[part 2 of 2: packages /CommunicationClusters/BODY3 to /GlobalTimeDomains]
AUTOSAR XML (schema 4-3-0)
# Copyright (c) 2022 Mercedes-Benz AG
package /CommunicationClusters/BODY3  (continued)
  can cluster BODY3: baudrate=250000, protocol-name=CAN, protocol-version=can2.0b  (continued)
    can physical channel BODY3  (continued)
      frame NM_RBTM_FL_ST3: id 0x144201A4, from RBTM_FL, frame-length=8, variation-point=post-build-variant-condition{matching-criterion=Side, value=0}, can-addressing-mode=EXTENDED  # Netzwerk-Management / Network Management
        nm pdu NM_RBTM_FL_ST3: length=8, nm-data-information=true, unused-bit-pattern=0  # STAR3 NM PDU
          signal NM_RBTM_FL_ST3_PNC: start 8, 56 bit, opaque, data-type-policy=OVERRIDE, i-signal-type=ARRAY, init-value=7 x 0, base-type=uint8, transfer-property=PENDING  # PNC_Vector
      frame NM_Dummy_ST3: id 0x14420FFF, to RBTM_FL, frame-length=8, variation-point=post-build-variant-condition{matching-criterion=Side, value=0}, can-addressing-mode=EXTENDED, rx-identifier-range={lower-can-id=339869696, upper-can-id=339873791}  # Netzwerk-Management / Network Management
        nm pdu NM_Dummy_ST3: length=8, nm-data-information=true, unused-bit-pattern=0  # Netzwerk-Management / Network Management
          signal NM_Dummy_ST3_PNC: start 8, 56 bit, opaque, data-type-policy=OVERRIDE, i-signal-type=ARRAY, init-value=7 x 0, base-type=uint8, transfer-property=PENDING  # PNC_Vector
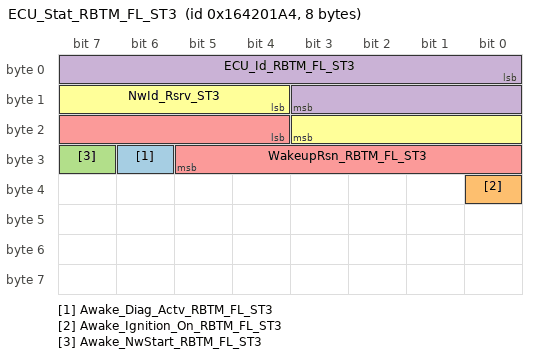
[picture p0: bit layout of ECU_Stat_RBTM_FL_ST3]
      frame ECU_Stat_RBTM_FL_ST3: id 0x164201A4, from RBTM_FL, frame-length=8, variation-point=post-build-variant-condition{matching-criterion=Side, value=0}, can-addressing-mode=EXTENDED  # ECU Status / ECU state
        pdu ECU_Stat_RBTM_FL_ST3: length=8, transmission-mode-true-timing=cyclic-timing={time-offset=0, time-period=1}, unused-bit-pattern=0  # ECU Status / ECU state
          signal Awake_Diag_Actv_RBTM_FL_ST3: start 30, 1 bit, little-endian, data-type-policy=OVERRIDE, i-signal-type=PRIMITIVE, init-value=0, base-type=boolean, transfer-property=PENDING  # Wachhalten für Diagnose aktiv / Stay awake for diagnostics active
          signal Awake_Ignition_On_RBTM_FL_ST3: start 32, 1 bit, little-endian, data-type-policy=OVERRIDE, i-signal-type=PRIMITIVE, init-value=0, base-type=boolean, transfer-property=PENDING  # Wachhalten für Zündung eingeschaltet / Stay awake for ignition on
          signal Awake_NwStart_RBTM_FL_ST3: start 31, 1 bit, little-endian, data-type-policy=OVERRIDE, i-signal-type=PRIMITIVE, init-value=0, base-type=boolean, transfer-property=PENDING  # Wachhalten für Netzwerkstartphase / Stay awake for network startup
          signal ECU_Id_RBTM_FL_ST3: start 0, 12 bit, little-endian, data-type-policy=OVERRIDE, i-signal-type=PRIMITIVE, init-value=420, base-type=uint16, invalid-value=4095, compu-method=c12_0_4094_1_SNA, data-constr=c12_0_4094_1_SNA, transfer-property=PENDING  # ECU-Identifizierungsnummer / ECU identifier
          signal WakeupRsn_RBTM_FL_ST3: start 20, 10 bit, little-endian, data-type-policy=OVERRIDE, i-signal-type=PRIMITIVE, init-value=1023, base-type=uint16, invalid-value=1023, compu-method=c10_WakeupRsn_ST3, data-constr=c10_WakeupRsn_ST3, transfer-property=PENDING  # Weckgrund / Wakeup reason
          signal NwId_Rsrv_ST3: start 12, 8 bit, little-endian, data-type-policy=OVERRIDE, i-signal-type=PRIMITIVE, init-value=0, base-type=uint8, invalid-value=255, compu-method=c08_0_254_1_SNA_255, data-constr=c08_0_254_1_SNA_255, transfer-property=PENDING  # Signal to close the gap in ECU-Stat-PDUs for ECUs w/o NW-ID
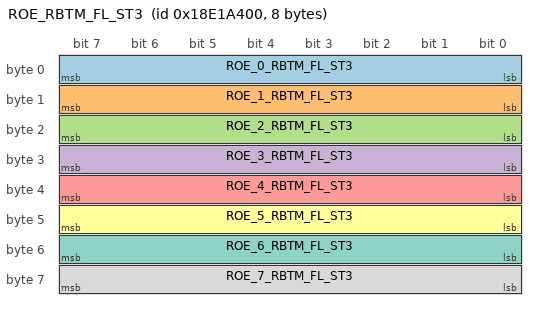
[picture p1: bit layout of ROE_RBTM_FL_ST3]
      frame ROE_RBTM_FL_ST3: id 0x18E1A400, from RBTM_FL, frame-length=8, variation-point=post-build-variant-condition{matching-criterion=Side, value=0}, can-addressing-mode=EXTENDED  # Ereignis-Antwort / Response on Event
        pdu ROE_RBTM_FL_ST3: length=8, minimum-delay=0.2, transmission-mode-true-timing=event-controlled-timing=number-of-repetitions=0, unused-bit-pattern=0  # Ereignis-Antwort / Response on Event
          signal ROE_0_RBTM_FL_ST3: start 0, 8 bit, little-endian, data-type-policy=OVERRIDE, i-signal-type=PRIMITIVE, init-value=0, base-type=uint8, compu-method=c08_ROE_0, data-constr=c08_ROE_0  # Ereignis-Antwort / Response on Event
          signal ROE_1_RBTM_FL_ST3: start 8, 8 bit, little-endian, data-type-policy=OVERRIDE, i-signal-type=PRIMITIVE, init-value=0, base-type=uint8, data-constr=c08_UInt_SNA_na  # Ereignis-Antwort / Response on Event
          signal ROE_2_RBTM_FL_ST3: start 16, 8 bit, little-endian, data-type-policy=OVERRIDE, i-signal-type=PRIMITIVE, init-value=0, base-type=uint8, data-constr=c08_UInt_SNA_na  # Ereignis-Antwort / Response on Event
          signal ROE_3_RBTM_FL_ST3: start 24, 8 bit, little-endian, data-type-policy=OVERRIDE, i-signal-type=PRIMITIVE, init-value=0, base-type=uint8, data-constr=c08_UInt_SNA_na  # Ereignis-Antwort / Response on Event
          signal ROE_4_RBTM_FL_ST3: start 32, 8 bit, little-endian, data-type-policy=OVERRIDE, i-signal-type=PRIMITIVE, init-value=0, base-type=uint8, data-constr=c08_UInt_SNA_na  # Ereignis-Antwort / Response on Event
          signal ROE_5_RBTM_FL_ST3: start 40, 8 bit, little-endian, data-type-policy=OVERRIDE, i-signal-type=PRIMITIVE, init-value=0, base-type=uint8, data-constr=c08_UInt_SNA_na  # Ereignis-Antwort / Response on Event
          signal ROE_6_RBTM_FL_ST3: start 48, 8 bit, little-endian, data-type-policy=OVERRIDE, i-signal-type=PRIMITIVE, init-value=0, base-type=uint8, data-constr=c08_UInt_SNA_na  # Ereignis-Antwort / Response on Event
          signal ROE_7_RBTM_FL_ST3: start 56, 8 bit, little-endian, data-type-policy=OVERRIDE, i-signal-type=PRIMITIVE, init-value=0, base-type=uint8, data-constr=c08_UInt_SNA_na  # Ereignis-Antwort / Response on Event
          mapping ROE_RBTM_FL_ST3_6e0rxnifai2txra0wamb18g4m: i-signal-group=ROE_RBTM_FL_ST3_6e0rxnifai2txra0wamb18g4m, packing-byte-order=little-endian, transfer-property=TRIGGERED
      frame XCP8_Rs_RBTM_FL_ST3: id 0x18E1A408, from RBTM_FL, frame-length=8, variation-point=post-build-variant-condition{matching-criterion=Side, value=0}, can-addressing-mode=EXTENDED
        general purpose i pdu XCP8_Rs_RBTM_FL_ST3: category=XCP, length=8  # XCP-Anforderung / Extended calibration protocol response
      frame XCP8_Rq_RBTM_FL_ST3: id 0x18E1A409, to RBTM_FL, frame-length=8, variation-point=post-build-variant-condition{matching-criterion=Side, value=0}, can-addressing-mode=EXTENDED
        general purpose i pdu XCP8_Rq_RBTM_FL_ST3: category=XCP, length=8  # XCP-Anforderung / Extended calibration protocol request
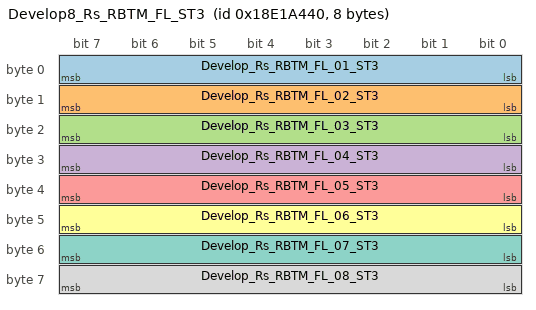
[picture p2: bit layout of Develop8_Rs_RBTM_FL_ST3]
      frame Develop8_Rs_RBTM_FL_ST3: id 0x18E1A440, from RBTM_FL, frame-length=8, variation-point=post-build-variant-condition{matching-criterion=Side, value=0}, can-addressing-mode=EXTENDED  # Development Response
        pdu Develop8_Rs_RBTM_FL_ST3: length=8, minimum-delay=0.02, transmission-mode-true-timing=event-controlled-timing=number-of-repetitions=0, unused-bit-pattern=0  # Development Response
          signal Develop_Rs_RBTM_FL_01_ST3: start 0, 8 bit, little-endian, data-type-policy=OVERRIDE, i-signal-type=PRIMITIVE, init-value=0, base-type=uint8, data-constr=c08_UInt_SNA_na  # Development Response
          signal Develop_Rs_RBTM_FL_02_ST3: start 8, 8 bit, little-endian, data-type-policy=OVERRIDE, i-signal-type=PRIMITIVE, init-value=0, base-type=uint8, data-constr=c08_UInt_SNA_na  # Development Response
          signal Develop_Rs_RBTM_FL_03_ST3: start 16, 8 bit, little-endian, data-type-policy=OVERRIDE, i-signal-type=PRIMITIVE, init-value=0, base-type=uint8, data-constr=c08_UInt_SNA_na  # Development Response
          signal Develop_Rs_RBTM_FL_04_ST3: start 24, 8 bit, little-endian, data-type-policy=OVERRIDE, i-signal-type=PRIMITIVE, init-value=0, base-type=uint8, data-constr=c08_UInt_SNA_na  # Development Response
          signal Develop_Rs_RBTM_FL_05_ST3: start 32, 8 bit, little-endian, data-type-policy=OVERRIDE, i-signal-type=PRIMITIVE, init-value=0, base-type=uint8, data-constr=c08_UInt_SNA_na  # Development Response
          signal Develop_Rs_RBTM_FL_06_ST3: start 40, 8 bit, little-endian, data-type-policy=OVERRIDE, i-signal-type=PRIMITIVE, init-value=0, base-type=uint8, data-constr=c08_UInt_SNA_na  # Development Response
          signal Develop_Rs_RBTM_FL_07_ST3: start 48, 8 bit, little-endian, data-type-policy=OVERRIDE, i-signal-type=PRIMITIVE, init-value=0, base-type=uint8, data-constr=c08_UInt_SNA_na  # Development Response
          signal Develop_Rs_RBTM_FL_08_ST3: start 56, 8 bit, little-endian, data-type-policy=OVERRIDE, i-signal-type=PRIMITIVE, init-value=0, base-type=uint8, data-constr=c08_UInt_SNA_na  # Development Response
          mapping Develop8_Rs_RBTM_FL_ST3_7jg1r8p1skn6yj1t9z2s157vt: i-signal-group=Develop8_Rs_RBTM_FL_ST3_7jg1r8p1skn6yj1t9z2s157vt, packing-byte-order=little-endian, transfer-property=TRIGGERED
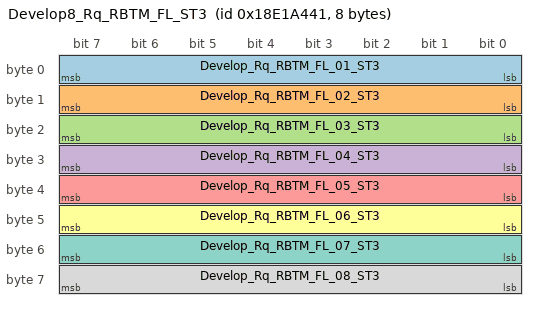
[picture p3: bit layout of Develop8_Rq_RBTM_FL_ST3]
      frame Develop8_Rq_RBTM_FL_ST3: id 0x18E1A441, to RBTM_FL, frame-length=8, variation-point=post-build-variant-condition{matching-criterion=Side, value=0}, can-addressing-mode=EXTENDED  # Development Request
        pdu Develop8_Rq_RBTM_FL_ST3: length=8, minimum-delay=0.02, transmission-mode-true-timing=event-controlled-timing=number-of-repetitions=0, unused-bit-pattern=0  # Development Request
          signal Develop_Rq_RBTM_FL_01_ST3: start 0, 8 bit, little-endian, data-type-policy=OVERRIDE, i-signal-type=PRIMITIVE, init-value=0, base-type=uint8, data-constr=c08_UInt_SNA_na, to RBTM_FL  # Development Request
          signal Develop_Rq_RBTM_FL_02_ST3: start 8, 8 bit, little-endian, data-type-policy=OVERRIDE, i-signal-type=PRIMITIVE, init-value=0, base-type=uint8, data-constr=c08_UInt_SNA_na, to RBTM_FL  # Development Request
          signal Develop_Rq_RBTM_FL_03_ST3: start 16, 8 bit, little-endian, data-type-policy=OVERRIDE, i-signal-type=PRIMITIVE, init-value=0, base-type=uint8, data-constr=c08_UInt_SNA_na, to RBTM_FL  # Development Request
          signal Develop_Rq_RBTM_FL_04_ST3: start 24, 8 bit, little-endian, data-type-policy=OVERRIDE, i-signal-type=PRIMITIVE, init-value=0, base-type=uint8, data-constr=c08_UInt_SNA_na, to RBTM_FL  # Development Request
          signal Develop_Rq_RBTM_FL_05_ST3: start 32, 8 bit, little-endian, data-type-policy=OVERRIDE, i-signal-type=PRIMITIVE, init-value=0, base-type=uint8, data-constr=c08_UInt_SNA_na, to RBTM_FL  # Development Request
          signal Develop_Rq_RBTM_FL_06_ST3: start 40, 8 bit, little-endian, data-type-policy=OVERRIDE, i-signal-type=PRIMITIVE, init-value=0, base-type=uint8, data-constr=c08_UInt_SNA_na, to RBTM_FL  # Development Request
          signal Develop_Rq_RBTM_FL_07_ST3: start 48, 8 bit, little-endian, data-type-policy=OVERRIDE, i-signal-type=PRIMITIVE, init-value=0, base-type=uint8, data-constr=c08_UInt_SNA_na, to RBTM_FL  # Development Request
          signal Develop_Rq_RBTM_FL_08_ST3: start 56, 8 bit, little-endian, data-type-policy=OVERRIDE, i-signal-type=PRIMITIVE, init-value=0, base-type=uint8, data-constr=c08_UInt_SNA_na, to RBTM_FL  # Development Request
          mapping Develop8_Rq_RBTM_FL_ST3_48g6nu8rjjp9s4bhq1x3pz06u: i-signal-group=Develop8_Rq_RBTM_FL_ST3_48g6nu8rjjp9s4bhq1x3pz06u, packing-byte-order=little-endian, transfer-property=TRIGGERED
      frame DIAG_RBTM_FL_03_ExtEth_RS_ST3: id 0x18E1A480, from RBTM_FL, frame-length=8, variation-point=post-build-variant-condition{matching-criterion=Side, value=0}, can-addressing-mode=EXTENDED  # Diagnoseanwort an ExtEth vonRBTM_FL / Diagnostic Response to ExtEth fromRBTM_FL
        n pdu DIAG_RBTM_FL_03_ExtEth_RS_ST3: length=8  # Diagnoseanwort an ExtEth vonRBTM_FL / Diagnostic Response to ExtEth fromRBTM_FL
      frame DIAG_RBTM_FL_03_ExtCAN_RS_ST3: id 0x18E1A481, from RBTM_FL, frame-length=8, variation-point=post-build-variant-condition{matching-criterion=Side, value=0}, can-addressing-mode=EXTENDED  # Diagnoseanwort an ExtCAN vonRBTM_FL / Diagnostic Response to ExtCAN fromRBTM_FL
        n pdu DIAG_RBTM_FL_03_ExtCAN_RS_ST3: length=8  # Diagnoseanwort an ExtCAN vonRBTM_FL / Diagnostic Response to ExtCAN fromRBTM_FL
      frame DIAG_RBTM_FL_03_IntEth_RS_ST3: id 0x18E1A485, from RBTM_FL, frame-length=8, variation-point=post-build-variant-condition{matching-criterion=Side, value=0}, can-addressing-mode=EXTENDED  # Diagnoseanwort an IntEth vonRBTM_FL / Diagnostic Response to IntEth fromRBTM_FL
        n pdu DIAG_RBTM_FL_03_IntEth_RS_ST3: length=8  # Diagnoseanwort an IntEth vonRBTM_FL / Diagnostic Response to IntEth fromRBTM_FL
      frame DIAG_RBTM_FL_03_ExtEth_RQ_ST3: id 0x18E1A488, to RBTM_FL, frame-length=8, variation-point=post-build-variant-condition{matching-criterion=Side, value=0}, can-addressing-mode=EXTENDED  # Diagnoseanfrage vom ExtEth fürRBTM_FL / Diagnostic Request from ExtEth forRBTM_FL
        n pdu DIAG_RBTM_FL_03_ExtEth_RQ_ST3: length=8  # Diagnoseanfrage vom ExtEth fürRBTM_FL / Diagnostic Request from ExtEth forRBTM_FL
      frame DIAG_RBTM_FL_03_ExtCAN_RQ_ST3: id 0x18E1A489, to RBTM_FL, frame-length=8, variation-point=post-build-variant-condition{matching-criterion=Side, value=0}, can-addressing-mode=EXTENDED  # Diagnoseanfrage vom ExtCAN fürRBTM_FL / Diagnostic Request from ExtCAN forRBTM_FL
        n pdu DIAG_RBTM_FL_03_ExtCAN_RQ_ST3: length=8  # Diagnoseanfrage vom ExtCAN fürRBTM_FL / Diagnostic Request from ExtCAN forRBTM_FL
      frame DIAG_RBTM_FL_03_IntEth_RQ_ST3: id 0x18E1A48D, to RBTM_FL, frame-length=8, variation-point=post-build-variant-condition{matching-criterion=Side, value=0}, can-addressing-mode=EXTENDED  # Diagnoseanfrage vom IntEth fürRBTM_FL / Diagnostic Request from IntEth forRBTM_FL
        n pdu DIAG_RBTM_FL_03_IntEth_RQ_ST3: length=8  # Diagnoseanfrage vom IntEth fürRBTM_FL / Diagnostic Request from IntEth forRBTM_FL
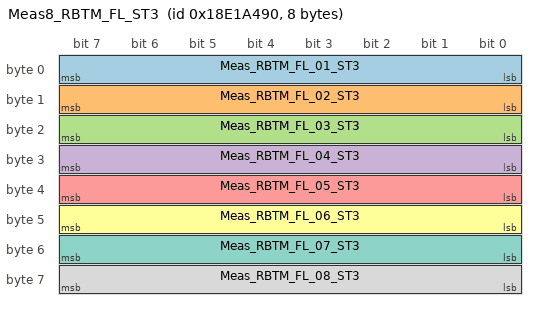
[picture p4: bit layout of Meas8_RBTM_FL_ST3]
      frame Meas8_RBTM_FL_ST3: id 0x18E1A490, from RBTM_FL, frame-length=8, variation-point=post-build-variant-condition{matching-criterion=Side, value=0}, can-addressing-mode=EXTENDED  # Messbotschaft / Measurement
        pdu Meas8_RBTM_FL_ST3: length=8, minimum-delay=0.02, transmission-mode-true-timing=event-controlled-timing=number-of-repetitions=0, unused-bit-pattern=0  # Messbotschaft / Measurement
          signal Meas_RBTM_FL_01_ST3: start 0, 8 bit, little-endian, data-type-policy=OVERRIDE, i-signal-type=PRIMITIVE, init-value=0, base-type=uint8, data-constr=c08_UInt_SNA_na  # Messsignal / Measurement
          signal Meas_RBTM_FL_02_ST3: start 8, 8 bit, little-endian, data-type-policy=OVERRIDE, i-signal-type=PRIMITIVE, init-value=0, base-type=uint8, data-constr=c08_UInt_SNA_na  # Messsignal / Measurement
          signal Meas_RBTM_FL_03_ST3: start 16, 8 bit, little-endian, data-type-policy=OVERRIDE, i-signal-type=PRIMITIVE, init-value=0, base-type=uint8, data-constr=c08_UInt_SNA_na  # Messsignal / Measurement
          signal Meas_RBTM_FL_04_ST3: start 24, 8 bit, little-endian, data-type-policy=OVERRIDE, i-signal-type=PRIMITIVE, init-value=0, base-type=uint8, data-constr=c08_UInt_SNA_na  # Messsignal / Measurement
          signal Meas_RBTM_FL_05_ST3: start 32, 8 bit, little-endian, data-type-policy=OVERRIDE, i-signal-type=PRIMITIVE, init-value=0, base-type=uint8, data-constr=c08_UInt_SNA_na  # Messsignal / Measurement
          signal Meas_RBTM_FL_06_ST3: start 40, 8 bit, little-endian, data-type-policy=OVERRIDE, i-signal-type=PRIMITIVE, init-value=0, base-type=uint8, data-constr=c08_UInt_SNA_na  # Messsignal / Measurement
          signal Meas_RBTM_FL_07_ST3: start 48, 8 bit, little-endian, data-type-policy=OVERRIDE, i-signal-type=PRIMITIVE, init-value=0, base-type=uint8, data-constr=c08_UInt_SNA_na  # Messsignal / Measurement
          signal Meas_RBTM_FL_08_ST3: start 56, 8 bit, little-endian, data-type-policy=OVERRIDE, i-signal-type=PRIMITIVE, init-value=0, base-type=uint8, data-constr=c08_UInt_SNA_na  # Messsignal / Measurement
          mapping Meas8_RBTM_FL_ST3_72jyquhuktrmjm0hkqempja37: i-signal-group=Meas8_RBTM_FL_ST3_72jyquhuktrmjm0hkqempja37, packing-byte-order=little-endian, transfer-property=TRIGGERED
      frame DIAG_RQ_GLOBAL_ExtEth_ST3: id 0x18EEF888, to RBTM_FL, frame-length=8, variation-point=post-build-variant-condition{matching-criterion=Side, value=0}, can-addressing-mode=EXTENDED  # Funktionaler Diagnose-Request vom Off-Board Tester (via Ethernet) / Functional Diagnostic Request from Off-Board Tester (via Ethernet)
        n pdu DIAG_RQ_GLOBAL_ExtEth_ST3: length=8  # Funktionale Diagnoseanfrage (UDS) vom ExtEth / Functional Diagnostic Request (UDS) from ExtEth
      frame DIAG_RQ_GLOBAL_ExtCAN_ST3: id 0x18EEF989, to RBTM_FL, frame-length=8, variation-point=post-build-variant-condition{matching-criterion=Side, value=0}, can-addressing-mode=EXTENDED  # Funktionaler Diagnose-Request vom Off-Board Tester (via CAN) / Functional Diagnostic Request from Off-Board Tester (via CAN)
        n pdu DIAG_RQ_GLOBAL_ExtCAN_ST3: length=8  # Funktionale Diagnoseanfrage (UDS) vom ExtCAN / Functional Diagnostic Request (UDS) from ExtCAN
      frame DIAG_RQ_GLOBAL_IntEth_ST3: id 0x18EF0D8D, to RBTM_FL, frame-length=8, variation-point=post-build-variant-condition{matching-criterion=Side, value=0}, can-addressing-mode=EXTENDED  # Funktionaler Diagnose-Request vom On-Board Tester (via Ethernet) / Functional Diagnostic Request from On-Board Tester (via Ethernet)
        n pdu DIAG_RQ_GLOBAL_IntEth_ST3: length=8  # Funktionale Diagnoseanfrage (UDS) vom IntEth / Functional Diagnostic Request (UDS) from IntEth
      frame GTS_Main_CAN_ST3: id 0x79, to RBTM_FL, frame-length=8, variation-point=post-build-variant-condition{matching-criterion=Side, value=1}, can-addressing-mode=STANDARD  # Status Uhrsynchronisation / Clock synchronisation state
        carries pdu GTS_Main_CAN_ST3: packing-byte-order=big-endian, start-position=7
        general purpose pdu GTS_Main_CAN_ST3: category=GLOBAL_TIME, length=8  # Status Uhrsynchronisation / Clock synchronisation state
      frame Ign_Stat_ST3: id 0x7F, to RBTM_FL, frame-length=8, variation-point=post-build-variant-condition{matching-criterion=Side, value=1}, can-addressing-mode=STANDARD  # Zuendungsstatus / Ignition state
        carries pdu Ign_Stat_ST3_secured: packing-byte-order=little-endian, start-position=0
        secured i pdu Ign_Stat_ST3_secured: length=8, authentication-props=SECOC_AP_CMAC_AES_128_24, freshness-props=SECOC_FP_10000_40_8_true, payload=BODY3/Ign_Stat_ST3_c09z9xhxqu9sge34n30m1bi02, secure-communication-props={authentication-retries=0, data-id=28212, freshness-value-id=1}
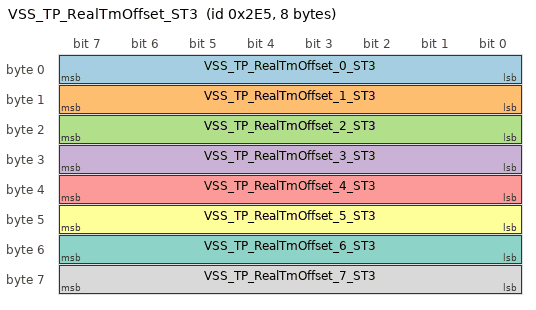
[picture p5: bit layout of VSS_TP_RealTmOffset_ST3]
      frame VSS_TP_RealTmOffset_ST3: id 0x2E5, to RBTM_FL, frame-length=8, variation-point=post-build-variant-condition{matching-criterion=Side, value=1}, can-addressing-mode=STANDARD  # VSS-Transportprotokoll für Echtzeit-Offset / Vehicle Security System Transport Protocol for real time offset broadcast
        carries pdu VSS_TP_RealTmOffset_ST3: packing-byte-order=little-endian, start-position=0
        pdu VSS_TP_RealTmOffset_ST3: length=8, minimum-delay=0.02, transmission-mode-true-timing=event-controlled-timing=number-of-repetitions=0, unused-bit-pattern=255  # VSS-Transportprotokoll für Echtzeit-Offset / Vehicle Security System Transport Protocol for real time offset broadcast
          signal VSS_TP_RealTmOffset_0_ST3: start 0, 8 bit, little-endian, data-type-policy=OVERRIDE, i-signal-type=PRIMITIVE, init-value=255, base-type=uint8, data-constr=c08_UInt_SNA_na, to RBTM_FL  # VSS-Transportprotokoll für Echtzeit-Offset, Byte 0 / Vehicle Security System Transport Protocol for real time offset broadcast, Byte 0
          signal VSS_TP_RealTmOffset_1_ST3: start 8, 8 bit, little-endian, data-type-policy=OVERRIDE, i-signal-type=PRIMITIVE, init-value=255, base-type=uint8, data-constr=c08_UInt_SNA_na, to RBTM_FL  # VSS-Transportprotokoll für Echtzeit-Offset, Byte 1 / Vehicle Security System Transport Protocol for real time offset broadcast, Byte 1
          signal VSS_TP_RealTmOffset_2_ST3: start 16, 8 bit, little-endian, data-type-policy=OVERRIDE, i-signal-type=PRIMITIVE, init-value=255, base-type=uint8, data-constr=c08_UInt_SNA_na, to RBTM_FL  # VSS-Transportprotokoll für Echtzeit-Offset, Byte 2 / Vehicle Security System Transport Protocol for real time offset broadcast, Byte 2
          signal VSS_TP_RealTmOffset_3_ST3: start 24, 8 bit, little-endian, data-type-policy=OVERRIDE, i-signal-type=PRIMITIVE, init-value=255, base-type=uint8, data-constr=c08_UInt_SNA_na, to RBTM_FL  # VSS-Transportprotokoll für Echtzeit-Offset, Byte 3 / Vehicle Security System Transport Protocol for real time offset broadcast, Byte 3
          signal VSS_TP_RealTmOffset_4_ST3: start 32, 8 bit, little-endian, data-type-policy=OVERRIDE, i-signal-type=PRIMITIVE, init-value=255, base-type=uint8, data-constr=c08_UInt_SNA_na, to RBTM_FL  # VSS-Transportprotokoll für Echtzeit-Offset, Byte 4 / Vehicle Security System Transport Protocol for real time offset broadcast, Byte 4
          signal VSS_TP_RealTmOffset_5_ST3: start 40, 8 bit, little-endian, data-type-policy=OVERRIDE, i-signal-type=PRIMITIVE, init-value=255, base-type=uint8, data-constr=c08_UInt_SNA_na, to RBTM_FL  # VSS-Transportprotokoll für Echtzeit-Offset, Byte 5 / Vehicle Security System Transport Protocol for real time offset broadcast, Byte 5
          signal VSS_TP_RealTmOffset_6_ST3: start 48, 8 bit, little-endian, data-type-policy=OVERRIDE, i-signal-type=PRIMITIVE, init-value=255, base-type=uint8, data-constr=c08_UInt_SNA_na, to RBTM_FL  # VSS-Transportprotokoll für Echtzeit-Offset, Byte 6 / Vehicle Security System Transport Protocol for real time offset broadcast, Byte 6
          signal VSS_TP_RealTmOffset_7_ST3: start 56, 8 bit, little-endian, data-type-policy=OVERRIDE, i-signal-type=PRIMITIVE, init-value=255, base-type=uint8, data-constr=c08_UInt_SNA_na, to RBTM_FL  # VSS-Transportprotokoll für Echtzeit-Offset, Byte 7 / Vehicle Security System Transport Protocol for real time offset broadcast, Byte 7
          mapping VSS_TP_RealTmOffset_ST3_1t7vc44gftc0wv35k5kgc2in9: i-signal-group=VSS_TP_RealTmOffset_ST3_1t7vc44gftc0wv35k5kgc2in9, packing-byte-order=little-endian, transfer-property=TRIGGERED
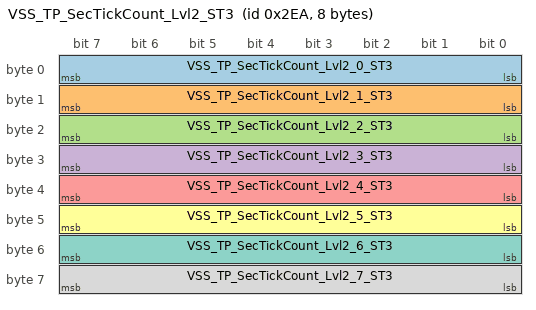
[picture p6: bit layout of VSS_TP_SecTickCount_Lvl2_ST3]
      frame VSS_TP_SecTickCount_Lvl2_ST3: id 0x2EA, to RBTM_FL, frame-length=8, variation-point=post-build-variant-condition{matching-criterion=Side, value=1}, can-addressing-mode=STANDARD  # VSS-Transportprotokoll für sichere Zeit Stufe 2 / Vehicle Security System Transport Protocol for secure tick count level #2
        carries pdu VSS_TP_SecTickCount_Lvl2_ST3: packing-byte-order=little-endian, start-position=0
        pdu VSS_TP_SecTickCount_Lvl2_ST3: length=8, minimum-delay=0.02, transmission-mode-true-timing=event-controlled-timing=number-of-repetitions=0, unused-bit-pattern=255  # VSS-Transportprotokoll für sichere Zeit Stufe 2 / Vehicle Security System Transport Protocol for secure tick count level #2
          signal VSS_TP_SecTickCount_Lvl2_0_ST3: start 0, 8 bit, little-endian, data-type-policy=OVERRIDE, i-signal-type=PRIMITIVE, init-value=255, base-type=uint8, data-constr=c08_UInt_SNA_na, to RBTM_FL  # VSS-Transportprotokoll für sichere Zeit Stufe 2, Byte 0 / Vehicle Security System Transport Protocol for secure tick count level #2, Byte 0
          signal VSS_TP_SecTickCount_Lvl2_1_ST3: start 8, 8 bit, little-endian, data-type-policy=OVERRIDE, i-signal-type=PRIMITIVE, init-value=255, base-type=uint8, data-constr=c08_UInt_SNA_na, to RBTM_FL  # VSS-Transportprotokoll für sichere Zeit Stufe 2, Byte 1 / Vehicle Security System Transport Protocol for secure tick count level #2, Byte 1
          signal VSS_TP_SecTickCount_Lvl2_2_ST3: start 16, 8 bit, little-endian, data-type-policy=OVERRIDE, i-signal-type=PRIMITIVE, init-value=255, base-type=uint8, data-constr=c08_UInt_SNA_na, to RBTM_FL  # VSS-Transportprotokoll für sichere Zeit Stufe 2, Byte 2 / Vehicle Security System Transport Protocol for secure tick count level #2, Byte 2
          signal VSS_TP_SecTickCount_Lvl2_3_ST3: start 24, 8 bit, little-endian, data-type-policy=OVERRIDE, i-signal-type=PRIMITIVE, init-value=255, base-type=uint8, data-constr=c08_UInt_SNA_na, to RBTM_FL  # VSS-Transportprotokoll für sichere Zeit Stufe 2, Byte 3 / Vehicle Security System Transport Protocol for secure tick count level #2, Byte 3
          signal VSS_TP_SecTickCount_Lvl2_4_ST3: start 32, 8 bit, little-endian, data-type-policy=OVERRIDE, i-signal-type=PRIMITIVE, init-value=255, base-type=uint8, data-constr=c08_UInt_SNA_na, to RBTM_FL  # VSS-Transportprotokoll für sichere Zeit Stufe 2, Byte 4 / Vehicle Security System Transport Protocol for secure tick count level #2, Byte 4
          signal VSS_TP_SecTickCount_Lvl2_5_ST3: start 40, 8 bit, little-endian, data-type-policy=OVERRIDE, i-signal-type=PRIMITIVE, init-value=255, base-type=uint8, data-constr=c08_UInt_SNA_na, to RBTM_FL  # VSS-Transportprotokoll für sichere Zeit Stufe 2, Byte 5 / Vehicle Security System Transport Protocol for secure tick count level #2, Byte 5
          signal VSS_TP_SecTickCount_Lvl2_6_ST3: start 48, 8 bit, little-endian, data-type-policy=OVERRIDE, i-signal-type=PRIMITIVE, init-value=255, base-type=uint8, data-constr=c08_UInt_SNA_na, to RBTM_FL  # VSS-Transportprotokoll für sichere Zeit Stufe 2, Byte 6 / Vehicle Security System Transport Protocol for secure tick count level #2, Byte 6
          signal VSS_TP_SecTickCount_Lvl2_7_ST3: start 56, 8 bit, little-endian, data-type-policy=OVERRIDE, i-signal-type=PRIMITIVE, init-value=255, base-type=uint8, data-constr=c08_UInt_SNA_na, to RBTM_FL  # VSS-Transportprotokoll für sichere Zeit Stufe 2, Byte 7 / Vehicle Security System Transport Protocol for secure tick count level #2, Byte 7
          mapping VSS_TP_SecTickCount_Lvl2_ST3_9eubq13iosat764o0lqh5xb6r: i-signal-group=VSS_TP_SecTickCount_Lvl2_ST3_9eubq13iosat764o0lqh5xb6r, packing-byte-order=little-endian, transfer-property=TRIGGERED
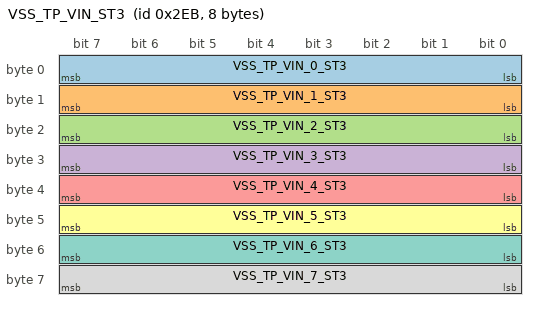
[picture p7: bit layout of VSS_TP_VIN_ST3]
      frame VSS_TP_VIN_ST3: id 0x2EB, to RBTM_FL, frame-length=8, variation-point=post-build-variant-condition{matching-criterion=Side, value=1}, can-addressing-mode=STANDARD  # VSS-Transportprotokoll für Fahrzeugidentifikationsnummer / Vehicle Security System Transport Protocol for Vehicle Identification Number
        carries pdu VSS_TP_VIN_ST3: packing-byte-order=little-endian, start-position=0
        pdu VSS_TP_VIN_ST3: length=8, minimum-delay=0.02, transmission-mode-true-timing=event-controlled-timing=number-of-repetitions=0, unused-bit-pattern=255  # VSS-Transportprotokoll für Fahrzeugidentifikationsnummer / Vehicle Security System Transport Protocol for Vehicle Identification Number
          signal VSS_TP_VIN_0_ST3: start 0, 8 bit, little-endian, data-type-policy=OVERRIDE, i-signal-type=PRIMITIVE, init-value=63, base-type=uint8, data-constr=c08_UInt_SNA_na, to RBTM_FL  # VSS-Transportprotokoll für Fahrzeugidentifikationsnummer, Byte 0 / Vehicle Security System Transport Protocol for Vehicle Identification Number, Byte 0
          signal VSS_TP_VIN_1_ST3: start 8, 8 bit, little-endian, data-type-policy=OVERRIDE, i-signal-type=PRIMITIVE, init-value=63, base-type=uint8, data-constr=c08_UInt_SNA_na, to RBTM_FL  # VSS-Transportprotokoll für Fahrzeugidentifikationsnummer, Byte 1 / Vehicle Security System Transport Protocol for Vehicle Identification Number, Byte 1
          signal VSS_TP_VIN_2_ST3: start 16, 8 bit, little-endian, data-type-policy=OVERRIDE, i-signal-type=PRIMITIVE, init-value=63, base-type=uint8, data-constr=c08_UInt_SNA_na, to RBTM_FL  # VSS-Transportprotokoll für Fahrzeugidentifikationsnummer, Byte 2 / Vehicle Security System Transport Protocol for Vehicle Identification Number, Byte 2
          signal VSS_TP_VIN_3_ST3: start 24, 8 bit, little-endian, data-type-policy=OVERRIDE, i-signal-type=PRIMITIVE, init-value=63, base-type=uint8, data-constr=c08_UInt_SNA_na, to RBTM_FL  # VSS-Transportprotokoll für Fahrzeugidentifikationsnummer, Byte 3 / Vehicle Security System Transport Protocol for Vehicle Identification Number, Byte 3
          signal VSS_TP_VIN_4_ST3: start 32, 8 bit, little-endian, data-type-policy=OVERRIDE, i-signal-type=PRIMITIVE, init-value=63, base-type=uint8, data-constr=c08_UInt_SNA_na, to RBTM_FL  # VSS-Transportprotokoll für Fahrzeugidentifikationsnummer, Byte 4 / Vehicle Security System Transport Protocol for Vehicle Identification Number, Byte 4
          signal VSS_TP_VIN_5_ST3: start 40, 8 bit, little-endian, data-type-policy=OVERRIDE, i-signal-type=PRIMITIVE, init-value=63, base-type=uint8, data-constr=c08_UInt_SNA_na, to RBTM_FL  # VSS-Transportprotokoll für Fahrzeugidentifikationsnummer, Byte 5 / Vehicle Security System Transport Protocol for Vehicle Identification Number, Byte 5
          signal VSS_TP_VIN_6_ST3: start 48, 8 bit, little-endian, data-type-policy=OVERRIDE, i-signal-type=PRIMITIVE, init-value=63, base-type=uint8, data-constr=c08_UInt_SNA_na, to RBTM_FL  # VSS-Transportprotokoll für Fahrzeugidentifikationsnummer, Byte 6 / Vehicle Security System Transport Protocol for Vehicle Identification Number, Byte 6
          signal VSS_TP_VIN_7_ST3: start 56, 8 bit, little-endian, data-type-policy=OVERRIDE, i-signal-type=PRIMITIVE, init-value=63, base-type=uint8, data-constr=c08_UInt_SNA_na, to RBTM_FL  # VSS-Transportprotokoll für Fahrzeugidentifikationsnummer, Byte 7 / Vehicle Security System Transport Protocol for Vehicle Identification Number, Byte 7
          mapping VSS_TP_VIN_ST3_bz1xsv84cxzl09j028gn39p69: i-signal-group=VSS_TP_VIN_ST3_bz1xsv84cxzl09j028gn39p69, packing-byte-order=little-endian, transfer-property=TRIGGERED
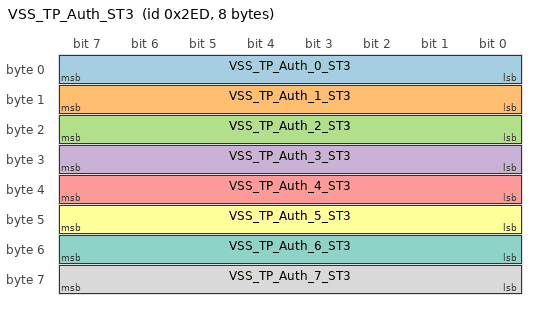
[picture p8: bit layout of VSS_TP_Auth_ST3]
      frame VSS_TP_Auth_ST3: id 0x2ED, to RBTM_FL, frame-length=8, variation-point=post-build-variant-condition{matching-criterion=Side, value=1}, can-addressing-mode=STANDARD  # VSS-Transportprotokoll für Authentifizierung / Vehicle Security System Transport Protocol for authentication broadcast
        carries pdu VSS_TP_Auth_ST3: packing-byte-order=little-endian, start-position=0
        pdu VSS_TP_Auth_ST3: length=8, minimum-delay=0.02, transmission-mode-true-timing=event-controlled-timing=number-of-repetitions=0, unused-bit-pattern=255  # VSS-Transportprotokoll für Authentifizierung / Vehicle Security System Transport Protocol for authentication broadcast
          signal VSS_TP_Auth_0_ST3: start 0, 8 bit, little-endian, data-type-policy=OVERRIDE, i-signal-type=PRIMITIVE, init-value=255, base-type=uint8, data-constr=c08_UInt_SNA_na, to RBTM_FL  # VSS-Transportprotokoll für Authentifizierung, Byte 0 / Vehicle Security System Transport Protocol for authentication broadcast, Byte 0
          signal VSS_TP_Auth_1_ST3: start 8, 8 bit, little-endian, data-type-policy=OVERRIDE, i-signal-type=PRIMITIVE, init-value=255, base-type=uint8, data-constr=c08_UInt_SNA_na, to RBTM_FL  # VSS-Transportprotokoll für Authentifizierung, Byte 1 / Vehicle Security System Transport Protocol for authentication broadcast, Byte 1
          signal VSS_TP_Auth_2_ST3: start 16, 8 bit, little-endian, data-type-policy=OVERRIDE, i-signal-type=PRIMITIVE, init-value=255, base-type=uint8, data-constr=c08_UInt_SNA_na, to RBTM_FL  # VSS-Transportprotokoll für Authentifizierung, Byte 2 / Vehicle Security System Transport Protocol for authentication broadcast, Byte 2
          signal VSS_TP_Auth_3_ST3: start 24, 8 bit, little-endian, data-type-policy=OVERRIDE, i-signal-type=PRIMITIVE, init-value=255, base-type=uint8, data-constr=c08_UInt_SNA_na, to RBTM_FL  # VSS-Transportprotokoll für Authentifizierung, Byte 3 / Vehicle Security System Transport Protocol for authentication broadcast, Byte 3
          signal VSS_TP_Auth_4_ST3: start 32, 8 bit, little-endian, data-type-policy=OVERRIDE, i-signal-type=PRIMITIVE, init-value=255, base-type=uint8, data-constr=c08_UInt_SNA_na, to RBTM_FL  # VSS-Transportprotokoll für Authentifizierung, Byte 4 / Vehicle Security System Transport Protocol for authentication broadcast, Byte 4
          signal VSS_TP_Auth_5_ST3: start 40, 8 bit, little-endian, data-type-policy=OVERRIDE, i-signal-type=PRIMITIVE, init-value=255, base-type=uint8, data-constr=c08_UInt_SNA_na, to RBTM_FL  # VSS-Transportprotokoll für Authentifizierung, Byte 5 / Vehicle Security System Transport Protocol for authentication broadcast, Byte 5
          signal VSS_TP_Auth_6_ST3: start 48, 8 bit, little-endian, data-type-policy=OVERRIDE, i-signal-type=PRIMITIVE, init-value=255, base-type=uint8, data-constr=c08_UInt_SNA_na, to RBTM_FL  # VSS-Transportprotokoll für Authentifizierung, Byte 6 / Vehicle Security System Transport Protocol for authentication broadcast, Byte 6
          signal VSS_TP_Auth_7_ST3: start 56, 8 bit, little-endian, data-type-policy=OVERRIDE, i-signal-type=PRIMITIVE, init-value=255, base-type=uint8, data-constr=c08_UInt_SNA_na, to RBTM_FL  # VSS-Transportprotokoll für Authentifizierung, Byte 7 / Vehicle Security System Transport Protocol for authentication broadcast, Byte 7
          mapping VSS_TP_Auth_ST3_6j4id7sghlvlbroli4wjozjik: i-signal-group=VSS_TP_Auth_ST3_6j4id7sghlvlbroli4wjozjik, packing-byte-order=little-endian, transfer-property=TRIGGERED
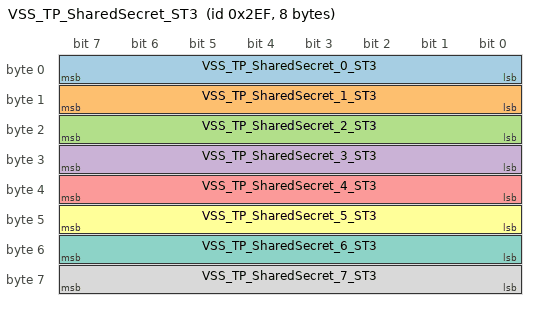
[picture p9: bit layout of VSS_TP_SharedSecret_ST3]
      frame VSS_TP_SharedSecret_ST3: id 0x2EF, to RBTM_FL, frame-length=8, variation-point=post-build-variant-condition{matching-criterion=Side, value=1}, can-addressing-mode=STANDARD  # VSS-Transportprotokoll für gemeinsames Geheimnis / Vehicle Security System Transport Protocol for shared secret broadcast
        carries pdu VSS_TP_SharedSecret_ST3: packing-byte-order=little-endian, start-position=0
        pdu VSS_TP_SharedSecret_ST3: length=8, minimum-delay=0.02, transmission-mode-true-timing=event-controlled-timing=number-of-repetitions=0, unused-bit-pattern=255  # VSS-Transportprotokoll für gemeinsames Geheimnis / Vehicle Security System Transport Protocol for shared secret broadcast
          signal VSS_TP_SharedSecret_0_ST3: start 0, 8 bit, little-endian, data-type-policy=OVERRIDE, i-signal-type=PRIMITIVE, init-value=255, base-type=uint8, data-constr=c08_UInt_SNA_na, to RBTM_FL  # VSS-Transportprotokoll für gemeinsames Geheimnis, Byte 0 / Vehicle Security System Transport Protocol for shared secret broadcast, Byte 0
          signal VSS_TP_SharedSecret_1_ST3: start 8, 8 bit, little-endian, data-type-policy=OVERRIDE, i-signal-type=PRIMITIVE, init-value=255, base-type=uint8, data-constr=c08_UInt_SNA_na, to RBTM_FL  # VSS-Transportprotokoll für gemeinsames Geheimnis, Byte 1 / Vehicle Security System Transport Protocol for shared secret broadcast, Byte 1
          signal VSS_TP_SharedSecret_2_ST3: start 16, 8 bit, little-endian, data-type-policy=OVERRIDE, i-signal-type=PRIMITIVE, init-value=255, base-type=uint8, data-constr=c08_UInt_SNA_na, to RBTM_FL  # VSS-Transportprotokoll für gemeinsames Geheimnis, Byte 2 / Vehicle Security System Transport Protocol for shared secret broadcast, Byte 2
          signal VSS_TP_SharedSecret_3_ST3: start 24, 8 bit, little-endian, data-type-policy=OVERRIDE, i-signal-type=PRIMITIVE, init-value=255, base-type=uint8, data-constr=c08_UInt_SNA_na, to RBTM_FL  # VSS-Transportprotokoll für gemeinsames Geheimnis, Byte 3 / Vehicle Security System Transport Protocol for shared secret broadcast, Byte 3
          signal VSS_TP_SharedSecret_4_ST3: start 32, 8 bit, little-endian, data-type-policy=OVERRIDE, i-signal-type=PRIMITIVE, init-value=255, base-type=uint8, data-constr=c08_UInt_SNA_na, to RBTM_FL  # VSS-Transportprotokoll für gemeinsames Geheimnis, Byte 4 / Vehicle Security System Transport Protocol for shared secret broadcast, Byte 4
          signal VSS_TP_SharedSecret_5_ST3: start 40, 8 bit, little-endian, data-type-policy=OVERRIDE, i-signal-type=PRIMITIVE, init-value=255, base-type=uint8, data-constr=c08_UInt_SNA_na, to RBTM_FL  # VSS-Transportprotokoll für gemeinsames Geheimnis, Byte 5 / Vehicle Security System Transport Protocol for shared secret broadcast, Byte 5
          signal VSS_TP_SharedSecret_6_ST3: start 48, 8 bit, little-endian, data-type-policy=OVERRIDE, i-signal-type=PRIMITIVE, init-value=255, base-type=uint8, data-constr=c08_UInt_SNA_na, to RBTM_FL  # VSS-Transportprotokoll für gemeinsames Geheimnis, Byte 6 / Vehicle Security System Transport Protocol for shared secret broadcast, Byte 6
          signal VSS_TP_SharedSecret_7_ST3: start 56, 8 bit, little-endian, data-type-policy=OVERRIDE, i-signal-type=PRIMITIVE, init-value=255, base-type=uint8, data-constr=c08_UInt_SNA_na, to RBTM_FL  # VSS-Transportprotokoll für gemeinsames Geheimnis, Byte 7 / Vehicle Security System Transport Protocol for shared secret broadcast, Byte 7
          mapping VSS_TP_SharedSecret_ST3_8pj4t8t4rm3tw3pk5hj7vonti: i-signal-group=VSS_TP_SharedSecret_ST3_8pj4t8t4rm3tw3pk5hj7vonti, packing-byte-order=little-endian, transfer-property=TRIGGERED
      frame PT4_PTCoor9_d1_BC_F_ST3: id 0x304, to RBTM_FL, frame-length=1, variation-point=post-build-variant-condition{matching-criterion=Side, value=1}, can-addressing-mode=STANDARD  # PT4 PT Coor 9 ST3 - Degraded PDU
        carries pdu PT4_PTCoor9_d1_BC_F_ST3: packing-byte-order=little-endian, start-position=0
        pdu PT4_PTCoor9_d1_BC_F_ST3: length=1, minimum-delay=0.02, transmission-mode-true-timing={cyclic-timing={time-offset=0.005, time-period=1}, event-controlled-timing=number-of-repetitions=0}, unused-bit-pattern=255  # PT4 PT Coor 9 ST3 - Degraded PDU
          signal PT4_PTCoor_Accel_Md_ST3: start 0, 3 bit, little-endian, data-type-policy=OVERRIDE, i-signal-type=PRIMITIVE, init-value=7, base-type=uint8, invalid-value=7, compu-method=c03_Accel_Md_ST3, data-constr=c03_Accel_Md_ST3, to RBTM_FL(timeout 5.1 s)  # Aktueller Beschleunigungsmodus(Nur in AMG Modellen verfügbar) / Acceleration Modes(Only provided in AMG models)
          mapping PT4_PTCoor9_Pr5_ST3_6r95o81sst3tk9w2lzz600cw3: i-signal-group=PT4_PTCoor9_Pr5_ST3_6r95o81sst3tk9w2lzz600cw3, packing-byte-order=little-endian, transfer-property=TRIGGERED-ON-CHANGE, update-indication-bit-position=7
      frame SBeltTens_SP_Lvl_ST3: id 0x30E, to RBTM_FL, frame-length=8, variation-point=post-build-variant-condition{matching-criterion=Side, value=1}, can-addressing-mode=STANDARD  # Seat Belt Tensioner SP Lvl ST3
        carries pdu SBeltTens_SP_Lvl_ST3: packing-byte-order=little-endian, start-position=0
        pdu SBeltTens_SP_Lvl_ST3: length=8, minimum-delay=0.02, transmission-mode-true-timing={cyclic-timing={time-offset=0.08, time-period=0.2}, event-controlled-timing=number-of-repetitions=0}, unused-bit-pattern=255  # Seat Belt Tensioner SP Lvl ST3
          signal CRC_SBeltTens_SP_Lvl_Pr5_ST3: start 0, 16 bit, little-endian, data-type-policy=OVERRIDE, i-signal-type=PRIMITIVE, init-value=10339, base-type=uint16, data-constr=c16_CRC_woSNA, transfer-property=PENDING, to RBTM_FL(timeout 2 s)  # CRC-Checksumme der Signal Gruppe gemäß AUTOSAR Profil 5 / CRC-checksum of signal group according to AUTOSAR Profile 5
          signal RBTMFL_SP_Lvl_Rq_ST35: start 24, 6 bit, little-endian, data-type-policy=OVERRIDE, i-signal-type=PRIMITIVE, init-value=0, base-type=uint8, invalid-value=63, compu-method=c06_RBTM_LVL_Rq, data-constr=c06_RBTM_LVL_Rq, transfer-property=TRIGGERED-ON-CHANGE, variation-point=post-build-variant-condition{matching-criterion=Side, value=0}, to RBTM_FL(timeout 2 s) RBTM_FL  # Straffprofil Anforderung durch Seatbelt Service Provider vorne links / Tensioning profile request from Seatbelt Service Provider front left
          signal SQC_SBeltTens_SP_Lvl_Pr5_ST3: start 16, 8 bit, little-endian, data-type-policy=OVERRIDE, i-signal-type=PRIMITIVE, init-value=0, base-type=uint8, compu-method=none_1_0, data-constr=c08_0_255_1_SNA_na, transfer-property=PENDING, to RBTM_FL(timeout 2 s)  # Sequenzzähler / Sequence counter
          signal RBTMFR_SP_Lvl_Rq_ST35: start 30, 6 bit, little-endian, data-type-policy=OVERRIDE, i-signal-type=PRIMITIVE, init-value=0, base-type=uint8, invalid-value=63, compu-method=c06_RBTM_LVL_Rq, data-constr=c06_RBTM_LVL_Rq, transfer-property=PENDING, variation-point=post-build-variant-condition{matching-criterion=Side, value=0}, to RBTM_FL RBTM_FL(timeout 2 s)  # Straffprofil Anforderung durch Seatbelt Service Provider vorne rechts / Tensioning profile request from Seatbelt Service Provider front right
          signal Rsrv0_SBeltTens_SP_Lvl_Pr5_ST3: start 36, 4 bit, little-endian, data-type-policy=OVERRIDE, i-signal-type=PRIMITIVE, init-value=15, base-type=uint8, invalid-value=15, data-constr=Rsrv04, transfer-property=PENDING, to RBTM_FL  # Reserviert für zukünftige Verwendung / Reserved for future use
          mapping SBeltTens_SP_Lvl_Pr5_ST3_4tqpkri37441o5ht9g9ekmyzh: i-signal-group=SBeltTens_SP_Lvl_Pr5_ST3_4tqpkri37441o5ht9g9ekmyzh, packing-byte-order=little-endian, transfer-property=TRIGGERED-ON-CHANGE
          signal RBTMFR_SP_Lvl_Rq_ST35: start 30, 6 bit, little-endian, data-type-policy=OVERRIDE, i-signal-type=PRIMITIVE, init-value=0, base-type=uint8, invalid-value=63, compu-method=c06_RBTM_LVL_Rq, data-constr=c06_RBTM_LVL_Rq, transfer-property=TRIGGERED-ON-CHANGE, variation-point=post-build-variant-condition{matching-criterion=Side, value=1}, to RBTM_FL RBTM_FL(timeout 2 s)  # Straffprofil Anforderung durch Seatbelt Service Provider vorne rechts / Tensioning profile request from Seatbelt Service Provider front right
          signal RBTMFL_SP_Lvl_Rq_ST35: start 24, 6 bit, little-endian, data-type-policy=OVERRIDE, i-signal-type=PRIMITIVE, init-value=0, base-type=uint8, invalid-value=63, compu-method=c06_RBTM_LVL_Rq, data-constr=c06_RBTM_LVL_Rq, transfer-property=PENDING, variation-point=post-build-variant-condition{matching-criterion=Side, value=1}, to RBTM_FL(timeout 2 s) RBTM_FL  # Straffprofil Anforderung durch Seatbelt Service Provider vorne links / Tensioning profile request from Seatbelt Service Provider front left
      frame RBTM_FR_Tens_ST3: id 0x310, from RBTM_FL, frame-length=8, variation-point=post-build-variant-condition{matching-criterion=Side, value=1}, can-addressing-mode=STANDARD  # RBTM Vorne Rechts Tens ST3 / RBTM Front Right Tens ST3
        pdu RBTM_FR_Tens_ST3: length=8, minimum-delay=0.02, transmission-mode-true-timing={cyclic-timing={time-offset=0.005, time-period=0.5}, event-controlled-timing=number-of-repetitions=0}, unused-bit-pattern=255  # RBTM Vorne Rechts Tens ST3 / RBTM Front Right Tens ST3
          signal RBTMFR_Actv_Lvl_ST35: start 10, 6 bit, little-endian, data-type-policy=OVERRIDE, i-signal-type=PRIMITIVE, init-value=0, base-type=uint8, invalid-value=63, compu-method=c06_RBTM_Lvl_Stat, data-constr=c06_RBTM_Lvl_Stat, transfer-property=TRIGGERED-ON-CHANGE  # aktives Straffprofil vorne rechts / active seatbelt tensioning profile front right
          signal RBTMFR_SP_ActvClient_ST35: start 16, 4 bit, little-endian, data-type-policy=OVERRIDE, i-signal-type=PRIMITIVE, init-value=0, base-type=uint8, invalid-value=15, compu-method=c04_RBTM_ActvClient, data-constr=c04_RBTM_ActvClient, transfer-property=TRIGGERED-ON-CHANGE  # Anforderungsquelle aktive Gurtstraffung vorne rechts / Active seatbelt tensioning request source front right
          signal RBTMFR_SP_FctPrecond_Stat_ST35: start 0, 10 bit, little-endian, data-type-policy=OVERRIDE, i-signal-type=PRIMITIVE, init-value=0, base-type=uint16, compu-method=c10_RBTM_Fct_Precond, transfer-property=TRIGGERED-ON-CHANGE  # Nicht erfüllten Funktionsbedingungen für rev. Gurtstraffung vorne rechts / List of unfulfilled preconditions for rev. seatbelt tensioning front right
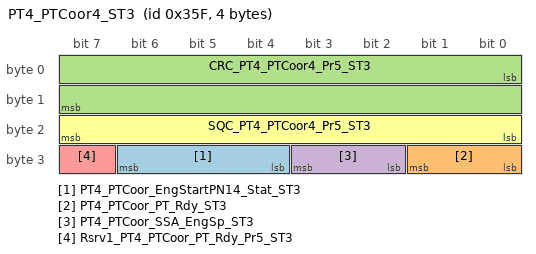
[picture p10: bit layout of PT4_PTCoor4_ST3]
      frame PT4_PTCoor4_ST3: id 0x35F, to RBTM_FL, frame-length=4, variation-point=post-build-variant-condition{matching-criterion=Side, value=1}, can-addressing-mode=STANDARD
        carries pdu PT4_PTCoor4_ST3: packing-byte-order=little-endian, start-position=0
        pdu PT4_PTCoor4_ST3: length=4, minimum-delay=0.01, transmission-mode-true-timing={cyclic-timing=time-period=0.1, event-controlled-timing=number-of-repetitions=0}, unused-bit-pattern=255
          signal PT4_PTCoor_EngStartPN14_Stat_ST3: start 28, 3 bit, little-endian, data-type-policy=OVERRIDE, i-signal-type=PRIMITIVE, init-value=0, base-type=uint8, invalid-value=7, compu-method=c03_EngStartPN14_Stat, data-constr=c03_EngStartPN14_Stat, to RBTM_FL(timeout 1.05 s)  # Status PN14 bei Motorstart / PT4 Engine Start PN14 State
          signal PT4_PTCoor_PT_Rdy_ST3: start 24, 2 bit, little-endian, data-type-policy=OVERRIDE, i-signal-type=PRIMITIVE, init-value=0, base-type=uint8, invalid-value=3, compu-method=c02_PT_Rdy_V2, data-constr=c02_PT_Rdy_V2, to RBTM_FL(timeout 1.05 s)  # Antrieb bereit / Powertrain ready
          signal CRC_PT4_PTCoor4_Pr5_ST3: start 0, 16 bit, little-endian, data-type-policy=OVERRIDE, i-signal-type=PRIMITIVE, init-value=4203, base-type=uint16, data-constr=c16_CRC_woSNA, transfer-property=PENDING  # CRC-Checksumme der Signal Gruppe gemäß AUTOSAR Profil 5 / CRC-checksum of signal group according to AUTOSAR Profile 5
          signal PT4_PTCoor_SSA_EngSp_ST3: start 26, 2 bit, little-endian, data-type-policy=OVERRIDE, i-signal-type=PRIMITIVE, init-value=3, base-type=uint8, invalid-value=3, compu-method=c02_Ndef_False_True_ST3, data-constr=c02_Ndef_False_True_ST3, transfer-property=PENDING  # ASS Motorstopp / Stop/start automatic has engine stopped
          signal Rsrv1_PT4_PTCoor_PT_Rdy_Pr5_ST3: start 31, 1 bit, little-endian, data-type-policy=OVERRIDE, i-signal-type=PRIMITIVE, init-value=1, base-type=uint8, invalid-value=1, data-constr=Rsrv01, transfer-property=PENDING  # Reserviert für zukünftige Verwendung / Reserved for future use
          signal SQC_PT4_PTCoor4_Pr5_ST3: start 16, 8 bit, little-endian, data-type-policy=OVERRIDE, i-signal-type=PRIMITIVE, init-value=0, base-type=uint8, compu-method=none_1_0, data-constr=c08_0_255_1_SNA_na, transfer-property=PENDING  # Sequenzzähler / Sequence counter
          mapping PT4_PTCoor4_Pr5_ST3_af4fxb1ykieox3itqdfzs0kpb: i-signal-group=PT4_PTCoor4_Pr5_ST3_af4fxb1ykieox3itqdfzs0kpb, packing-byte-order=little-endian, transfer-property=TRIGGERED-ON-CHANGE
      frame Impact2_ST3: id 0x463, to RBTM_FL, frame-length=8, variation-point=post-build-variant-condition{matching-criterion=Side, value=1}, can-addressing-mode=STANDARD  # ORC Impact 2 ST3
        carries pdu Impact2_ST3_secured: packing-byte-order=little-endian, start-position=0
        secured i pdu Impact2_ST3_secured: length=8, authentication-props=SECOC_AP_CMAC_AES_128_24, freshness-props=SECOC_FP_10000_40_8_true, payload=BODY3/Impact2_ST3_tiwfvn1jg3r3k32jv8naa5uv, secure-communication-props={authentication-retries=0, data-id=27103, freshness-value-id=1}
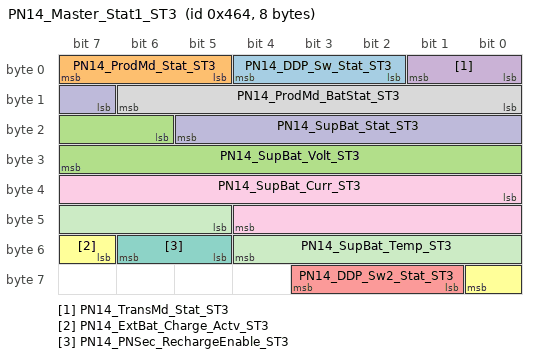
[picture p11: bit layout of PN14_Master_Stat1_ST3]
      frame PN14_Master_Stat1_ST3: id 0x464, to RBTM_FL, frame-length=8, variation-point=post-build-variant-condition{matching-criterion=Side, value=1}, can-addressing-mode=STANDARD  # Status 12V Bordnetz Master / Powernetwork 12V master state
        carries pdu PN14_Master_Stat1_ST3: packing-byte-order=little-endian, start-position=0
        pdu PN14_Master_Stat1_ST3: length=8, transmission-mode-true-timing=cyclic-timing=time-period=0.2, unused-bit-pattern=255  # Status 12V Bordnetz Master / Powernetwork 12V master state
          signal PN14_DDP_Sw_Stat_ST3: start 2, 3 bit, little-endian, data-type-policy=OVERRIDE, i-signal-type=PRIMITIVE, init-value=0, base-type=uint8, invalid-value=7, compu-method=c03_PN14_TDP_Sw_Stat, data-constr=c03_PN14_TDP_Sw_Stat, transfer-property=PENDING, to RBTM_FL  # Schalterstatus Tiefentladeschutz / Deep discharge protection switch state
          signal PN14_ProdMd_Stat_ST3: start 5, 3 bit, little-endian, data-type-policy=OVERRIDE, i-signal-type=PRIMITIVE, init-value=7, base-type=uint8, invalid-value=7, compu-method=c03_PN14_ProdMd_Stat_ST3, data-constr=c03_PN14_ProdMd_Stat_ST3, transfer-property=PENDING, to RBTM_FL  # Status des Bordnetz Produktionsmodus / Powernet production mode state
          signal PN14_SupBat_Volt_ST3: start 22, 10 bit, little-endian, data-type-policy=OVERRIDE, i-signal-type=PRIMITIVE, init-value=1023, base-type=uint16, invalid-value=1023, compu-method=c10_V_0_25k55_0k025, data-constr=c10_V_0_25k55_0k025, transfer-property=PENDING, to RBTM_FL  # Versorgungsbatterie Istspannung / Supply battery voltage
          signal PN14_TransMd_Stat_ST3: start 0, 2 bit, little-endian, data-type-policy=OVERRIDE, i-signal-type=PRIMITIVE, init-value=3, base-type=uint8, invalid-value=3, compu-method=c02_TransMd_Stat, data-constr=c02_TransMd_Stat, transfer-property=PENDING, to RBTM_FL  # Bordnetz Status Transportmodus / Powernet transport mode status
          signal PN14_DDP_Sw2_Stat_ST3: start 57, 3 bit, little-endian, data-type-policy=OVERRIDE, i-signal-type=PRIMITIVE, init-value=7, base-type=uint8, invalid-value=7, compu-method=c03_PN14_TDP_Sw_Stat, data-constr=c03_PN14_TDP_Sw_Stat, transfer-property=PENDING  # Schalterstatus DDP Switch 2 (Always On Switch) / State of DDP Switch2 (Always On Switch)
          signal PN14_ExtBat_Charge_Actv_ST3: start 55, 2 bit, little-endian, data-type-policy=OVERRIDE, i-signal-type=PRIMITIVE, init-value=3, base-type=uint8, invalid-value=3, compu-method=c02_Ndef_False_True_ST3, data-constr=c02_Ndef_False_True_ST3, transfer-property=PENDING  # Externe Batterieladung erkannt / external barttery charging detected
          signal PN14_PNSec_RechargeEnable_ST3: start 53, 2 bit, little-endian, data-type-policy=OVERRIDE, i-signal-type=PRIMITIVE, init-value=3, base-type=uint8, invalid-value=3, compu-method=c02_Ndef_False_True_ST3, data-constr=c02_Ndef_False_True_ST3, transfer-property=PENDING  # Freigabe zum Nachladen der Sekundärbatterie / Enable for Recharge Secondary-Batterie
          signal PN14_ProdMd_BatStat_ST3: start 8, 7 bit, little-endian, data-type-policy=OVERRIDE, i-signal-type=PRIMITIVE, init-value=127, base-type=uint8, invalid-value=127, compu-method=c07_per_0to100_1_SNA, data-constr=c07_per_0to100_1_SNA, transfer-property=PENDING  # Der aktuelle Status der 12V Versorgungsbatterie während Produktions-Mode. / Actual 12V battery state during production mode
          signal PN14_SupBat_Curr_ST3: start 32, 13 bit, little-endian, data-type-policy=OVERRIDE, i-signal-type=PRIMITIVE, init-value=8191, base-type=uint16, invalid-value=8191, compu-method=c13_A_m409k6_409k4_0k1, data-constr=c13_A_m409k6_409k4_0k1, transfer-property=PENDING  # Versorgungsbatterie Iststrom / Supply battery current
          signal PN14_SupBat_Stat_ST3: start 15, 7 bit, little-endian, data-type-policy=OVERRIDE, i-signal-type=PRIMITIVE, init-value=127, base-type=uint8, invalid-value=127, compu-method=c07_0_111_1_SNA, data-constr=c07_0_111_1_SNA, transfer-property=PENDING  # Status Versorgungsbatterie / Supply battery state
          signal PN14_SupBat_Temp_ST3: start 45, 8 bit, little-endian, data-type-policy=OVERRIDE, i-signal-type=PRIMITIVE, init-value=255, base-type=uint8, invalid-value=255, compu-method=c08_degC_m40_85_0k5, data-constr=c08_degC_m40_85_0k5, transfer-property=PENDING  # Temperatur Versorgungsbatterie / Supply battery temperature
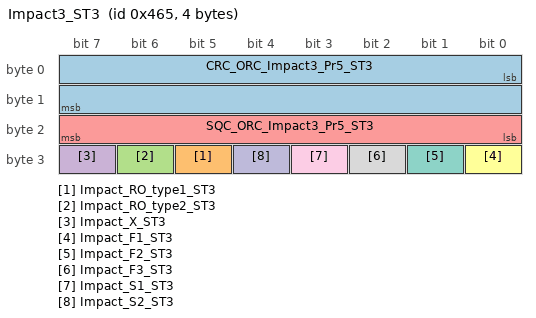
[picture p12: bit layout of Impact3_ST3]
      frame Impact3_ST3: id 0x465, to RBTM_FL, frame-length=4, variation-point=post-build-variant-condition{matching-criterion=Side, value=1}, can-addressing-mode=STANDARD  # ORC Impact 3 ST3
        carries pdu Impact3_ST3: packing-byte-order=little-endian, start-position=0
        pdu Impact3_ST3: length=4, minimum-delay=0.02, transmission-mode-false-timing=cyclic-timing=time-period=0.05, transmission-mode-true-timing=cyclic-timing=time-period=0.02, unused-bit-pattern=255  # ORC Impact 3 ST3
          transmission-mode-conditions:
            {data-filter={data-filter-type=MASKED-NEW-DIFFERS-X, mask=1, x=0}, i-signal-in-i-pdu=Impact_RO_type1_ST3}
            {data-filter={data-filter-type=MASKED-NEW-DIFFERS-X, mask=1, x=0}, i-signal-in-i-pdu=Impact_RO_type2_ST3}
            {data-filter={data-filter-type=MASKED-NEW-DIFFERS-X, mask=1, x=0}, i-signal-in-i-pdu=Impact_X_ST3}
          signal CRC_ORC_Impact3_Pr5_ST3: start 0, 16 bit, little-endian, data-type-policy=OVERRIDE, i-signal-type=PRIMITIVE, init-value=11251, base-type=uint16, data-constr=c16_CRC_woSNA, to RBTM_FL  # CRC-Checksumme der Signal Gruppe gemäß AUTOSAR Profil 5 / CRC-checksum of signal group according to AUTOSAR Profile 5
          signal Impact_RO_type1_ST3: start 29, 1 bit, little-endian, data-type-policy=OVERRIDE, i-signal-type=PRIMITIVE, init-value=0, base-type=boolean, to RBTM_FL  # Rollover mittels Drehratensensorik / rollover type 1
          signal Impact_RO_type2_ST3: start 30, 1 bit, little-endian, data-type-policy=OVERRIDE, i-signal-type=PRIMITIVE, init-value=0, base-type=boolean, to RBTM_FL  # Rollover mittels Beschleunigungssensorik / rollover type 2
          signal Impact_X_ST3: start 31, 1 bit, little-endian, data-type-policy=OVERRIDE, i-signal-type=PRIMITIVE, init-value=0, base-type=boolean, to RBTM_FL  # Beliebiges Crashereignis vorhanden / Any impact event
          signal SQC_ORC_Impact3_Pr5_ST3: start 16, 8 bit, little-endian, data-type-policy=OVERRIDE, i-signal-type=PRIMITIVE, init-value=0, base-type=uint8, compu-method=none_1_0, data-constr=c08_0_255_1_SNA_na, to RBTM_FL  # Sequenzzähler / Sequence counter
          signal Impact_F1_ST3: start 24, 1 bit, little-endian, data-type-policy=OVERRIDE, i-signal-type=PRIMITIVE, init-value=0, base-type=boolean, to RBTM_FL  # Frontalaufprall Stufe 1 / Collision front level 1
          signal Impact_F2_ST3: start 25, 1 bit, little-endian, data-type-policy=OVERRIDE, i-signal-type=PRIMITIVE, init-value=0, base-type=boolean, to RBTM_FL  # Frontalaufprall Stufe 2 / Collision front level 2
          signal Impact_F3_ST3: start 26, 1 bit, little-endian, data-type-policy=OVERRIDE, i-signal-type=PRIMITIVE, init-value=0, base-type=boolean, to RBTM_FL  # Frontalaufprall Stufe 3 / Collision front level 3
          signal Impact_S1_ST3: start 27, 1 bit, little-endian, data-type-policy=OVERRIDE, i-signal-type=PRIMITIVE, init-value=0, base-type=boolean, to RBTM_FL  # Seitenaufprall Stufe 1 / Collision side level 1
          signal Impact_S2_ST3: start 28, 1 bit, little-endian, data-type-policy=OVERRIDE, i-signal-type=PRIMITIVE, init-value=0, base-type=boolean, to RBTM_FL  # Seitenaufprall Stufe 2 / Collision side level 2
          mapping ORC_Impact3_Pr5_ST3_c4pqnkonfjwv3uiohsxhe9dwu: i-signal-group=ORC_Impact3_Pr5_ST3_c4pqnkonfjwv3uiohsxhe9dwu, packing-byte-order=little-endian, transfer-property=PENDING
      frame ADAS_PROFILE_SHORT_ST3: id 0x53D, to RBTM_FL, frame-length=8, variation-point=post-build-variant-condition{matching-criterion=Side, value=1}, can-addressing-mode=STANDARD
        carries pdu ADAS_PROFILE_SHORT_ST3: packing-byte-order=little-endian, start-position=0
        multiplexed i pdu ADAS_PROFILE_SHORT_ST3:
          length=8
          dynamic-part{segment-position{segment-byte-order=little-endian, segment-length=64, segment-position=0}, dynamic-part-alternatives=[{i-pdu=ADAS_PROFILE_SHORT_ST3_1, initial-dynamic-part=false, selector-field-code=1}, {i-pdu=ADAS_PROFILE_SHORT_ST3_31, initial-dynamic-part=true, selector-field-code=31}]}
          selector-field-byte-order=little-endian
          selector-field-length=5
          selector-field-start-position=27
          trigger-mode=DYNAMIC-PART-TRIGGER
          unused-bit-pattern=255
      frame DI_OdoSpeedometer_ST3: id 0x565, to RBTM_FL, frame-length=8, variation-point=post-build-variant-condition{matching-criterion=Side, value=1}, can-addressing-mode=STANDARD  # Fahrerinformation Odometer und Tacho / DriverInformation Odometer and speedometer
        carries pdu DI_OdoSpeedometer_ST3: packing-byte-order=little-endian, start-position=0
        pdu DI_OdoSpeedometer_ST3: length=8, minimum-delay=0.1, transmission-mode-true-timing={cyclic-timing=time-period=1, event-controlled-timing=number-of-repetitions=0}, unused-bit-pattern=255  # Fahrerinformation Odometer und Tacho / DriverInformation Odometer and speedometer
          signal Odo_ST3: start 24, 24 bit, little-endian, data-type-policy=OVERRIDE, i-signal-type=PRIMITIVE, init-value=16777215, base-type=uint32, invalid-value=16777215, compu-method=c24_km_0_999999k9_0k1_Invld_SNA, data-constr=c24_km_0_999999k9_0k1_Invld_SNA, to RBTM_FL  # Kilometerstand (für alle) / Odometer (for everyone)
          signal VehSpd_Disp_ST3: start 48, 12 bit, little-endian, data-type-policy=OVERRIDE, i-signal-type=PRIMITIVE, init-value=4095, base-type=uint16, invalid-value=4095, compu-method=c12_km_p_h_0_409k4_0k1, data-constr=c12_km_p_h_0_409k4_0k1, transfer-property=TRIGGERED-ON-CHANGE, to RBTM_FL(timeout 10.5 s)  # Angezeigte Geschwindigkeit (ohne Zeigerdämpfung) / Displayed vehicle speed (without attenuation)
          signal CRC_DI_Odo_Pr5_ST3: start 0, 16 bit, little-endian, data-type-policy=OVERRIDE, i-signal-type=PRIMITIVE, init-value=8633, base-type=uint16, data-constr=c16_CRC_woSNA, transfer-property=PENDING  # CRC-Checksumme der Signal Gruppe gemäß AUTOSAR Profil 5 / CRC-checksum of signal group according to AUTOSAR Profile 5
          signal SQC_DI_Odo_Pr5_ST3: start 16, 8 bit, little-endian, data-type-policy=OVERRIDE, i-signal-type=PRIMITIVE, init-value=0, base-type=uint8, compu-method=none_1_0, data-constr=c08_0_255_1_SNA_na, transfer-property=PENDING  # Sequenzzähler / Sequence counter
          mapping DI_Odo_Pr5_ST3_e68xmtlkywxgxsdwekdjjhw3t: i-signal-group=DI_Odo_Pr5_ST3_e68xmtlkywxgxsdwekdjjhw3t, packing-byte-order=little-endian, transfer-property=TRIGGERED-ON-CHANGE, update-indication-bit-position=63
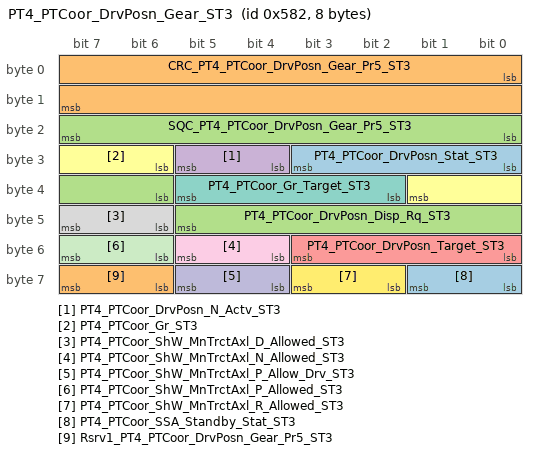
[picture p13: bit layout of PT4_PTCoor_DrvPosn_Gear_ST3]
      frame PT4_PTCoor_DrvPosn_Gear_ST3: id 0x582, to RBTM_FL, frame-length=8, variation-point=post-build-variant-condition{matching-criterion=Side, value=1}, can-addressing-mode=STANDARD  # PT4 PT Coor Drv Position Gear / PT4 PT Coor Drv position Gear
        carries pdu PT4_PTCoor_DrvPosn_Gear_ST3: packing-byte-order=little-endian, start-position=0
        pdu PT4_PTCoor_DrvPosn_Gear_ST3: length=8, minimum-delay=0.02, transmission-mode-true-timing={cyclic-timing={time-offset=0.03, time-period=0.1}, event-controlled-timing=number-of-repetitions=0}, unused-bit-pattern=255  # PT4 PT Coor Drv Position Gear ST3 / PT4 PT Coor Drv position Gear ST3
          signal PT4_PTCoor_DrvPosn_Stat_ST3: start 24, 4 bit, little-endian, data-type-policy=OVERRIDE, i-signal-type=PRIMITIVE, init-value=15, base-type=uint8, invalid-value=15, compu-method=c04_DrvPosn_ST3, data-constr=c04_DrvPosn_ST3, to RBTM_FL  # Powertrain Fahrstufe / Powertrain Driving Position
          signal CRC_PT4_PTCoor_DrvPosn_Gear_Pr5_ST3: start 0, 16 bit, little-endian, data-type-policy=OVERRIDE, i-signal-type=PRIMITIVE, init-value=47286, base-type=uint16, data-constr=c16_CRC_woSNA, transfer-property=PENDING  # CRC-Checksumme der Signal Gruppe gemäß AUTOSAR Profil 5 / CRC-checksum of signal group according to AUTOSAR Profile 5
          signal PT4_PTCoor_DrvPosn_Disp_Rq_ST3: start 38, 8 bit, little-endian, data-type-policy=OVERRIDE, i-signal-type=PRIMITIVE, init-value=255, base-type=uint8, invalid-value=255, compu-method=c08_TxDrvPosn, data-constr=c08_TxDrvPosn, transfer-property=PENDING  # Anforderung Anzeige Getriebefahrstufe / Transmission driving position display request
          signal PT4_PTCoor_DrvPosn_N_Actv_ST3: start 28, 2 bit, little-endian, data-type-policy=OVERRIDE, i-signal-type=PRIMITIVE, init-value=3, base-type=uint8, invalid-value=3, compu-method=c02_Inact_Act_ST3, data-constr=c02_Inact_Act_ST3, transfer-property=PENDING  # Fahrerwunsch "N" einlegen / Transmission neutral position request by driver
          signal PT4_PTCoor_DrvPosn_Target_ST3: start 48, 4 bit, little-endian, data-type-policy=OVERRIDE, i-signal-type=PRIMITIVE, init-value=15, base-type=uint8, invalid-value=15, compu-method=c04_DrvPosn_ST3, data-constr=c04_DrvPosn_ST3, transfer-property=PENDING  # Powertrain Zielfahrstufe / Powertrain commanded driving position
          signal PT4_PTCoor_Gr_ST3: start 30, 4 bit, little-endian, data-type-policy=OVERRIDE, i-signal-type=PRIMITIVE, init-value=15, base-type=uint8, invalid-value=15, compu-method=c04_Gr, data-constr=c04_Gr, transfer-property=PENDING  # Ist-Gang Powertrain zu Fahrzeug / Actual gear
          signal PT4_PTCoor_Gr_Target_ST3: start 34, 4 bit, little-endian, data-type-policy=OVERRIDE, i-signal-type=PRIMITIVE, init-value=15, base-type=uint8, invalid-value=15, compu-method=c04_Gr_Target, data-constr=c04_Gr_Target, transfer-property=PENDING  # Ziel-Gang / Target gear
          signal PT4_PTCoor_ShW_MnTrctAxl_D_Allowed_ST3: start 46, 2 bit, little-endian, data-type-policy=OVERRIDE, i-signal-type=PRIMITIVE, init-value=3, base-type=uint8, invalid-value=3, compu-method=c02_Ndef_False_True_ST3, data-constr=c02_Ndef_False_True_ST3, transfer-property=PENDING  # Hauptantriebsachse: Fahrposition D erlaubt / Main traction axle driving position D is allowed
          signal PT4_PTCoor_ShW_MnTrctAxl_N_Allowed_ST3: start 52, 2 bit, little-endian, data-type-policy=OVERRIDE, i-signal-type=PRIMITIVE, init-value=3, base-type=uint8, invalid-value=3, compu-method=c02_Ndef_False_True_ST3, data-constr=c02_Ndef_False_True_ST3, transfer-property=PENDING  # Hauptantriebsachse: Fahrposition N erlaubt / Main traction axle driving position N is allowed
          signal PT4_PTCoor_ShW_MnTrctAxl_P_Allow_Drv_ST3: start 60, 2 bit, little-endian, data-type-policy=OVERRIDE, i-signal-type=PRIMITIVE, init-value=3, base-type=uint8, invalid-value=3, compu-method=c02_Ndef_False_True_ST3, data-constr=c02_Ndef_False_True_ST3, transfer-property=PENDING  # Hauptantriebsachse: Fahrposition P für Fahrer zum Einlegen erlaubt / Main traction axle driving position P is allowed for driver to engange
          signal PT4_PTCoor_ShW_MnTrctAxl_P_Allowed_ST3: start 54, 2 bit, little-endian, data-type-policy=OVERRIDE, i-signal-type=PRIMITIVE, init-value=3, base-type=uint8, invalid-value=3, compu-method=c02_Ndef_False_True_ST3, data-constr=c02_Ndef_False_True_ST3, transfer-property=PENDING  # Hauptantriebsachse: Fahrposition P erlaubt / Main traction axle driving position P is allowed
          signal PT4_PTCoor_ShW_MnTrctAxl_R_Allowed_ST3: start 58, 2 bit, little-endian, data-type-policy=OVERRIDE, i-signal-type=PRIMITIVE, init-value=3, base-type=uint8, invalid-value=3, compu-method=c02_Ndef_False_True_ST3, data-constr=c02_Ndef_False_True_ST3, transfer-property=PENDING  # Hauptantriebsachse: Fahrposition R erlaubt / Main traction axle driving position R is allowed
          signal PT4_PTCoor_SSA_Standby_Stat_ST3: start 56, 2 bit, little-endian, data-type-policy=OVERRIDE, i-signal-type=PRIMITIVE, init-value=0, base-type=uint8, invalid-value=3, compu-method=c02_SSA_Standby_Stat, data-constr=c02_SSA_Standby_Stat, transfer-property=PENDING  # Stop Start Standby Status
          signal Rsrv1_PT4_PTCoor_DrvPosn_Gear_Pr5_ST3: start 62, 2 bit, little-endian, data-type-policy=OVERRIDE, i-signal-type=PRIMITIVE, init-value=3, base-type=uint8, invalid-value=3, data-constr=Rsrv02, transfer-property=PENDING  # Reserviert für zukünftige Verwendung / Reserved for future use
          signal SQC_PT4_PTCoor_DrvPosn_Gear_Pr5_ST3: start 16, 8 bit, little-endian, data-type-policy=OVERRIDE, i-signal-type=PRIMITIVE, init-value=0, base-type=uint8, compu-method=none_1_0, data-constr=c08_0_255_1_SNA_na, transfer-property=PENDING  # Sequenzzähler / Sequence counter
          mapping PT4_PTCoor_DrvPosn_Gear_Pr5_ST3_5p8cvrni3ypvuac33rj2asfy9: i-signal-group=PT4_PTCoor_DrvPosn_Gear_Pr5_ST3_5p8cvrni3ypvuac33rj2asfy9, packing-byte-order=little-endian, transfer-property=TRIGGERED-ON-CHANGE
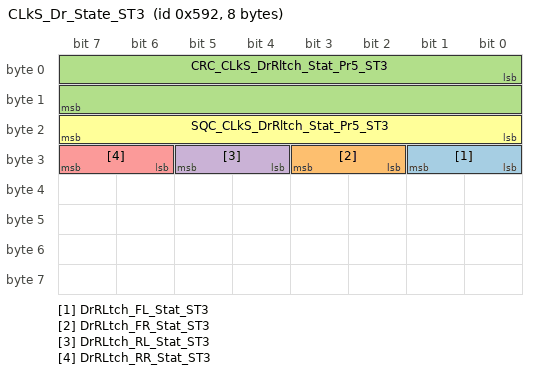
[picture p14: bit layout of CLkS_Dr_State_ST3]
      frame CLkS_Dr_State_ST3: id 0x592, to RBTM_FL, frame-length=8, variation-point=post-build-variant-condition{matching-criterion=Side, value=1}, can-addressing-mode=STANDARD  # Status Zentralverriegelung Türen / Central Locking System door state
        carries pdu CLkS_Dr_State_ST3: packing-byte-order=little-endian, start-position=0
        pdu CLkS_Dr_State_ST3: length=8, minimum-delay=0.02, transmission-mode-true-timing={cyclic-timing=time-period=0.1, event-controlled-timing=number-of-repetitions=0}, unused-bit-pattern=255  # Status Zentralverriegelung Türen / Central Locking System door state
          signal DrRLtch_FL_Stat_ST3: start 24, 2 bit, little-endian, data-type-policy=OVERRIDE, i-signal-type=PRIMITIVE, init-value=3, base-type=uint8, invalid-value=3, compu-method=c02_Dr_Stat, data-constr=c02_Dr_Stat, to RBTM_FL  # Status Drehfalle Tür vorne links / Rotary latch door front left state
          signal DrRLtch_FR_Stat_ST3: start 26, 2 bit, little-endian, data-type-policy=OVERRIDE, i-signal-type=PRIMITIVE, init-value=3, base-type=uint8, invalid-value=3, compu-method=c02_Dr_Stat, data-constr=c02_Dr_Stat, to RBTM_FL  # Status Drehfalle Tür vorne rechts / Rotary latch door front right state
          signal CRC_CLkS_DrRltch_Stat_Pr5_ST3: start 0, 16 bit, little-endian, data-type-policy=OVERRIDE, i-signal-type=PRIMITIVE, init-value=18640, base-type=uint16, data-constr=c16_CRC_woSNA, transfer-property=PENDING  # CRC-Checksumme der Signal Gruppe gemäß AUTOSAR Profil 5 / CRC-checksum of signal group according to AUTOSAR Profile 5
          signal DrRLtch_RL_Stat_ST3: start 28, 2 bit, little-endian, data-type-policy=OVERRIDE, i-signal-type=PRIMITIVE, init-value=3, base-type=uint8, invalid-value=3, compu-method=c02_Dr_Stat, data-constr=c02_Dr_Stat, transfer-property=PENDING  # Status Drehfalle Tür hinten links / Rotary latch door rear left state
          signal DrRLtch_RR_Stat_ST3: start 30, 2 bit, little-endian, data-type-policy=OVERRIDE, i-signal-type=PRIMITIVE, init-value=3, base-type=uint8, invalid-value=3, compu-method=c02_Dr_Stat, data-constr=c02_Dr_Stat, transfer-property=PENDING  # Status Drehfalle Tür hinten rechts / Rotary latch door rear right state
          signal SQC_CLkS_DrRltch_Stat_Pr5_ST3: start 16, 8 bit, little-endian, data-type-policy=OVERRIDE, i-signal-type=PRIMITIVE, init-value=0, base-type=uint8, compu-method=none_1_0, data-constr=c08_0_255_1_SNA_na, transfer-property=PENDING  # Sequenzzähler / Sequence counter
          mapping CLkS_DrRltch_Stat_Pr5_ST3_7at68qvnk0r9npofyykyfq82v: i-signal-group=CLkS_DrRltch_Stat_Pr5_ST3_7at68qvnk0r9npofyykyfq82v, packing-byte-order=little-endian, transfer-property=TRIGGERED-ON-CHANGE
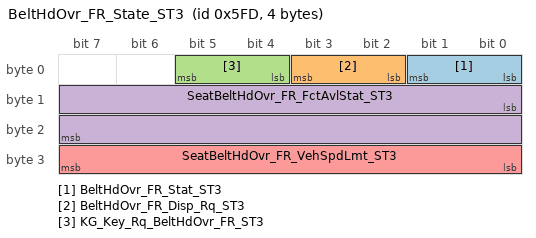
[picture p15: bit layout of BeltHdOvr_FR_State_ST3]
      frame BeltHdOvr_FR_State_ST3: id 0x5FD, to RBTM_FL, frame-length=4, variation-point=post-build-variant-condition{matching-criterion=Side, value=1}, can-addressing-mode=STANDARD  # Status Gurtbringer vorne rechts / Belt hand over front right state
        pdu BeltHdOvr_FR_State_ST3: length=4, minimum-delay=0.04, transmission-mode-true-timing={cyclic-timing=time-period=0.5, event-controlled-timing=number-of-repetitions=0}, unused-bit-pattern=255  # Status Gurtbringer vorne rechts / Belt hand over front right state
          signal BeltHdOvr_FR_Stat_ST3: start 0, 2 bit, little-endian, data-type-policy=OVERRIDE, i-signal-type=PRIMITIVE, init-value=3, base-type=uint8, invalid-value=3, compu-method=c02_BeltHdOvr_Stat, data-constr=c02_BeltHdOvr_Stat, transfer-property=TRIGGERED-ON-CHANGE, to RBTM_FL(timeout 5.25 s)  # Status Gurtbringer vorne rechts / Belt hand over front right state
          signal BeltHdOvr_FR_Disp_Rq_ST3: start 2, 2 bit, little-endian, data-type-policy=OVERRIDE, i-signal-type=PRIMITIVE, init-value=3, base-type=uint8, invalid-value=3, compu-method=c02_Ndef_False_True_ST3, data-constr=c02_Ndef_False_True_ST3, transfer-property=PENDING  # Gurtbringer vorne rechts Anzeigeanforderung / Belt hand over front right display request
          signal KG_Key_Rq_BeltHdOvr_FR_ST3: start 4, 2 bit, little-endian, data-type-policy=OVERRIDE, i-signal-type=PRIMITIVE, init-value=3, base-type=uint8, invalid-value=3, compu-method=c02_Ndef_False_True_ST3, data-constr=c02_Ndef_False_True_ST3, transfer-property=PENDING  # Abfrage Keyless Go Schlüssel / Keyless go key request
          signal SeatBeltHdOvr_FR_FctAvlStat_ST3: start 8, 16 bit, little-endian, data-type-policy=OVERRIDE, i-signal-type=PRIMITIVE, init-value=0, base-type=uint16, compu-method=c16_SeatBeltHdOvr_FctAvlStat_ST3, transfer-property=PENDING  # nicht erfüllte Funktionsbedingungen Gurtbringer vorne rechts / unfulfilled preconditions for belt handover front right
          signal SeatBeltHdOvr_FR_VehSpdLmt_ST3: start 24, 8 bit, little-endian, data-type-policy=OVERRIDE, i-signal-type=PRIMITIVE, init-value=255, base-type=uint8, invalid-value=255, compu-method=c08_km_p_h_0_250_1_Blank, data-constr=c08_km_p_h_0_250_1_Blank, transfer-property=PENDING  # Geschwindigkeitsschwelle für die Funktion Gurtbringer vorne rechts / vehicle speed threshold for seatbelt handover front right
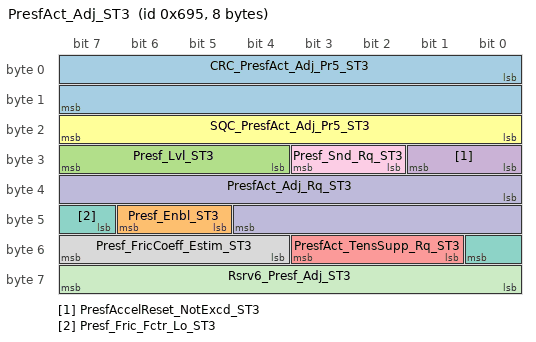
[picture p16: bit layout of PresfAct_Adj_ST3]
      frame PresfAct_Adj_ST3: id 0x695, to RBTM_FL, frame-length=8, variation-point=post-build-variant-condition{matching-criterion=Side, value=1}, can-addressing-mode=STANDARD  # Presf Aktor Steuerung ST3 / Presf Actuator adjustment ST3
        carries pdu PresfAct_Adj_ST3: packing-byte-order=little-endian, start-position=0
        pdu PresfAct_Adj_ST3: length=8, minimum-delay=0.02, transmission-mode-condition{data-filter={data-filter-type=MASKED-NEW-DIFFERS-X, mask=15, x=0}, i-signal-in-i-pdu=Presf_Lvl_ST3}, transmission-mode-false-timing=cyclic-timing={time-offset=0.01, time-period=0.2}, transmission-mode-true-timing=cyclic-timing={time-offset=0.01, time-period=0.02}, unused-bit-pattern=255  # Presf Aktor Steuerung ST3 / Presf Actuator adjustment ST3
          signal CRC_PresfAct_Adj_Pr5_ST3: start 0, 16 bit, little-endian, data-type-policy=OVERRIDE, i-signal-type=PRIMITIVE, init-value=56639, base-type=uint16, data-constr=c16_CRC_woSNA, to RBTM_FL(timeout 2.1 s)  # CRC-Checksumme der Signal Gruppe gemäß AUTOSAR Profil 5 / CRC-checksum of signal group according to AUTOSAR Profile 5
          signal Presf_Enbl_ST3: start 45, 2 bit, little-endian, data-type-policy=OVERRIDE, i-signal-type=PRIMITIVE, init-value=3, base-type=uint8, invalid-value=3, compu-method=c02_false_true_sna, data-constr=c02_false_true_sna, to RBTM_FL(timeout 2.1 s)  # Presafe ermöglicht / Presafe enabled
          signal Presf_Lvl_ST3: start 28, 4 bit, little-endian, data-type-policy=OVERRIDE, i-signal-type=PRIMITIVE, init-value=0, base-type=uint8, invalid-value=15, compu-method=c04_Presf_Lvl_V2, data-constr=c04_Presf_Lvl_V2, to RBTM_FL(timeout 2.1 s)  # Presafe-Level / Presafe level
          signal PresfAccelReset_NotExcd_ST3: start 24, 2 bit, little-endian, data-type-policy=OVERRIDE, i-signal-type=PRIMITIVE, init-value=2, base-type=uint8, invalid-value=3, compu-method=c02_Ndef_False_True_ST3, data-constr=c02_Ndef_False_True_ST3, to RBTM_FL(timeout 2.1 s)  # Presafe Beschleunigungs-Schwelle für Rücksetzen nicht überschritten / Presafe acceleration treshold for reset not exceeded
          signal PresfAct_TensSupp_Rq_ST3: start 49, 3 bit, little-endian, data-type-policy=OVERRIDE, i-signal-type=PRIMITIVE, init-value=7, base-type=uint8, invalid-value=7, compu-method=c03_No_Lt_Rt_Both, data-constr=c03_No_Lt_Rt_Both, to RBTM_FL(timeout 2.1 s)  # Unterdrückung Gurtstraffung / Presafe actuator tensioning suppress request
          signal SQC_PresfAct_Adj_Pr5_ST3: start 16, 8 bit, little-endian, data-type-policy=OVERRIDE, i-signal-type=PRIMITIVE, init-value=0, base-type=uint8, compu-method=none_1_0, data-constr=c08_0_255_1_SNA_na, to RBTM_FL(timeout 2.1 s)  # Sequenzzähler / Sequence counter
          signal Presf_Fric_Fctr_Lo_ST3: start 47, 2 bit, little-endian, data-type-policy=OVERRIDE, i-signal-type=PRIMITIVE, init-value=3, base-type=uint8, invalid-value=3, compu-method=c02_false_true_sna, data-constr=c02_false_true_sna, to RBTM_FL  # Presafe detektiert niedrigen Reibwert / Presafe detects low friction factor
          signal Presf_FricCoeff_Estim_ST3: start 52, 4 bit, little-endian, data-type-policy=OVERRIDE, i-signal-type=PRIMITIVE, init-value=15, base-type=uint8, invalid-value=15, compu-method=c04_Presf_Frct_ST3, data-constr=c04_Presf_Frct_ST3, to RBTM_FL  # Presafe Reibwertschätzung / Presafe Friction Coefficient estimated
          signal Presf_Snd_Rq_ST3: start 26, 2 bit, little-endian, data-type-policy=OVERRIDE, i-signal-type=PRIMITIVE, init-value=0, base-type=uint8, invalid-value=3, compu-method=c02_Presf_Snd, data-constr=c02_Presf_Snd, to RBTM_FL  # Anforderung Presafe sound / Presafe sound request
          signal PresfAct_Adj_Rq_ST3: start 32, 13 bit, little-endian, data-type-policy=OVERRIDE, i-signal-type=PRIMITIVE, init-value=0, base-type=uint32, compu-method=c13_PresfAct_Adj_Rq, to RBTM_FL  # Presf Aktor Steuerung Rq / Presf Actuator adjustment Rq
          signal Rsrv6_Presf_Adj_ST3: start 56, 8 bit, little-endian, data-type-policy=OVERRIDE, i-signal-type=PRIMITIVE, init-value=255, base-type=uint8, invalid-value=255, data-constr=Rsrv08, to RBTM_FL  # Reserviert für zukünftige Verwendung / Reserved for future use
          mapping PresfAct_Adj_Pr5_ST3_2joar1a41xrgjqab60epnbplm: i-signal-group=PresfAct_Adj_Pr5_ST3_2joar1a41xrgjqab60epnbplm, packing-byte-order=little-endian, transfer-property=PENDING
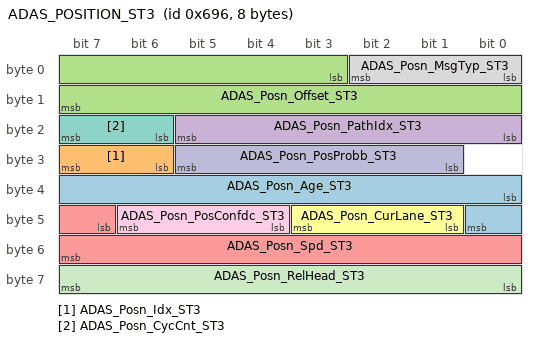
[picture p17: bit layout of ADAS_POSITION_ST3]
      frame ADAS_POSITION_ST3: id 0x696, to RBTM_FL, frame-length=8, variation-point=post-build-variant-condition{matching-criterion=Side, value=1}, can-addressing-mode=STANDARD
        carries pdu ADAS_POSITION_ST3: packing-byte-order=little-endian, start-position=0
        pdu ADAS_POSITION_ST3: length=8, transmission-mode-true-timing=cyclic-timing=time-period=0.5, unused-bit-pattern=255
          signal ADAS_Posn_Age_ST3: start 32, 9 bit, little-endian, data-type-policy=OVERRIDE, i-signal-type=PRIMITIVE, init-value=511, base-type=uint32, invalid-value=511, compu-method=c09_ms_0_510_5, data-constr=c09_ms_0_510_5, to RBTM_FL(timeout 5.1 s)  # Age of the position relative to timestamp of last received GPS message. / Position Age
          signal ADAS_Posn_Idx_ST3: start 30, 2 bit, little-endian, data-type-policy=OVERRIDE, i-signal-type=PRIMITIVE, init-value=0, base-type=uint8, compu-method=c03_ADAS_Posn_Idx, data-constr=c03_ADAS_Posn_Idx, to RBTM_FL(timeout 5.1 s)  # Index des Postionkandidaten / index of this Position Candidate
          signal ADAS_Posn_Offset_ST3: start 3, 13 bit, little-endian, data-type-policy=OVERRIDE, i-signal-type=PRIMITIVE, init-value=8191, base-type=uint16, invalid-value=8191, compu-method=c13_m_0_8190_1, data-constr=c13_m_0_8190_1, to RBTM_FL(timeout 5.1 s)  # Offeset derzeitigen Position ab dem Startpunkt modulo 8191 / Position Message: Offset of current position from the start point modulo 8191i
          signal ADAS_Posn_PathIdx_ST3: start 16, 6 bit, little-endian, data-type-policy=OVERRIDE, i-signal-type=PRIMITIVE, init-value=0, base-type=uint8, compu-method=c06_Idx_0_to_63_1, data-constr=c06_Idx_0_to_63_1, to RBTM_FL(timeout 5.1 s)  # Position Message: Index derzeitigen Path / Position Message: Index of current path
          signal ADAS_Posn_Spd_ST3: start 47, 9 bit, little-endian, data-type-policy=OVERRIDE, i-signal-type=PRIMITIVE, init-value=511, base-type=uint16, invalid-value=511, compu-method=c09_m_p_s_m12k8_89k2_0k2, data-constr=c09_m_p_s_m12k8_89k2_0k2, to RBTM_FL(timeout 5.1 s)  # Geschwindigkeit des Fahrzeuges / Speed of the vehicle projected to the link
          signal ADAS_Posn_CurLane_ST3: start 41, 3 bit, little-endian, data-type-policy=OVERRIDE, i-signal-type=PRIMITIVE, init-value=0, base-type=uint8, invalid-value=7, compu-method=c03_ADAS_Posn_CurLane, data-constr=c03_ADAS_Posn_CurLane  # derzeitige Fahrspur / Current lane
          signal ADAS_Posn_CycCnt_ST3: start 22, 2 bit, little-endian, data-type-policy=OVERRIDE, i-signal-type=PRIMITIVE, init-value=0, base-type=uint8, compu-method=c02_0_3_1_nSNA, data-constr=c02_0_3_1_nSNA  # Position Message: Zyklischer Zähler / Position Message: Cyclic Counter
          signal ADAS_Posn_MsgTyp_ST3: start 0, 3 bit, little-endian, data-type-policy=OVERRIDE, i-signal-type=PRIMITIVE, init-value=1, base-type=uint8, invalid-value=7, compu-method=c03_MsgTyp_1_to_7, data-constr=c03_MsgTyp_1_to_7  # Position Message: Messagetype / Position Message: Message Typ
          signal ADAS_Posn_PosConfdc_ST3: start 44, 3 bit, little-endian, data-type-policy=OVERRIDE, i-signal-type=PRIMITIVE, init-value=7, base-type=uint8, invalid-value=7, compu-method=c03_0_6_1, data-constr=c03_0_6_1  # Position Confidence
          signal ADAS_Posn_PosProbb_ST3: start 25, 5 bit, little-endian, data-type-policy=OVERRIDE, i-signal-type=PRIMITIVE, init-value=31, base-type=uint8, invalid-value=31, compu-method=c05_perc_0_31_3k333, data-constr=c05_perc_0_31_3k333  # Positionmöglichkeit / Position Probability
          signal ADAS_Posn_RelHead_ST3: start 56, 8 bit, little-endian, data-type-policy=OVERRIDE, i-signal-type=PRIMITIVE, init-value=255, base-type=uint8, invalid-value=255, compu-method=c08_deg_0_358k5_1k417, data-constr=c08_deg_0_358k5_1k417  # Richtung / Heading relative to path: 0 in path dir., 1..126 right from, 253..128 left from, 127 in opp. dir.
          mapping ADAS_Posn_ST3_cre9f2x2lehhx0k4gxnl4u9sg: i-signal-group=ADAS_Posn_ST3_cre9f2x2lehhx0k4gxnl4u9sg, packing-byte-order=little-endian, transfer-property=PENDING
      frame RBTM_FL_Stat_ST3: id 0x698, to RBTM_FL, frame-length=8, variation-point=post-build-variant-condition{matching-criterion=Side, value=1}, can-addressing-mode=STANDARD  # RBTM vorne links Status ST3 / RBTM front left state ST3
        carries pdu RBTM_FL_Stat_ST3: packing-byte-order=little-endian, start-position=0
        pdu RBTM_FL_Stat_ST3: length=8, minimum-delay=0.04, transmission-mode-true-timing={cyclic-timing={time-offset=0.02, time-period=1}, event-controlled-timing=number-of-repetitions=0}, unused-bit-pattern=255  # RBTM vorne links Status / RBTM front left state
          signal PS_Curve_FL_Stat_ST3: start 2, 2 bit, little-endian, data-type-policy=OVERRIDE, i-signal-type=PRIMITIVE, init-value=3, base-type=uint8, invalid-value=3, compu-method=c02_Off_Stage1_Stage2, data-constr=c02_Off_Stage1_Stage2, transfer-property=TRIGGERED-ON-CHANGE, variation-point=post-build-variant-condition{matching-criterion=Side, value=0}  # PreSafe Curve Status vorne links / PreSafe Curve mode state front left
          signal RBTM_FL_Disp_Rq_ST3: start 24, 2 bit, little-endian, data-type-policy=OVERRIDE, i-signal-type=PRIMITIVE, init-value=0, base-type=uint8, compu-method=c02_Presf_Disp_Rq, data-constr=c02_Presf_Disp_Rq, transfer-property=TRIGGERED-ON-CHANGE, variation-point=post-build-variant-condition{matching-criterion=Side, value=0}  # Presafe Kombimeldung vorne links anzeigen / Presafe display request front left
          signal RBTM_FL_Tgl_ST3: start 26, 1 bit, little-endian, data-type-policy=OVERRIDE, i-signal-type=PRIMITIVE, init-value=0, base-type=boolean, transfer-property=PENDING  # Presafe Togglebit
          signal RevBltTns_FL_SafeCyc_Actv_ST3: start 0, 2 bit, little-endian, data-type-policy=OVERRIDE, i-signal-type=PRIMITIVE, init-value=3, base-type=uint8, invalid-value=3, compu-method=c02_Ndef_False_True_ST3, data-constr=c02_Ndef_False_True_ST3, transfer-property=TRIGGERED-ON-CHANGE, to RBTM_FL  # Reversibler Gurtstraffer vorne links Sicherheits-Straffzyklus aktiv / Reversible belt tensioner front left safety tensioning cycle active
          signal PS_Curve_FL_Stat_ST3: start 2, 2 bit, little-endian, data-type-policy=OVERRIDE, i-signal-type=PRIMITIVE, init-value=3, base-type=uint8, invalid-value=3, compu-method=c02_Off_Stage1_Stage2, data-constr=c02_Off_Stage1_Stage2, transfer-property=PENDING, variation-point=post-build-variant-condition{matching-criterion=Side, value=1}  # PreSafe Curve Status vorne links / PreSafe Curve mode state front left
          signal RBTM_FL_Disp_Rq_ST3: start 24, 2 bit, little-endian, data-type-policy=OVERRIDE, i-signal-type=PRIMITIVE, init-value=0, base-type=uint8, compu-method=c02_Presf_Disp_Rq, data-constr=c02_Presf_Disp_Rq, transfer-property=PENDING, variation-point=post-build-variant-condition{matching-criterion=Side, value=1}  # Presafe Kombimeldung vorne links anzeigen / Presafe display request front left
      frame RBTM_FR_Stat_ST3: id 0x699, from RBTM_FL, frame-length=8, variation-point=post-build-variant-condition{matching-criterion=Side, value=1}, can-addressing-mode=STANDARD  # RBTM vorne rechts Status ST3 / RBTM front right state ST3
        carries pdu RBTM_FR_Stat_ST3: packing-byte-order=little-endian, start-position=0
        pdu RBTM_FR_Stat_ST3: length=8, minimum-delay=0.04, transmission-mode-true-timing={cyclic-timing={time-offset=0.01, time-period=1}, event-controlled-timing=number-of-repetitions=0}, unused-bit-pattern=255  # RBTM vorne rechts Status / RBTM front right state
          signal RevBltTns_FR_SafeCyc_Actv_ST3: start 0, 2 bit, little-endian, data-type-policy=OVERRIDE, i-signal-type=PRIMITIVE, init-value=3, base-type=uint8, invalid-value=3, compu-method=c02_Ndef_False_True_ST3, data-constr=c02_Ndef_False_True_ST3, transfer-property=TRIGGERED-ON-CHANGE, to RBTM_FL  # Reversibler Gurtstraffer vorne rechts Sicherheits-Straffzyklus aktiv / Reversible belt tensioner front right safety tensioning cycle active
          signal PS_Curve_FR_Stat_ST3: start 2, 2 bit, little-endian, data-type-policy=OVERRIDE, i-signal-type=PRIMITIVE, init-value=3, base-type=uint8, invalid-value=3, compu-method=c02_Off_Stage1_Stage2, data-constr=c02_Off_Stage1_Stage2, transfer-property=PENDING, variation-point=post-build-variant-condition{matching-criterion=Side, value=0}  # PreSafe Curve Status vorne rechts / PreSafe Curve mode state front right
          signal RBTM_FR_Disp_Rq_ST3: start 24, 2 bit, little-endian, data-type-policy=OVERRIDE, i-signal-type=PRIMITIVE, init-value=0, base-type=uint8, compu-method=c02_Presf_Disp_Rq, data-constr=c02_Presf_Disp_Rq, transfer-property=PENDING, variation-point=post-build-variant-condition{matching-criterion=Side, value=0}  # Presafe Kombimeldung vorne rechts anzeigen / Presafe display request front right
          signal RBTM_FR_Tgl_ST3: start 26, 1 bit, little-endian, data-type-policy=OVERRIDE, i-signal-type=PRIMITIVE, init-value=0, base-type=boolean, transfer-property=PENDING  # Presafe Togglebit
          signal PS_Curve_FR_Stat_ST3: start 2, 2 bit, little-endian, data-type-policy=OVERRIDE, i-signal-type=PRIMITIVE, init-value=3, base-type=uint8, invalid-value=3, compu-method=c02_Off_Stage1_Stage2, data-constr=c02_Off_Stage1_Stage2, transfer-property=TRIGGERED-ON-CHANGE, variation-point=post-build-variant-condition{matching-criterion=Side, value=1}  # PreSafe Curve Status vorne rechts / PreSafe Curve mode state front right
          signal RBTM_FR_Disp_Rq_ST3: start 24, 2 bit, little-endian, data-type-policy=OVERRIDE, i-signal-type=PRIMITIVE, init-value=0, base-type=uint8, compu-method=c02_Presf_Disp_Rq, data-constr=c02_Presf_Disp_Rq, transfer-property=TRIGGERED-ON-CHANGE, variation-point=post-build-variant-condition{matching-criterion=Side, value=1}  # Presafe Kombimeldung vorne rechts anzeigen / Presafe display request front right
      frame BeltAdj_FL_Stat_ST3: id 0x6A0, to RBTM_FL, frame-length=1, variation-point=post-build-variant-condition{matching-criterion=Side, value=1}, can-addressing-mode=STANDARD  # Gurtanpassung vorne links Status / Belt adjustment front left state
        carries pdu BeltAdj_FL_Stat_ST3: packing-byte-order=little-endian, start-position=0
        pdu BeltAdj_FL_Stat_ST3: length=1, minimum-delay=0.04, transmission-mode-true-timing={cyclic-timing={time-offset=0.01, time-period=1}, event-controlled-timing=number-of-repetitions=0}, unused-bit-pattern=255  # Gurtanpassung vorne links Status / Belt adjustment front left state
          signal BltSlckDec_Md_FL_Stat_ST3: start 0, 2 bit, little-endian, data-type-policy=OVERRIDE, i-signal-type=PRIMITIVE, init-value=3, base-type=uint8, invalid-value=3, compu-method=c02_Off_On, data-constr=c02_Off_On, transfer-property=TRIGGERED-ON-CHANGE, variation-point=post-build-variant-condition{matching-criterion=Side, value=0}  # Modus Gurtlosereduktion Status vorne links / Belt slack decreasing mode front left state
          signal RevBltTns_FL_ComCyc_Actv_ST3: start 2, 2 bit, little-endian, data-type-policy=OVERRIDE, i-signal-type=PRIMITIVE, init-value=3, base-type=uint8, invalid-value=3, compu-method=c02_Ndef_False_True_ST3, data-constr=c02_Ndef_False_True_ST3, transfer-property=TRIGGERED-ON-CHANGE, to RBTM_FL  # Reversibler Gurtstraffer vorne links Komfort-Straffzyklus aktiv / Reversible belt tensioner front left comfort tensioning cycle active
          signal BltSlckDec_Md_FL_Stat_ST3: start 0, 2 bit, little-endian, data-type-policy=OVERRIDE, i-signal-type=PRIMITIVE, init-value=3, base-type=uint8, invalid-value=3, compu-method=c02_Off_On, data-constr=c02_Off_On, transfer-property=PENDING, variation-point=post-build-variant-condition{matching-criterion=Side, value=1}  # Modus Gurtlosereduktion Status vorne links / Belt slack decreasing mode front left state
      frame BeltAdj_FR_Stat_ST3: id 0x6A1, from RBTM_FL, frame-length=1, variation-point=post-build-variant-condition{matching-criterion=Side, value=1}, can-addressing-mode=STANDARD  # Gurtanpassung vorne rechts Status / Belt adjustment front right state
        carries pdu BeltAdj_FR_Stat_ST3: packing-byte-order=little-endian, start-position=0
        pdu BeltAdj_FR_Stat_ST3: length=1, minimum-delay=0.04, transmission-mode-true-timing={cyclic-timing={time-offset=0.02, time-period=1}, event-controlled-timing=number-of-repetitions=0}, unused-bit-pattern=255  # Gurtanpassung vorne rechts Status / Belt adjustment front right state
          signal RevBltTns_FR_ComCyc_Actv_ST3: start 2, 2 bit, little-endian, data-type-policy=OVERRIDE, i-signal-type=PRIMITIVE, init-value=3, base-type=uint8, invalid-value=3, compu-method=c02_Ndef_False_True_ST3, data-constr=c02_Ndef_False_True_ST3, transfer-property=TRIGGERED-ON-CHANGE, to RBTM_FL  # Reversibler Gurtstraffer vorne rechts Komfort-Straffzyklus aktiv / Reversible belt tensioner front right comfort tensioning cycle active
          signal BltSlckDec_Md_FR_Stat_ST3: start 0, 2 bit, little-endian, data-type-policy=OVERRIDE, i-signal-type=PRIMITIVE, init-value=3, base-type=uint8, invalid-value=3, compu-method=c02_Off_On, data-constr=c02_Off_On, transfer-property=PENDING, variation-point=post-build-variant-condition{matching-criterion=Side, value=0}  # Modus Gurtlosereduktion Status vorne rechts / Belt slack decreasing mode front right state
          signal BltSlckDec_Md_FR_Stat_ST3: start 0, 2 bit, little-endian, data-type-policy=OVERRIDE, i-signal-type=PRIMITIVE, init-value=3, base-type=uint8, invalid-value=3, compu-method=c02_Off_On, data-constr=c02_Off_On, transfer-property=TRIGGERED-ON-CHANGE, variation-point=post-build-variant-condition{matching-criterion=Side, value=1}  # Modus Gurtlosereduktion Status vorne rechts / Belt slack decreasing mode front right state
      frame BeltAdj_UI_Set_Rq_ST3: id 0x6A2, to RBTM_FL, frame-length=1, variation-point=post-build-variant-condition{matching-criterion=Side, value=1}, can-addressing-mode=STANDARD  # Anforderung Gurtanpassung Einstellungen / Belt adjustment UI setting request
        carries pdu BeltAdj_UI_Set_Rq_ST3: packing-byte-order=little-endian, start-position=0
        pdu BeltAdj_UI_Set_Rq_ST3: length=1, minimum-delay=0.02, transmission-mode-true-timing={cyclic-timing=time-period=1, event-controlled-timing=number-of-repetitions=0}, unused-bit-pattern=255  # Anforderung Gurtanpassung Einstellungen / Belt adjustment UI setting request
          signal BltSlckDec_Md_Rq_HU_ST3: start 0, 2 bit, little-endian, data-type-policy=OVERRIDE, i-signal-type=PRIMITIVE, init-value=3, base-type=uint8, invalid-value=3, compu-method=c02_Off_On, data-constr=c02_Off_On, transfer-property=TRIGGERED-ON-CHANGE, to RBTM_FL(timeout 60.5 s)  # Anforderung Modus Gurtlosereduktion von Headunit / Belt slack decreasing mode request from Head Unit
          signal PS_Curve_FL_Rq_HU_ST3: start 2, 2 bit, little-endian, data-type-policy=OVERRIDE, i-signal-type=PRIMITIVE, init-value=3, base-type=uint8, invalid-value=3, compu-method=c02_Off_Stage1_Stage2, data-constr=c02_Off_Stage1_Stage2, transfer-property=TRIGGERED-ON-CHANGE, variation-point=post-build-variant-condition{matching-criterion=Side, value=0}, to RBTM_FL(timeout 10.1 s)  # Anforderung PreSafe Curve Modus von Headunit vorne links / PreSafe Curve mode request from headunit front left
          signal PS_Curve_FR_Rq_HU_ST3: start 4, 2 bit, little-endian, data-type-policy=OVERRIDE, i-signal-type=PRIMITIVE, init-value=3, base-type=uint8, invalid-value=3, compu-method=c02_Off_Stage1_Stage2, data-constr=c02_Off_Stage1_Stage2, transfer-property=PENDING, variation-point=post-build-variant-condition{matching-criterion=Side, value=0}, to RBTM_FL(timeout 10.1 s)  # IF PS Curve vorne rechts Anforderung HU ST3 / IF PS Curve front right Request(ed) HU ST3
          signal PS_Curve_FR_Rq_HU_ST3: start 4, 2 bit, little-endian, data-type-policy=OVERRIDE, i-signal-type=PRIMITIVE, init-value=3, base-type=uint8, invalid-value=3, compu-method=c02_Off_Stage1_Stage2, data-constr=c02_Off_Stage1_Stage2, transfer-property=TRIGGERED-ON-CHANGE, variation-point=post-build-variant-condition{matching-criterion=Side, value=1}, to RBTM_FL(timeout 10.1 s)  # IF PS Curve vorne rechts Anforderung HU ST3 / IF PS Curve front right Request(ed) HU ST3
          signal PS_Curve_FL_Rq_HU_ST3: start 2, 2 bit, little-endian, data-type-policy=OVERRIDE, i-signal-type=PRIMITIVE, init-value=3, base-type=uint8, invalid-value=3, compu-method=c02_Off_Stage1_Stage2, data-constr=c02_Off_Stage1_Stage2, transfer-property=PENDING, variation-point=post-build-variant-condition{matching-criterion=Side, value=1}, to RBTM_FL(timeout 10.1 s)  # Anforderung PreSafe Curve Modus von Headunit vorne links / PreSafe Curve mode request from headunit front left
      frame Bckl_Sw_Fx_Stat_ST3: id 0x6A3, to RBTM_FL, frame-length=8, variation-point=post-build-variant-condition{matching-criterion=Side, value=1}, can-addressing-mode=STANDARD  # Bckl Sw Fx Status ST3 / Bckl Sw Fx state ST3
        carries pdu Bckl_Sw_Fx_Stat_ST3_secured: packing-byte-order=little-endian, start-position=0
        secured i pdu Bckl_Sw_Fx_Stat_ST3_secured: length=8, authentication-props=SECOC_AP_CMAC_AES_128_24, freshness-props=SECOC_FP_10000_40_8_true, payload=BODY3/Bckl_Sw_Fx_Stat_ST3_76xqik47h3rgo3857pk44xg84, secure-communication-props={authentication-retries=0, data-id=15576, freshness-value-id=1}
      frame DPC_Md_Rq_ESP_d1_ST3: id 0x6C3, to RBTM_FL, frame-length=1, variation-point=post-build-variant-condition{matching-criterion=Side, value=1}, can-addressing-mode=STANDARD  # Dynamic select Anforderung / Dynamic select request
        carries pdu DPC_Md_Rq_ESP_d1_ST3: packing-byte-order=little-endian, start-position=0
        pdu DPC_Md_Rq_ESP_d1_ST3: length=1, minimum-delay=0.1, transmission-mode-true-timing={cyclic-timing={time-offset=0, time-period=1}, event-controlled-timing=number-of-repetitions=0}, unused-bit-pattern=255  # Dynamic select Anforderung / Dynamic select request
          signal DPC_Md_PT_Rq_ST3: start 0, 5 bit, little-endian, data-type-policy=OVERRIDE, i-signal-type=PRIMITIVE, init-value=0, base-type=uint8, invalid-value=31, compu-method=c05_DPC_Md_PT_HU, data-constr=c05_DPC_Md_PT_HU, to RBTM_FL  # Fahrprogrammwahl: Anforderung Powertrain / Driving program control: powertrain mode request
          mapping DPC_Md_Rq_ESP_Pr5_ST3_dcsny138uwpesz5bmssj1scqi: i-signal-group=DPC_Md_Rq_ESP_Pr5_ST3_dcsny138uwpesz5bmssj1scqi, packing-byte-order=little-endian, transfer-property=TRIGGERED-ON-CHANGE, update-indication-bit-position=5
      frame NTG_Master_Navi_ST3: id 0x6C4, to RBTM_FL, frame-length=2, variation-point=post-build-variant-condition{matching-criterion=Side, value=1}, can-addressing-mode=STANDARD  # New Telematics Generation Navigation Master
        carries pdu NTG_Master_Navi_ST3: packing-byte-order=little-endian, start-position=0
        pdu NTG_Master_Navi_ST3: length=2, minimum-delay=0.02, transmission-mode-true-timing={cyclic-timing={time-offset=0.01, time-period=0.2}, event-controlled-timing=number-of-repetitions=0}, unused-bit-pattern=255  # New Telematics Generation Navigation Master
          signal Navi_RouteGuidance_Stat_ST3: start 8, 2 bit, little-endian, data-type-policy=OVERRIDE, i-signal-type=PRIMITIVE, init-value=3, base-type=uint8, invalid-value=3, compu-method=c02_Inactv_Silent_Actv_ST3, data-constr=c02_Inactv_Silent_Actv_ST3, transfer-property=TRIGGERED-ON-CHANGE, to RBTM_FL(timeout 10.1 s)  # Navigation Status Zielführung / Navigation route guidance state
          signal Navi_MPP_ResetRsn_ST3: start 10, 2 bit, little-endian, data-type-policy=OVERRIDE, i-signal-type=PRIMITIVE, init-value=3, base-type=uint8, invalid-value=3, compu-method=c02_Navi_MPP_ResetRsn_ST3, data-constr=c02_Navi_MPP_ResetRsn_ST3, transfer-property=PENDING  # Navigation Grund für das Zurücksetzen des Most probable Paths / Navigation Reason for resetting the most probable path
          signal WhlCircumDyn_F_HU_ST3: start 0, 8 bit, little-endian, data-type-policy=OVERRIDE, i-signal-type=PRIMITIVE, init-value=255, base-type=uint8, invalid-value=255, compu-method=c08_m_1d6_2d87_0d005, data-constr=c08_m_1d6_2d87_0d005, transfer-property=PENDING  # Dynamische Radumfang Vorderachse von der HU / Dynamic wheel circumference front axle from HU
      frame ELC_Lvr_Stat_ST3: id 0x6C5, to RBTM_FL, frame-length=8, variation-point=post-build-variant-condition{matching-criterion=Side, value=1}, can-addressing-mode=STANDARD  # Status Bedienhebel Außenlicht / Exterior light lever state
        carries pdu ELC_Lvr_Stat_ST3_secured: packing-byte-order=little-endian, start-position=0
        secured i pdu ELC_Lvr_Stat_ST3_secured: length=8, authentication-props=SECOC_AP_CMAC_AES_128_24, freshness-props=SECOC_FP_10000_40_8_true, payload=BODY3/ELC_Lvr_Stat_ST3_73cx1t6a1vhnmsct6284cefhl, secure-communication-props={authentication-retries=0, data-id=37177, freshness-value-id=1}
      frame DIAG_Stat_ST3: id 0x6D0, to RBTM_FL, frame-length=4, variation-point=post-build-variant-condition{matching-criterion=Side, value=1}, can-addressing-mode=STANDARD  # Actv Line Status Tester pres / Actv Line state Tester pres
        carries pdu DIAG_Stat_ST3: packing-byte-order=little-endian, start-position=0
        pdu DIAG_Stat_ST3: length=4, minimum-delay=0.04, transmission-mode-true-timing={cyclic-timing=time-period=1, event-controlled-timing=number-of-repetitions=0}, unused-bit-pattern=255  # Actv Line Status Tester pres / Actv Line state Tester pres
          signal DidA_ExtTest_Pres_ST3: start 2, 2 bit, little-endian, data-type-policy=OVERRIDE, i-signal-type=PRIMITIVE, init-value=3, base-type=uint8, invalid-value=3, compu-method=c02_Ndef_False_True_ST3, data-constr=c02_Ndef_False_True_ST3, transfer-property=TRIGGERED-ON-CHANGE, to RBTM_FL  # DidA Externer Tester erkannt / DidA external tester present
          signal Actv_Line_Stat_ST3: start 0, 2 bit, little-endian, data-type-policy=OVERRIDE, i-signal-type=PRIMITIVE, init-value=0, base-type=uint8, invalid-value=3, compu-method=c02_Inact_Act_ST3, data-constr=c02_Inact_Act_ST3, transfer-property=PENDING  # Aktivierungs Leitungsstatus / Activation Line state
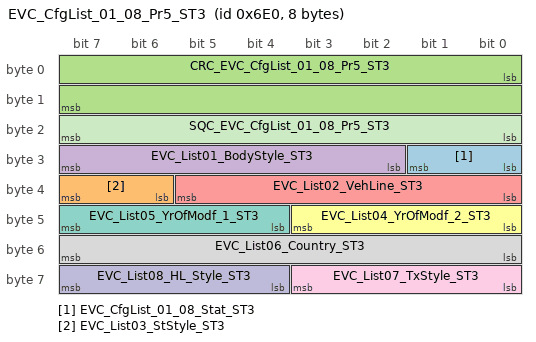
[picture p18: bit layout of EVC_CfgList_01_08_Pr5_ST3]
      frame EVC_CfgList_01_08_Pr5_ST3: id 0x6E0, to RBTM_FL, frame-length=8, variation-point=post-build-variant-condition{matching-criterion=Side, value=1}, can-addressing-mode=STANDARD  # EVC-CfgMessage[Lists:01h-08h]
        carries pdu EVC_CfgList_01_08_Pr5_ST3: packing-byte-order=little-endian, start-position=0
        pdu EVC_CfgList_01_08_Pr5_ST3: length=8, transmission-mode-true-timing=cyclic-timing=time-period=1, unused-bit-pattern=255  # EVC-CfgMessage[Lists:01h-08h]
          signal EVC_CfgList_01_08_Stat_ST3: start 24, 2 bit, little-endian, data-type-policy=OVERRIDE, i-signal-type=PRIMITIVE, init-value=3, base-type=uint8, invalid-value=3, compu-method=c02_EVC_Stat, data-constr=c02_EVC_Stat, to RBTM_FL(timeout 2.5 s)  # Status EVC-CfgMessage[Listen:01h-08h] / Status EVC-CfgMessage[Lists:01h-08h]
          signal EVC_List03_StStyle_ST3: start 38, 2 bit, little-endian, data-type-policy=OVERRIDE, i-signal-type=PRIMITIVE, init-value=3, base-type=uint8, invalid-value=3, compu-method=c02_StStyle, data-constr=c02_StStyle, to RBTM_FL(timeout 2.5 s)  # Lenkungsvariante / Steering variant
          signal CRC_EVC_CfgList_01_08_Pr5_ST3: start 0, 16 bit, little-endian, data-type-policy=OVERRIDE, i-signal-type=PRIMITIVE, init-value=46137, base-type=uint16, data-constr=c16_CRC_woSNA  # CRC-Checksumme der Signal Gruppe gemäß AUTOSAR Profil 5 / CRC-checksum of signal group according to AUTOSAR Profile 5
          signal EVC_List01_BodyStyle_ST3: start 26, 6 bit, little-endian, data-type-policy=OVERRIDE, i-signal-type=PRIMITIVE, init-value=63, base-type=uint8, compu-method=c06_EVC_BodyStyle_ST3, data-constr=c06_EVC_BodyStyle_ST3  # Karosserievariante / Vehicle body style
          signal EVC_List02_VehLine_ST3: start 32, 6 bit, little-endian, data-type-policy=OVERRIDE, i-signal-type=PRIMITIVE, init-value=63, base-type=uint8, compu-method=c06_EVC_VehLine_ST3, data-constr=c06_EVC_VehLine_ST3  # Baureihe / Vehicle line
          signal EVC_List04_YrOfModf_2_ST3: start 40, 4 bit, little-endian, data-type-policy=OVERRIDE, i-signal-type=PRIMITIVE, init-value=15, base-type=uint8, compu-method=c04_EVC_YrOfModf_2_ST3, data-constr=c04_EVC_YrOfModf_2_ST3  # Änderungsjahr YY/2 / Year of Modification YY/2
          signal EVC_List05_YrOfModf_1_ST3: start 44, 4 bit, little-endian, data-type-policy=OVERRIDE, i-signal-type=PRIMITIVE, init-value=15, base-type=uint8, compu-method=c04_EVC_YrOfModf_1_ST3, data-constr=c04_EVC_YrOfModf_1_ST3  # Änderungsjahr YY/1 / Year of Modification YY/1
          signal EVC_List06_Country_ST3: start 48, 8 bit, little-endian, data-type-policy=OVERRIDE, i-signal-type=PRIMITIVE, init-value=255, base-type=uint8, compu-method=c08_EVC_Country_extended, data-constr=c08_EVC_Country_extended  # Land / Country
          signal EVC_List07_TxStyle_ST3: start 56, 4 bit, little-endian, data-type-policy=OVERRIDE, i-signal-type=PRIMITIVE, init-value=15, base-type=uint8, compu-method=c04_EVC_TxStyle_ST3, data-constr=c04_EVC_TxStyle_ST3  # Getriebeart / Transmission Style
          signal EVC_List08_HL_Style_ST3: start 60, 4 bit, little-endian, data-type-policy=OVERRIDE, i-signal-type=PRIMITIVE, init-value=15, base-type=uint8, compu-method=c04_EVC_HL_Style_ST3, data-constr=c04_EVC_HL_Style_ST3  # Scheinwerferart / Headlamp Style
          signal SQC_EVC_CfgList_01_08_Pr5_ST3: start 16, 8 bit, little-endian, data-type-policy=OVERRIDE, i-signal-type=PRIMITIVE, init-value=0, base-type=uint8, compu-method=none_1_0, data-constr=c08_0_255_1_SNA_na  # Sequenzzähler / Sequence counter
          mapping EVC_CfgList_01_08_Pr5_ST3_co3q1mwsf7pwxo2ix5jryc04x: i-signal-group=EVC_CfgList_01_08_Pr5_ST3_co3q1mwsf7pwxo2ix5jryc04x, packing-byte-order=little-endian, transfer-property=PENDING
      frame ADAS_PREDICTION_ST3: id 0x6E6, to RBTM_FL, frame-length=8, variation-point=post-build-variant-condition{matching-criterion=Side, value=1}, can-addressing-mode=STANDARD
        carries pdu ADAS_PREDICTION_ST3: packing-byte-order=little-endian, start-position=0
        multiplexed i pdu ADAS_PREDICTION_ST3:
          length=8
          dynamic-part{segment-position{segment-byte-order=little-endian, segment-length=64, segment-position=0}, dynamic-part-alternatives=[{i-pdu=ADAS_PREDICTION_ST3_6, initial-dynamic-part=false, selector-field-code=6}, {i-pdu=ADAS_PREDICTION_ST3_7, initial-dynamic-part=true, selector-field-code=7}]}
          selector-field-byte-order=little-endian
          selector-field-length=3
          selector-field-start-position=0
          trigger-mode=DYNAMIC-PART-TRIGGER
          unused-bit-pattern=255
      frame NM_RBTM_FR_ST3: id 0x144201A5, from RBTM_FL, frame-length=8, variation-point=post-build-variant-condition{matching-criterion=Side, value=1}, can-addressing-mode=EXTENDED  # Netzwerk-Management / Network Management
        nm pdu NM_RBTM_FR_ST3: length=8, nm-data-information=true, unused-bit-pattern=0  # STAR3 NM PDU
          signal NM_RBTM_FR_ST3_PNC: start 8, 56 bit, opaque, data-type-policy=OVERRIDE, i-signal-type=ARRAY, init-value=7 x 0, base-type=uint8, transfer-property=PENDING  # PNC_Vector
      frame NM_Dummy_ST3: id 0x14420FFF, to RBTM_FL, frame-length=8, variation-point=post-build-variant-condition{matching-criterion=Side, value=1}, can-addressing-mode=EXTENDED, rx-identifier-range={lower-can-id=339869696, upper-can-id=339873791}  # Netzwerk-Management / Network Management
        carries pdu NM_Dummy_ST3: packing-byte-order=little-endian, start-position=0
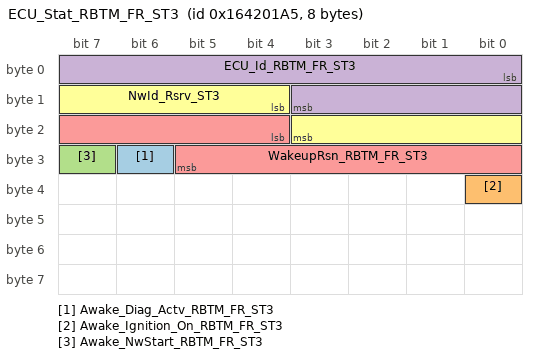
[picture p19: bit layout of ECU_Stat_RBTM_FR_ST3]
      frame ECU_Stat_RBTM_FR_ST3: id 0x164201A5, from RBTM_FL, frame-length=8, variation-point=post-build-variant-condition{matching-criterion=Side, value=1}, can-addressing-mode=EXTENDED  # ECU Status / ECU state
        pdu ECU_Stat_RBTM_FR_ST3: length=8, transmission-mode-true-timing=cyclic-timing={time-offset=0, time-period=1}, unused-bit-pattern=0  # ECU Status / ECU state
          signal Awake_Diag_Actv_RBTM_FR_ST3: start 30, 1 bit, little-endian, data-type-policy=OVERRIDE, i-signal-type=PRIMITIVE, init-value=0, base-type=boolean, transfer-property=PENDING  # Wachhalten für Diagnose aktiv / Stay awake for diagnostics active
          signal Awake_Ignition_On_RBTM_FR_ST3: start 32, 1 bit, little-endian, data-type-policy=OVERRIDE, i-signal-type=PRIMITIVE, init-value=0, base-type=boolean, transfer-property=PENDING  # Wachhalten für Zündung eingeschaltet / Stay awake for ignition on
          signal Awake_NwStart_RBTM_FR_ST3: start 31, 1 bit, little-endian, data-type-policy=OVERRIDE, i-signal-type=PRIMITIVE, init-value=0, base-type=boolean, transfer-property=PENDING  # Wachhalten für Netzwerkstartphase / Stay awake for network startup
          signal ECU_Id_RBTM_FR_ST3: start 0, 12 bit, little-endian, data-type-policy=OVERRIDE, i-signal-type=PRIMITIVE, init-value=421, base-type=uint16, invalid-value=4095, compu-method=c12_0_4094_1_SNA, data-constr=c12_0_4094_1_SNA, transfer-property=PENDING  # ECU-Identifizierungsnummer / ECU identifier
          signal WakeupRsn_RBTM_FR_ST3: start 20, 10 bit, little-endian, data-type-policy=OVERRIDE, i-signal-type=PRIMITIVE, init-value=1023, base-type=uint16, invalid-value=1023, compu-method=c10_WakeupRsn_ST3, data-constr=c10_WakeupRsn_ST3, transfer-property=PENDING  # Weckgrund / Wakeup reason
          signal NwId_Rsrv_ST3: start 12, 8 bit, little-endian, data-type-policy=OVERRIDE, i-signal-type=PRIMITIVE, init-value=0, base-type=uint8, invalid-value=255, compu-method=c08_0_254_1_SNA_255, data-constr=c08_0_254_1_SNA_255, transfer-property=PENDING  # Signal to close the gap in ECU-Stat-PDUs for ECUs w/o NW-ID
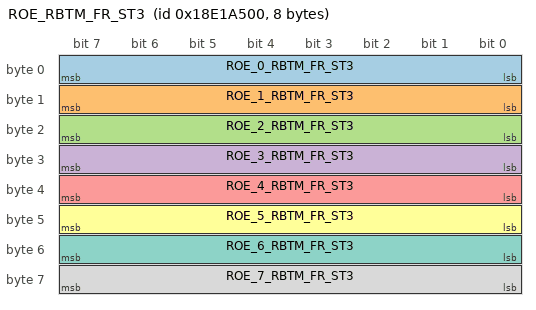
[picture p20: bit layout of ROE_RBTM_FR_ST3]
      frame ROE_RBTM_FR_ST3: id 0x18E1A500, from RBTM_FL, frame-length=8, variation-point=post-build-variant-condition{matching-criterion=Side, value=1}, can-addressing-mode=EXTENDED  # Ereignis-Antwort / Response on Event
        pdu ROE_RBTM_FR_ST3: length=8, minimum-delay=0.2, transmission-mode-true-timing=event-controlled-timing=number-of-repetitions=0, unused-bit-pattern=0  # Ereignis-Antwort / Response on Event
          signal ROE_0_RBTM_FR_ST3: start 0, 8 bit, little-endian, data-type-policy=OVERRIDE, i-signal-type=PRIMITIVE, init-value=0, base-type=uint8, compu-method=c08_ROE_0, data-constr=c08_ROE_0  # Ereignis-Antwort / Response on Event
          signal ROE_1_RBTM_FR_ST3: start 8, 8 bit, little-endian, data-type-policy=OVERRIDE, i-signal-type=PRIMITIVE, init-value=0, base-type=uint8, data-constr=c08_UInt_SNA_na  # Ereignis-Antwort / Response on Event
          signal ROE_2_RBTM_FR_ST3: start 16, 8 bit, little-endian, data-type-policy=OVERRIDE, i-signal-type=PRIMITIVE, init-value=0, base-type=uint8, data-constr=c08_UInt_SNA_na  # Ereignis-Antwort / Response on Event
          signal ROE_3_RBTM_FR_ST3: start 24, 8 bit, little-endian, data-type-policy=OVERRIDE, i-signal-type=PRIMITIVE, init-value=0, base-type=uint8, data-constr=c08_UInt_SNA_na  # Ereignis-Antwort / Response on Event
          signal ROE_4_RBTM_FR_ST3: start 32, 8 bit, little-endian, data-type-policy=OVERRIDE, i-signal-type=PRIMITIVE, init-value=0, base-type=uint8, data-constr=c08_UInt_SNA_na  # Ereignis-Antwort / Response on Event
          signal ROE_5_RBTM_FR_ST3: start 40, 8 bit, little-endian, data-type-policy=OVERRIDE, i-signal-type=PRIMITIVE, init-value=0, base-type=uint8, data-constr=c08_UInt_SNA_na  # Ereignis-Antwort / Response on Event
          signal ROE_6_RBTM_FR_ST3: start 48, 8 bit, little-endian, data-type-policy=OVERRIDE, i-signal-type=PRIMITIVE, init-value=0, base-type=uint8, data-constr=c08_UInt_SNA_na  # Ereignis-Antwort / Response on Event
          signal ROE_7_RBTM_FR_ST3: start 56, 8 bit, little-endian, data-type-policy=OVERRIDE, i-signal-type=PRIMITIVE, init-value=0, base-type=uint8, data-constr=c08_UInt_SNA_na  # Ereignis-Antwort / Response on Event
          mapping ROE_RBTM_FR_ST3_3f1btonh6ivdn6ytgyuu9rtt1: i-signal-group=ROE_RBTM_FR_ST3_3f1btonh6ivdn6ytgyuu9rtt1, packing-byte-order=little-endian, transfer-property=TRIGGERED
      frame XCP8_Rs_RBTM_FR_ST3: id 0x18E1A508, from RBTM_FL, frame-length=8, variation-point=post-build-variant-condition{matching-criterion=Side, value=1}, can-addressing-mode=EXTENDED
        general purpose i pdu XCP8_Rs_RBTM_FR_ST3: category=XCP, length=8  # XCP-Anforderung / Extended calibration protocol response
      frame XCP8_Rq_RBTM_FR_ST3: id 0x18E1A509, to RBTM_FL, frame-length=8, variation-point=post-build-variant-condition{matching-criterion=Side, value=1}, can-addressing-mode=EXTENDED
        general purpose i pdu XCP8_Rq_RBTM_FR_ST3: category=XCP, length=8  # XCP-Anforderung / Extended calibration protocol request
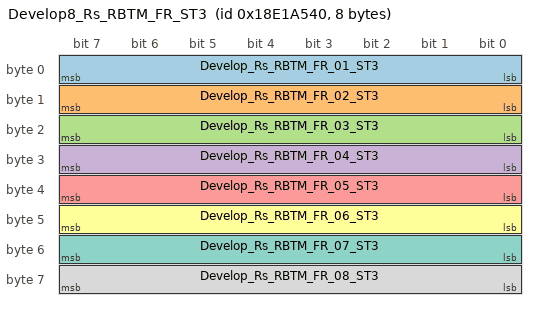
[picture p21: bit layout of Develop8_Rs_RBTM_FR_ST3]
      frame Develop8_Rs_RBTM_FR_ST3: id 0x18E1A540, from RBTM_FL, frame-length=8, variation-point=post-build-variant-condition{matching-criterion=Side, value=1}, can-addressing-mode=EXTENDED  # Development Response
        pdu Develop8_Rs_RBTM_FR_ST3: length=8, minimum-delay=0.02, transmission-mode-true-timing=event-controlled-timing=number-of-repetitions=0, unused-bit-pattern=0  # Development Response
          signal Develop_Rs_RBTM_FR_01_ST3: start 0, 8 bit, little-endian, data-type-policy=OVERRIDE, i-signal-type=PRIMITIVE, init-value=0, base-type=uint8, data-constr=c08_UInt_SNA_na  # Development Response
          signal Develop_Rs_RBTM_FR_02_ST3: start 8, 8 bit, little-endian, data-type-policy=OVERRIDE, i-signal-type=PRIMITIVE, init-value=0, base-type=uint8, data-constr=c08_UInt_SNA_na  # Development Response
          signal Develop_Rs_RBTM_FR_03_ST3: start 16, 8 bit, little-endian, data-type-policy=OVERRIDE, i-signal-type=PRIMITIVE, init-value=0, base-type=uint8, data-constr=c08_UInt_SNA_na  # Development Response
          signal Develop_Rs_RBTM_FR_04_ST3: start 24, 8 bit, little-endian, data-type-policy=OVERRIDE, i-signal-type=PRIMITIVE, init-value=0, base-type=uint8, data-constr=c08_UInt_SNA_na  # Development Response
          signal Develop_Rs_RBTM_FR_05_ST3: start 32, 8 bit, little-endian, data-type-policy=OVERRIDE, i-signal-type=PRIMITIVE, init-value=0, base-type=uint8, data-constr=c08_UInt_SNA_na  # Development Response
          signal Develop_Rs_RBTM_FR_06_ST3: start 40, 8 bit, little-endian, data-type-policy=OVERRIDE, i-signal-type=PRIMITIVE, init-value=0, base-type=uint8, data-constr=c08_UInt_SNA_na  # Development Response
          signal Develop_Rs_RBTM_FR_07_ST3: start 48, 8 bit, little-endian, data-type-policy=OVERRIDE, i-signal-type=PRIMITIVE, init-value=0, base-type=uint8, data-constr=c08_UInt_SNA_na  # Development Response
          signal Develop_Rs_RBTM_FR_08_ST3: start 56, 8 bit, little-endian, data-type-policy=OVERRIDE, i-signal-type=PRIMITIVE, init-value=0, base-type=uint8, data-constr=c08_UInt_SNA_na  # Development Response
          mapping Develop8_Rs_RBTM_FR_ST3_5t18pq0a13t698v0vsj7yvmmm: i-signal-group=Develop8_Rs_RBTM_FR_ST3_5t18pq0a13t698v0vsj7yvmmm, packing-byte-order=little-endian, transfer-property=TRIGGERED
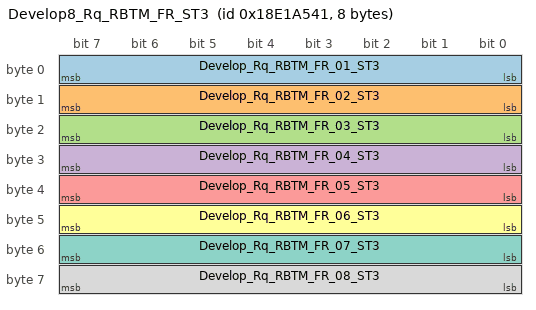
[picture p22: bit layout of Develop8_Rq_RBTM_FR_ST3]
      frame Develop8_Rq_RBTM_FR_ST3: id 0x18E1A541, to RBTM_FL, frame-length=8, variation-point=post-build-variant-condition{matching-criterion=Side, value=1}, can-addressing-mode=EXTENDED  # Development Request
        pdu Develop8_Rq_RBTM_FR_ST3: length=8, minimum-delay=0.02, transmission-mode-true-timing=event-controlled-timing=number-of-repetitions=0, unused-bit-pattern=0  # Development Request
          signal Develop_Rq_RBTM_FR_01_ST3: start 0, 8 bit, little-endian, data-type-policy=OVERRIDE, i-signal-type=PRIMITIVE, init-value=0, base-type=uint8, data-constr=c08_UInt_SNA_na, to RBTM_FL  # Development Request
          signal Develop_Rq_RBTM_FR_02_ST3: start 8, 8 bit, little-endian, data-type-policy=OVERRIDE, i-signal-type=PRIMITIVE, init-value=0, base-type=uint8, data-constr=c08_UInt_SNA_na, to RBTM_FL  # Development Request
          signal Develop_Rq_RBTM_FR_03_ST3: start 16, 8 bit, little-endian, data-type-policy=OVERRIDE, i-signal-type=PRIMITIVE, init-value=0, base-type=uint8, data-constr=c08_UInt_SNA_na, to RBTM_FL  # Development Request
          signal Develop_Rq_RBTM_FR_04_ST3: start 24, 8 bit, little-endian, data-type-policy=OVERRIDE, i-signal-type=PRIMITIVE, init-value=0, base-type=uint8, data-constr=c08_UInt_SNA_na, to RBTM_FL  # Development Request
          signal Develop_Rq_RBTM_FR_05_ST3: start 32, 8 bit, little-endian, data-type-policy=OVERRIDE, i-signal-type=PRIMITIVE, init-value=0, base-type=uint8, data-constr=c08_UInt_SNA_na, to RBTM_FL  # Development Request
          signal Develop_Rq_RBTM_FR_06_ST3: start 40, 8 bit, little-endian, data-type-policy=OVERRIDE, i-signal-type=PRIMITIVE, init-value=0, base-type=uint8, data-constr=c08_UInt_SNA_na, to RBTM_FL  # Development Request
          signal Develop_Rq_RBTM_FR_07_ST3: start 48, 8 bit, little-endian, data-type-policy=OVERRIDE, i-signal-type=PRIMITIVE, init-value=0, base-type=uint8, data-constr=c08_UInt_SNA_na, to RBTM_FL  # Development Request
          signal Develop_Rq_RBTM_FR_08_ST3: start 56, 8 bit, little-endian, data-type-policy=OVERRIDE, i-signal-type=PRIMITIVE, init-value=0, base-type=uint8, data-constr=c08_UInt_SNA_na, to RBTM_FL  # Development Request
          mapping Develop8_Rq_RBTM_FR_ST3_bcqj2sqez8u9spf5qxmu4a35u: i-signal-group=Develop8_Rq_RBTM_FR_ST3_bcqj2sqez8u9spf5qxmu4a35u, packing-byte-order=little-endian, transfer-property=TRIGGERED
      frame DIAG_RBTM_FR_03_ExtEth_RS_ST3: id 0x18E1A580, from RBTM_FL, frame-length=8, variation-point=post-build-variant-condition{matching-criterion=Side, value=1}, can-addressing-mode=EXTENDED  # Diagnoseanwort an ExtEth vonRBTM_FR / Diagnostic Response to ExtEth fromRBTM_FR
        n pdu DIAG_RBTM_FR_03_ExtEth_RS_ST3: length=8  # Diagnoseanwort an ExtEth vonRBTM_FR / Diagnostic Response to ExtEth fromRBTM_FR
      frame DIAG_RBTM_FR_03_ExtCAN_RS_ST3: id 0x18E1A581, from RBTM_FL, frame-length=8, variation-point=post-build-variant-condition{matching-criterion=Side, value=1}, can-addressing-mode=EXTENDED  # Diagnoseanwort an ExtCAN vonRBTM_FR / Diagnostic Response to ExtCAN fromRBTM_FR
        n pdu DIAG_RBTM_FR_03_ExtCAN_RS_ST3: length=8  # Diagnoseanwort an ExtCAN vonRBTM_FR / Diagnostic Response to ExtCAN fromRBTM_FR
      frame DIAG_RBTM_FR_03_IntEth_RS_ST3: id 0x18E1A585, from RBTM_FL, frame-length=8, variation-point=post-build-variant-condition{matching-criterion=Side, value=1}, can-addressing-mode=EXTENDED  # Diagnoseanwort an IntEth vonRBTM_FR / Diagnostic Response to IntEth fromRBTM_FR
        n pdu DIAG_RBTM_FR_03_IntEth_RS_ST3: length=8  # Diagnoseanwort an IntEth vonRBTM_FR / Diagnostic Response to IntEth fromRBTM_FR
      frame DIAG_RBTM_FR_03_ExtEth_RQ_ST3: id 0x18E1A588, to RBTM_FL, frame-length=8, variation-point=post-build-variant-condition{matching-criterion=Side, value=1}, can-addressing-mode=EXTENDED  # Diagnoseanfrage vom ExtEth fürRBTM_FR / Diagnostic Request from ExtEth forRBTM_FR
        n pdu DIAG_RBTM_FR_03_ExtEth_RQ_ST3: length=8  # Diagnoseanfrage vom ExtEth fürRBTM_FR / Diagnostic Request from ExtEth forRBTM_FR
      frame DIAG_RBTM_FR_03_ExtCAN_RQ_ST3: id 0x18E1A589, to RBTM_FL, frame-length=8, variation-point=post-build-variant-condition{matching-criterion=Side, value=1}, can-addressing-mode=EXTENDED  # Diagnoseanfrage vom ExtCAN fürRBTM_FR / Diagnostic Request from ExtCAN forRBTM_FR
        n pdu DIAG_RBTM_FR_03_ExtCAN_RQ_ST3: length=8  # Diagnoseanfrage vom ExtCAN fürRBTM_FR / Diagnostic Request from ExtCAN forRBTM_FR
      frame DIAG_RBTM_FR_03_IntEth_RQ_ST3: id 0x18E1A58D, to RBTM_FL, frame-length=8, variation-point=post-build-variant-condition{matching-criterion=Side, value=1}, can-addressing-mode=EXTENDED  # Diagnoseanfrage vom IntEth fürRBTM_FR / Diagnostic Request from IntEth forRBTM_FR
        n pdu DIAG_RBTM_FR_03_IntEth_RQ_ST3: length=8  # Diagnoseanfrage vom IntEth fürRBTM_FR / Diagnostic Request from IntEth forRBTM_FR
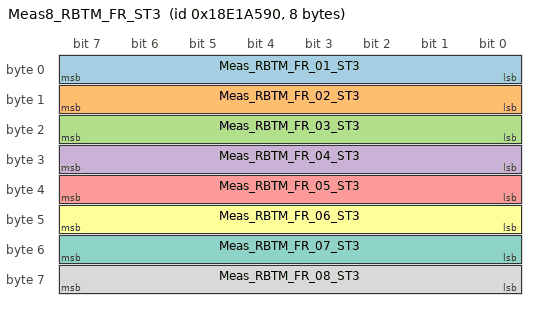
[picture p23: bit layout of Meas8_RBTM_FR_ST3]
      frame Meas8_RBTM_FR_ST3: id 0x18E1A590, from RBTM_FL, frame-length=8, variation-point=post-build-variant-condition{matching-criterion=Side, value=1}, can-addressing-mode=EXTENDED  # Messbotschaft / Measurement
        pdu Meas8_RBTM_FR_ST3: length=8, minimum-delay=0.02, transmission-mode-true-timing=event-controlled-timing=number-of-repetitions=0, unused-bit-pattern=0  # Messbotschaft / Measurement
          signal Meas_RBTM_FR_01_ST3: start 0, 8 bit, little-endian, data-type-policy=OVERRIDE, i-signal-type=PRIMITIVE, init-value=0, base-type=uint8, data-constr=c08_UInt_SNA_na  # Messsignal / Measurement
          signal Meas_RBTM_FR_02_ST3: start 8, 8 bit, little-endian, data-type-policy=OVERRIDE, i-signal-type=PRIMITIVE, init-value=0, base-type=uint8, data-constr=c08_UInt_SNA_na  # Messsignal / Measurement
          signal Meas_RBTM_FR_03_ST3: start 16, 8 bit, little-endian, data-type-policy=OVERRIDE, i-signal-type=PRIMITIVE, init-value=0, base-type=uint8, data-constr=c08_UInt_SNA_na  # Messsignal / Measurement
          signal Meas_RBTM_FR_04_ST3: start 24, 8 bit, little-endian, data-type-policy=OVERRIDE, i-signal-type=PRIMITIVE, init-value=0, base-type=uint8, data-constr=c08_UInt_SNA_na  # Messsignal / Measurement
          signal Meas_RBTM_FR_05_ST3: start 32, 8 bit, little-endian, data-type-policy=OVERRIDE, i-signal-type=PRIMITIVE, init-value=0, base-type=uint8, data-constr=c08_UInt_SNA_na  # Messsignal / Measurement
          signal Meas_RBTM_FR_06_ST3: start 40, 8 bit, little-endian, data-type-policy=OVERRIDE, i-signal-type=PRIMITIVE, init-value=0, base-type=uint8, data-constr=c08_UInt_SNA_na  # Messsignal / Measurement
          signal Meas_RBTM_FR_07_ST3: start 48, 8 bit, little-endian, data-type-policy=OVERRIDE, i-signal-type=PRIMITIVE, init-value=0, base-type=uint8, data-constr=c08_UInt_SNA_na  # Messsignal / Measurement
          signal Meas_RBTM_FR_08_ST3: start 56, 8 bit, little-endian, data-type-policy=OVERRIDE, i-signal-type=PRIMITIVE, init-value=0, base-type=uint8, data-constr=c08_UInt_SNA_na  # Messsignal / Measurement
          mapping Meas8_RBTM_FR_ST3_7ba3lhjy9fnhufd3n9dyw0p9p: i-signal-group=Meas8_RBTM_FR_ST3_7ba3lhjy9fnhufd3n9dyw0p9p, packing-byte-order=little-endian, transfer-property=TRIGGERED
      frame DIAG_RQ_GLOBAL_ExtEth_ST3: id 0x18EEF888, to RBTM_FL, frame-length=8, variation-point=post-build-variant-condition{matching-criterion=Side, value=1}, can-addressing-mode=EXTENDED  # Funktionaler Diagnose-Request vom Off-Board Tester (via Ethernet) / Functional Diagnostic Request from Off-Board Tester (via Ethernet)
        carries pdu DIAG_RQ_GLOBAL_ExtEth_ST3: packing-byte-order=little-endian, start-position=0
      frame DIAG_RQ_GLOBAL_ExtCAN_ST3: id 0x18EEF989, to RBTM_FL, frame-length=8, variation-point=post-build-variant-condition{matching-criterion=Side, value=1}, can-addressing-mode=EXTENDED  # Funktionaler Diagnose-Request vom Off-Board Tester (via CAN) / Functional Diagnostic Request from Off-Board Tester (via CAN)
        carries pdu DIAG_RQ_GLOBAL_ExtCAN_ST3: packing-byte-order=little-endian, start-position=0
      frame DIAG_RQ_GLOBAL_IntEth_ST3: id 0x18EF0D8D, to RBTM_FL, frame-length=8, variation-point=post-build-variant-condition{matching-criterion=Side, value=1}, can-addressing-mode=EXTENDED  # Funktionaler Diagnose-Request vom On-Board Tester (via Ethernet) / Functional Diagnostic Request from On-Board Tester (via Ethernet)
        carries pdu DIAG_RQ_GLOBAL_IntEth_ST3: packing-byte-order=little-endian, start-position=0
      pdu triggering Ign_Stat_ST3_c09z9xhxqu9sge34n30m1bi02: pdu=Ign_Stat_ST3, to RBTM_FL
      pdu triggering Impact2_ST3_tiwfvn1jg3r3k32jv8naa5uv: pdu=Impact2_ST3, to RBTM_FL
      pdu triggering ADAS_PROFILE_SHORT_ST3_2b0fjw1fp06jeg5egh8b4kpth: pdu=ADAS_PROFILE_SHORT_ST3_1, to RBTM_FL
      pdu triggering ADAS_PROFILE_SHORT_ST3_damkclk5wxjmwtfnpuuek3bsw: pdu=ADAS_PROFILE_SHORT_ST3_31, to RBTM_FL
      pdu triggering Bckl_Sw_Fx_Stat_ST3_76xqik47h3rgo3857pk44xg84: pdu=Bckl_Sw_Fx_Stat_ST3, to RBTM_FL
      pdu triggering ELC_Lvr_Stat_ST3_73cx1t6a1vhnmsct6284cefhl: pdu=ELC_Lvr_Stat_ST3, to RBTM_FL
      pdu triggering ADAS_PREDICTION_ST3_erehzbs0pl4hxv8mpjl431kqa: pdu=ADAS_PREDICTION_ST3_6, to RBTM_FL
      pdu triggering ADAS_PREDICTION_ST3_6yt0elilbhvsadvyfchfhcm9m: pdu=ADAS_PREDICTION_ST3_7, to RBTM_FL
      pdu triggering SDU_DIAG_GLOBAL_ExtCAN_RQ_BODY3_ST3_8cstdmc89wsdfjf9j8qpurnv7: pdu=SDU_DIAG_GLOBAL_ExtCAN_RQ_BODY3_ST3, to RBTM_FL
      pdu triggering SDU_DIAG_GLOBAL_ExtEth_RQ_BODY3_ST3_46vu0dellvbhrwu73svm0iujm: pdu=SDU_DIAG_GLOBAL_ExtEth_RQ_BODY3_ST3, to RBTM_FL
      pdu triggering SDU_DIAG_GLOBAL_IntEth_RQ_BODY3_ST3_8ovvy2nuzdnh7ctfte2ha89v0: pdu=SDU_DIAG_GLOBAL_IntEth_RQ_BODY3_ST3, to RBTM_FL
      pdu triggering SDU_DIAG_RBTM_FL_03_ExtCAN_RQ_BODY3_ST3_409r93yckv66zq8expyjwimow: pdu=SDU_DIAG_RBTM_FL_03_ExtCAN_RQ_BODY3_ST3, to RBTM_FL
      pdu triggering SDU_DIAG_RBTM_FL_03_ExtCAN_RS_BODY3_ST3_1tn6gg6s8kpstnzud0o5miep0: pdu=SDU_DIAG_RBTM_FL_03_ExtCAN_RS_BODY3_ST3, from RBTM_FL
      pdu triggering SDU_DIAG_RBTM_FL_03_ExtEth_RQ_BODY3_ST3_8m5gsdrjfimxpp431i790w9bs: pdu=SDU_DIAG_RBTM_FL_03_ExtEth_RQ_BODY3_ST3, to RBTM_FL
      pdu triggering SDU_DIAG_RBTM_FL_03_ExtEth_RS_BODY3_ST3_79mfryzmbm9853yotxd0bqg0t: pdu=SDU_DIAG_RBTM_FL_03_ExtEth_RS_BODY3_ST3, from RBTM_FL
      pdu triggering SDU_DIAG_RBTM_FL_03_IntEth_RQ_BODY3_ST3_71dk95mnu9pn5hfarc1crxvw8: pdu=SDU_DIAG_RBTM_FL_03_IntEth_RQ_BODY3_ST3, to RBTM_FL
      pdu triggering SDU_DIAG_RBTM_FL_03_IntEth_RS_BODY3_ST3_40gjkfbjquv8ettp0daf026bl: pdu=SDU_DIAG_RBTM_FL_03_IntEth_RS_BODY3_ST3, from RBTM_FL
      pdu triggering Ign_Stat_ST3_c09z9xhxqu9sge34n30m1bi02: pdu=Ign_Stat_ST3, to RBTM_FL
      pdu triggering Impact2_ST3_tiwfvn1jg3r3k32jv8naa5uv: pdu=Impact2_ST3, to RBTM_FL
      pdu triggering ADAS_PROFILE_SHORT_ST3_2b0fjw1fp06jeg5egh8b4kpth: pdu=ADAS_PROFILE_SHORT_ST3_1, to RBTM_FL
      pdu triggering ADAS_PROFILE_SHORT_ST3_damkclk5wxjmwtfnpuuek3bsw: pdu=ADAS_PROFILE_SHORT_ST3_31, to RBTM_FL
      pdu triggering Bckl_Sw_Fx_Stat_ST3_76xqik47h3rgo3857pk44xg84: pdu=Bckl_Sw_Fx_Stat_ST3, to RBTM_FL
      pdu triggering ELC_Lvr_Stat_ST3_73cx1t6a1vhnmsct6284cefhl: pdu=ELC_Lvr_Stat_ST3, to RBTM_FL
      pdu triggering ADAS_PREDICTION_ST3_erehzbs0pl4hxv8mpjl431kqa: pdu=ADAS_PREDICTION_ST3_6, to RBTM_FL
      pdu triggering ADAS_PREDICTION_ST3_6yt0elilbhvsadvyfchfhcm9m: pdu=ADAS_PREDICTION_ST3_7, to RBTM_FL
      pdu triggering SDU_DIAG_GLOBAL_ExtCAN_RQ_BODY3_ST3_8cstdmc89wsdfjf9j8qpurnv7: pdu=SDU_DIAG_GLOBAL_ExtCAN_RQ_BODY3_ST3, to RBTM_FL
      pdu triggering SDU_DIAG_GLOBAL_ExtEth_RQ_BODY3_ST3_46vu0dellvbhrwu73svm0iujm: pdu=SDU_DIAG_GLOBAL_ExtEth_RQ_BODY3_ST3, to RBTM_FL
      pdu triggering SDU_DIAG_GLOBAL_IntEth_RQ_BODY3_ST3_8ovvy2nuzdnh7ctfte2ha89v0: pdu=SDU_DIAG_GLOBAL_IntEth_RQ_BODY3_ST3, to RBTM_FL
      pdu triggering SDU_DIAG_RBTM_FR_03_ExtCAN_RQ_BODY3_ST3_5nu4bl3tlhe7jnp7bks8ybmdn: pdu=SDU_DIAG_RBTM_FR_03_ExtCAN_RQ_BODY3_ST3, to RBTM_FL
      pdu triggering SDU_DIAG_RBTM_FR_03_ExtCAN_RS_BODY3_ST3_6wkpaf3yq63v9w0gmle7njmco: pdu=SDU_DIAG_RBTM_FR_03_ExtCAN_RS_BODY3_ST3, from RBTM_FL
      pdu triggering SDU_DIAG_RBTM_FR_03_ExtEth_RQ_BODY3_ST3_616z8k8q77xlq08nachjg2711: pdu=SDU_DIAG_RBTM_FR_03_ExtEth_RQ_BODY3_ST3, to RBTM_FL
      pdu triggering SDU_DIAG_RBTM_FR_03_ExtEth_RS_BODY3_ST3_asa5mxpmex7axevgwhvzjiymg: pdu=SDU_DIAG_RBTM_FR_03_ExtEth_RS_BODY3_ST3, from RBTM_FL
      pdu triggering SDU_DIAG_RBTM_FR_03_IntEth_RQ_BODY3_ST3_acbgi2qrag7i9zbek8teytflj: pdu=SDU_DIAG_RBTM_FR_03_IntEth_RQ_BODY3_ST3, to RBTM_FL
      pdu triggering SDU_DIAG_RBTM_FR_03_IntEth_RS_BODY3_ST3_c66jductwjksm0ciybevo9xpc: pdu=SDU_DIAG_RBTM_FR_03_IntEth_RS_BODY3_ST3, from RBTM_FL
package /NmConfigs
  nm config NM_CONFIG: can-nm-cluster-coupling{coupled-cluster=BODY3, nm-busload-reduction-enabled=false, nm-immediate-restart-enabled=false}
    can nm cluster BODY3: communication-cluster=BODY3, nm-channel-id=3, nm-channel-sleep-master=false, nm-pnc-participation=true, nm-synchronizing-network=false, nm-busload-reduction-active=false, nm-cbv-position=0, nm-immediate-nm-cycle-time=0.02, nm-immediate-nm-transmissions=6, nm-message-timeout-time=0.5, nm-msg-cycle-time=1, nm-network-timeout=2.5, nm-remote-sleep-indication-time=2.5, nm-repeat-message-time=3, nm-wait-bus-sleep-time=1.5
      can nm node RBTM_FL_BODY3NMNODE: controller=RBTM_FL_BODY3, nm-if-ecu=RBTM_FL_CAN_NMECU, nm-passive-mode-enabled=false, rx-nm-pdu=NM_Dummy_ST3, tx-nm-pdu=NM_RBTM_FL_ST3, variation-point=post-build-variant-condition{matching-criterion=Side, value=0}, nm-msg-cycle-offset=0
      can nm node RBTM_FR_BODY3NMNODE: controller=RBTM_FR_BODY3, nm-if-ecu=RBTM_FR_CAN_NMECU, nm-passive-mode-enabled=false, rx-nm-pdu=NM_Dummy_ST3, tx-nm-pdu=NM_RBTM_FR_ST3, variation-point=post-build-variant-condition{matching-criterion=Side, value=1}, nm-msg-cycle-offset=0
    nm-if-ecus:
      nm ecu RBTM_FL_CAN_NMECU: ecu-instance=EcuInstances/RBTM_FL, nm-com-control-enabled=true, nm-node-detection-enabled=false, nm-node-id-enabled=false, nm-remote-sleep-ind-enabled=true, nm-repeat-msg-ind-enabled=false, nm-user-data-enabled=false, variation-point=post-build-variant-condition{matching-criterion=Side, value=0}
      nm ecu RBTM_FR_CAN_NMECU: ecu-instance=EcuInstances/RBTM_FL, nm-com-control-enabled=true, nm-node-detection-enabled=false, nm-node-id-enabled=false, nm-remote-sleep-ind-enabled=true, nm-repeat-msg-ind-enabled=false, nm-user-data-enabled=false, variation-point=post-build-variant-condition{matching-criterion=Side, value=1}
package /ISignalIPduGroups/BODY3/PKG_BODY3
  10 x i signal i pdu group:
    TxMess_RBTM_FL_BODY3: communication-direction=OUT, communication-mode=Measurement, i-signal-i-pdus=[Develop8_Rs_RBTM_FL_ST3, Meas8_RBTM_FL_ST3]
    RBTM_FL_BODY3_Tx_PNC_All_Active: communication-direction=OUT, communication-mode=Partial Network, i-signal-i-pdus=[BeltAdj_FL_Stat_ST3, ECU_Stat_RBTM_FL_ST3, RBTM_FL_Stat_ST3, RBTM_FL_Tens_ST3, ROE_RBTM_FL_ST3]
    RBTM_FL_BODY3_Tx_PNC_20: communication-direction=OUT, communication-mode=Partial Network, i-signal-i-pdus=[BeltAdj_FL_Stat_ST3, ECU_Stat_RBTM_FL_ST3, RBTM_FL_Stat_ST3, RBTM_FL_Tens_ST3, ROE_RBTM_FL_ST3]
    RBTM_FL_BODY3_Rx_PNC_All_Active: communication-direction=IN, communication-mode=Partial Network
      i-signal-i-pdus:
        ADAS_POSITION_ST3
        ADAS_PREDICTION_ST3_6
        ADAS_PREDICTION_ST3_7
        ADAS_PROFILE_SHORT_ST3_1
        ADAS_PROFILE_SHORT_ST3_31
        Bckl_Sw_Fx_Stat_ST3
        BeltAdj_FR_Stat_ST3
        BeltAdj_UI_Set_Rq_ST3
        BeltHdOvr_FL_State_ST3
        CLkS_Dr_State_ST3
        Develop8_Rq_RBTM_FL_ST3
        DI_OdoSpeedometer_ST3
        DIAG_Stat_ST3
        DPC_Md_Rq_ESP_d1_ST3
        ELC_Lvr_Stat_ST3
        EVC_CfgList_01_08_Pr5_ST3
        Ign_Stat_ST3
        Impact2_ST3
        Impact3_ST3
        NTG_Master_Navi_ST3
        PN14_Master_Stat1_ST3
        PresfAct_Adj_ST3
        PT4_PTCoor4_ST3
        PT4_PTCoor9_d1_BC_F_ST3
        PT4_PTCoor_DrvPosn_Gear_ST3
        RBTM_FR_Stat_ST3
        SBeltTens_SP_Lvl_ST3
        VSS_TP_Auth_ST3
        VSS_TP_RealTmOffset_ST3
        VSS_TP_SecTickCount_Lvl2_ST3
        VSS_TP_SharedSecret_ST3
        VSS_TP_VIN_ST3
    RBTM_FL_BODY3_Rx_PNC_20: communication-direction=IN, communication-mode=Partial Network
      i-signal-i-pdus:
        ADAS_POSITION_ST3
        ADAS_PREDICTION_ST3_6
        ADAS_PREDICTION_ST3_7
        ADAS_PROFILE_SHORT_ST3_1
        ADAS_PROFILE_SHORT_ST3_31
        Bckl_Sw_Fx_Stat_ST3
        BeltAdj_FR_Stat_ST3
        BeltAdj_UI_Set_Rq_ST3
        BeltHdOvr_FL_State_ST3
        CLkS_Dr_State_ST3
        Develop8_Rq_RBTM_FL_ST3
        DI_OdoSpeedometer_ST3
        DIAG_Stat_ST3
        DPC_Md_Rq_ESP_d1_ST3
        ELC_Lvr_Stat_ST3
        EVC_CfgList_01_08_Pr5_ST3
        Ign_Stat_ST3
        Impact2_ST3
        Impact3_ST3
        NTG_Master_Navi_ST3
        PN14_Master_Stat1_ST3
        PresfAct_Adj_ST3
        PT4_PTCoor4_ST3
        PT4_PTCoor9_d1_BC_F_ST3
        PT4_PTCoor_DrvPosn_Gear_ST3
        RBTM_FR_Stat_ST3
        SBeltTens_SP_Lvl_ST3
        VSS_TP_Auth_ST3
        VSS_TP_RealTmOffset_ST3
        VSS_TP_SecTickCount_Lvl2_ST3
        VSS_TP_SharedSecret_ST3
        VSS_TP_VIN_ST3
    TxMess_RBTM_FR_BODY3: communication-direction=OUT, communication-mode=Measurement, i-signal-i-pdus=[Develop8_Rs_RBTM_FR_ST3, Meas8_RBTM_FR_ST3]
    RBTM_FR_BODY3_Tx_PNC_All_Active: communication-direction=OUT, communication-mode=Partial Network, i-signal-i-pdus=[BeltAdj_FR_Stat_ST3, ECU_Stat_RBTM_FR_ST3, RBTM_FR_Stat_ST3, RBTM_FR_Tens_ST3, ROE_RBTM_FR_ST3]
    RBTM_FR_BODY3_Tx_PNC_20: communication-direction=OUT, communication-mode=Partial Network, i-signal-i-pdus=[BeltAdj_FR_Stat_ST3, ECU_Stat_RBTM_FR_ST3, RBTM_FR_Stat_ST3, RBTM_FR_Tens_ST3, ROE_RBTM_FR_ST3]
    RBTM_FR_BODY3_Rx_PNC_All_Active: communication-direction=IN, communication-mode=Partial Network
      i-signal-i-pdus:
        ADAS_POSITION_ST3
        ADAS_PREDICTION_ST3_6
        ADAS_PREDICTION_ST3_7
        ADAS_PROFILE_SHORT_ST3_1
        ADAS_PROFILE_SHORT_ST3_31
        Bckl_Sw_Fx_Stat_ST3
        BeltAdj_FL_Stat_ST3
        BeltAdj_UI_Set_Rq_ST3
        BeltHdOvr_FR_State_ST3
        CLkS_Dr_State_ST3
        Develop8_Rq_RBTM_FR_ST3
        DI_OdoSpeedometer_ST3
        DIAG_Stat_ST3
        DPC_Md_Rq_ESP_d1_ST3
        ELC_Lvr_Stat_ST3
        EVC_CfgList_01_08_Pr5_ST3
        Ign_Stat_ST3
        Impact2_ST3
        Impact3_ST3
        NTG_Master_Navi_ST3
        PN14_Master_Stat1_ST3
        PresfAct_Adj_ST3
        PT4_PTCoor4_ST3
        PT4_PTCoor9_d1_BC_F_ST3
        PT4_PTCoor_DrvPosn_Gear_ST3
        RBTM_FL_Stat_ST3
        SBeltTens_SP_Lvl_ST3
        VSS_TP_Auth_ST3
        VSS_TP_RealTmOffset_ST3
        VSS_TP_SecTickCount_Lvl2_ST3
        VSS_TP_SharedSecret_ST3
        VSS_TP_VIN_ST3
    RBTM_FR_BODY3_Rx_PNC_20: communication-direction=IN, communication-mode=Partial Network
      i-signal-i-pdus:
        ADAS_POSITION_ST3
        ADAS_PREDICTION_ST3_6
        ADAS_PREDICTION_ST3_7
        ADAS_PROFILE_SHORT_ST3_1
        ADAS_PROFILE_SHORT_ST3_31
        Bckl_Sw_Fx_Stat_ST3
        BeltAdj_FL_Stat_ST3
        BeltAdj_UI_Set_Rq_ST3
        BeltHdOvr_FR_State_ST3
        CLkS_Dr_State_ST3
        Develop8_Rq_RBTM_FR_ST3
        DI_OdoSpeedometer_ST3
        DIAG_Stat_ST3
        DPC_Md_Rq_ESP_d1_ST3
        ELC_Lvr_Stat_ST3
        EVC_CfgList_01_08_Pr5_ST3
        Ign_Stat_ST3
        Impact2_ST3
        Impact3_ST3
        NTG_Master_Navi_ST3
        PN14_Master_Stat1_ST3
        PresfAct_Adj_ST3
        PT4_PTCoor4_ST3
        PT4_PTCoor9_d1_BC_F_ST3
        PT4_PTCoor_DrvPosn_Gear_ST3
        RBTM_FL_Stat_ST3
        SBeltTens_SP_Lvl_ST3
        VSS_TP_Auth_ST3
        VSS_TP_RealTmOffset_ST3
        VSS_TP_SecTickCount_Lvl2_ST3
        VSS_TP_SharedSecret_ST3
        VSS_TP_VIN_ST3
package /TpConfigs/BODY3
  can tp config BODY3: communication-cluster=BODY3, can-tp-ecu=EcuInstances/RBTM_FL
    15 x can tp address:
      TPA_0ef8h: tp-address=3832
      TPA_0ef8h_1: tp-address=3832, tp-address-extension-value=1
      TPA_0ef8h_11: tp-address=3832, tp-address-extension-value=11
      TPA_0ef9h: tp-address=3833
      TPA_0ef9h_1: tp-address=3833, tp-address-extension-value=1
      TPA_0ef9h_11: tp-address=3833, tp-address-extension-value=11
      TPA_0f0dh: tp-address=3853
      TPA_0f0dh_1: tp-address=3853, tp-address-extension-value=1
      TPA_0f0dh_11: tp-address=3853, tp-address-extension-value=11
      TPA_11a4h: tp-address=4516, variation-point=post-build-variant-condition{matching-criterion=Side, value=0}
      TPA_eef8h: tp-address=61176
      TPA_eef9h: tp-address=61177
      TPA_ef0dh: tp-address=61197
      TPA_0441h: tp-address=1089
      TPA_11a5h: tp-address=4517, variation-point=post-build-variant-condition{matching-criterion=Side, value=1}
    9 x can tp channel, all with channel-id=3:
      BODY3_DIAG_GLOBAL_ExtCAN_RQ_BODY3_ST3: channel-mode=HALF-DUPLEX-MODE
      BODY3_DIAG_GLOBAL_ExtEth_RQ_BODY3_ST3: channel-mode=HALF-DUPLEX-MODE
      BODY3_DIAG_GLOBAL_IntEth_RQ_BODY3_ST3: channel-mode=HALF-DUPLEX-MODE
      BODY3_DIAG_RBTM_FL_03_ExtCAN_RQ_BODY3_ST3_DIAG_RBTM_FL_03_ExtCAN_RS_BODY3_ST3: channel-mode=FULL-DUPLEX-MODE, variation-point=post-build-variant-condition{matching-criterion=Side, value=0}
      BODY3_DIAG_RBTM_FL_03_ExtEth_RQ_BODY3_ST3_DIAG_RBTM_FL_03_ExtEth_RS_BODY3_ST3: channel-mode=FULL-DUPLEX-MODE, variation-point=post-build-variant-condition{matching-criterion=Side, value=0}
      BODY3_DIAG_RBTM_FL_03_IntEth_RQ_BODY3_ST3_DIAG_RBTM_FL_03_IntEth_RS_BODY3_ST3: channel-mode=FULL-DUPLEX-MODE, variation-point=post-build-variant-condition{matching-criterion=Side, value=0}
      BODY3_DIAG_RBTM_FR_03_ExtCAN_RQ_BODY3_ST3_DIAG_RBTM_FR_03_ExtCAN_RS_BODY3_ST3: channel-mode=FULL-DUPLEX-MODE, variation-point=post-build-variant-condition{matching-criterion=Side, value=1}
      BODY3_DIAG_RBTM_FR_03_ExtEth_RQ_BODY3_ST3_DIAG_RBTM_FR_03_ExtEth_RS_BODY3_ST3: channel-mode=FULL-DUPLEX-MODE, variation-point=post-build-variant-condition{matching-criterion=Side, value=1}
      BODY3_DIAG_RBTM_FR_03_IntEth_RQ_BODY3_ST3_DIAG_RBTM_FR_03_IntEth_RS_BODY3_ST3: channel-mode=FULL-DUPLEX-MODE, variation-point=post-build-variant-condition{matching-criterion=Side, value=1}
    can-tp-connection addressing-format=STANDARD, can-tp-channel=BODY3_DIAG_GLOBAL_ExtCAN_RQ_BODY3_ST3, data-pdu=DIAG_RQ_GLOBAL_ExtCAN_ST3, max-block-size=0, multicast=TPA_0441h, padding-activation=true, receiver=TPN_TPA_eef9h_862ksqtd1hod0l3skod9katd3, ta-type=FUNCTIONAL, tp-sdu=SDU_DIAG_GLOBAL_ExtCAN_RQ_BODY3_ST3, transmitter=TPN_TPA_0ef9h_eqq87shifgkbxdy47eurxh2s2, variation-point=post-build-variant-condition{matching-criterion=Side, value=0}:
      ident DIAG_GLOBAL_ExtCAN_RQ_BODY3_ST3
    can-tp-connection addressing-format=STANDARD, can-tp-channel=BODY3_DIAG_GLOBAL_ExtEth_RQ_BODY3_ST3, data-pdu=DIAG_RQ_GLOBAL_ExtEth_ST3, max-block-size=0, multicast=TPA_0441h, padding-activation=true, receiver=TPN_TPA_eef8h_c50izwa68r8egk4ro1yio0igi, ta-type=FUNCTIONAL, tp-sdu=SDU_DIAG_GLOBAL_ExtEth_RQ_BODY3_ST3, transmitter=TPN_TPA_0ef8h_cy6q2hs72he0ppe0qaib9wwe1, variation-point=post-build-variant-condition{matching-criterion=Side, value=0}:
      ident DIAG_GLOBAL_ExtEth_RQ_BODY3_ST3
    can-tp-connection addressing-format=STANDARD, can-tp-channel=BODY3_DIAG_GLOBAL_IntEth_RQ_BODY3_ST3, data-pdu=DIAG_RQ_GLOBAL_IntEth_ST3, max-block-size=0, multicast=TPA_0441h, padding-activation=true, receiver=TPN_TPA_ef0dh_ejbajff9hez4ky61mfjkg40qk, ta-type=FUNCTIONAL, tp-sdu=SDU_DIAG_GLOBAL_IntEth_RQ_BODY3_ST3, transmitter=TPN_TPA_0f0dh_8id06ke5ggt93boskdklwd5mp, variation-point=post-build-variant-condition{matching-criterion=Side, value=0}:
      ident DIAG_GLOBAL_IntEth_RQ_BODY3_ST3
    can-tp-connection addressing-format=STANDARD, can-tp-channel=BODY3_DIAG_RBTM_FL_03_ExtCAN_RQ_BODY3_ST3_DIAG_RBTM_FL_03_ExtCAN_RS_BODY3_ST3, data-pdu=DIAG_RBTM_FL_03_ExtCAN_RQ_ST3, flow-control-pdu=DIAG_RBTM_FL_03_ExtCAN_RS_ST3, max-block-size=0, padding-activation=true, receiver=TPN_TPA_11a4h_cdxmujzgd8e74d6v3mvhz623z, ta-type=PHYSICAL, tp-sdu=SDU_DIAG_RBTM_FL_03_ExtCAN_RQ_BODY3_ST3, transmitter=TPN_TPA_0ef9h_eqq87shifgkbxdy47eurxh2s2, variation-point=post-build-variant-condition{matching-criterion=Side, value=0}:
      ident DIAG_RBTM_FL_03_ExtCAN_RQ_BODY3_ST3
    can-tp-connection addressing-format=STANDARD, can-tp-channel=BODY3_DIAG_RBTM_FL_03_ExtCAN_RQ_BODY3_ST3_DIAG_RBTM_FL_03_ExtCAN_RS_BODY3_ST3, data-pdu=DIAG_RBTM_FL_03_ExtCAN_RS_ST3, flow-control-pdu=DIAG_RBTM_FL_03_ExtCAN_RQ_ST3, max-block-size=8, padding-activation=true, receiver=TPN_TPA_0ef9h_eqq87shifgkbxdy47eurxh2s2, ta-type=PHYSICAL, tp-sdu=SDU_DIAG_RBTM_FL_03_ExtCAN_RS_BODY3_ST3, transmitter=TPN_TPA_11a4h_cdxmujzgd8e74d6v3mvhz623z, variation-point=post-build-variant-condition{matching-criterion=Side, value=0}:
      ident DIAG_RBTM_FL_03_ExtCAN_RS_BODY3_ST3
    can-tp-connection addressing-format=STANDARD, can-tp-channel=BODY3_DIAG_RBTM_FL_03_ExtEth_RQ_BODY3_ST3_DIAG_RBTM_FL_03_ExtEth_RS_BODY3_ST3, data-pdu=DIAG_RBTM_FL_03_ExtEth_RQ_ST3, flow-control-pdu=DIAG_RBTM_FL_03_ExtEth_RS_ST3, max-block-size=0, padding-activation=true, receiver=TPN_TPA_11a4h_cdxmujzgd8e74d6v3mvhz623z, ta-type=PHYSICAL, tp-sdu=SDU_DIAG_RBTM_FL_03_ExtEth_RQ_BODY3_ST3, transmitter=TPN_TPA_0ef8h_cy6q2hs72he0ppe0qaib9wwe1, variation-point=post-build-variant-condition{matching-criterion=Side, value=0}:
      ident DIAG_RBTM_FL_03_ExtEth_RQ_BODY3_ST3
    can-tp-connection addressing-format=STANDARD, can-tp-channel=BODY3_DIAG_RBTM_FL_03_ExtEth_RQ_BODY3_ST3_DIAG_RBTM_FL_03_ExtEth_RS_BODY3_ST3, data-pdu=DIAG_RBTM_FL_03_ExtEth_RS_ST3, flow-control-pdu=DIAG_RBTM_FL_03_ExtEth_RQ_ST3, max-block-size=8, padding-activation=true, receiver=TPN_TPA_0ef8h_cy6q2hs72he0ppe0qaib9wwe1, ta-type=PHYSICAL, tp-sdu=SDU_DIAG_RBTM_FL_03_ExtEth_RS_BODY3_ST3, transmitter=TPN_TPA_11a4h_cdxmujzgd8e74d6v3mvhz623z, variation-point=post-build-variant-condition{matching-criterion=Side, value=0}:
      ident DIAG_RBTM_FL_03_ExtEth_RS_BODY3_ST3
    can-tp-connection addressing-format=STANDARD, can-tp-channel=BODY3_DIAG_RBTM_FL_03_IntEth_RQ_BODY3_ST3_DIAG_RBTM_FL_03_IntEth_RS_BODY3_ST3, data-pdu=DIAG_RBTM_FL_03_IntEth_RQ_ST3, flow-control-pdu=DIAG_RBTM_FL_03_IntEth_RS_ST3, max-block-size=0, padding-activation=true, receiver=TPN_TPA_11a4h_cdxmujzgd8e74d6v3mvhz623z, ta-type=PHYSICAL, tp-sdu=SDU_DIAG_RBTM_FL_03_IntEth_RQ_BODY3_ST3, transmitter=TPN_TPA_0f0dh_8id06ke5ggt93boskdklwd5mp, variation-point=post-build-variant-condition{matching-criterion=Side, value=0}:
      ident DIAG_RBTM_FL_03_IntEth_RQ_BODY3_ST3
    can-tp-connection addressing-format=STANDARD, can-tp-channel=BODY3_DIAG_RBTM_FL_03_IntEth_RQ_BODY3_ST3_DIAG_RBTM_FL_03_IntEth_RS_BODY3_ST3, data-pdu=DIAG_RBTM_FL_03_IntEth_RS_ST3, flow-control-pdu=DIAG_RBTM_FL_03_IntEth_RQ_ST3, max-block-size=8, padding-activation=true, receiver=TPN_TPA_0f0dh_8id06ke5ggt93boskdklwd5mp, ta-type=PHYSICAL, tp-sdu=SDU_DIAG_RBTM_FL_03_IntEth_RS_BODY3_ST3, transmitter=TPN_TPA_11a4h_cdxmujzgd8e74d6v3mvhz623z, variation-point=post-build-variant-condition{matching-criterion=Side, value=0}:
      ident DIAG_RBTM_FL_03_IntEth_RS_BODY3_ST3
    can-tp-connection addressing-format=STANDARD, can-tp-channel=BODY3_DIAG_GLOBAL_ExtCAN_RQ_BODY3_ST3, data-pdu=DIAG_RQ_GLOBAL_ExtCAN_ST3, max-block-size=0, multicast=TPA_0441h, padding-activation=true, receiver=TPN_TPA_eef9h_di5qeijlagkw3g04ozrfehv85, ta-type=FUNCTIONAL, tp-sdu=SDU_DIAG_GLOBAL_ExtCAN_RQ_BODY3_ST3, transmitter=TPN_TPA_0ef9h_eqq87shifgkbxdy47eurxh2s2, variation-point=post-build-variant-condition{matching-criterion=Side, value=1}:
      ident DIAG_GLOBAL_ExtCAN_RQ_BODY3_ST3
    can-tp-connection addressing-format=STANDARD, can-tp-channel=BODY3_DIAG_GLOBAL_ExtEth_RQ_BODY3_ST3, data-pdu=DIAG_RQ_GLOBAL_ExtEth_ST3, max-block-size=0, multicast=TPA_0441h, padding-activation=true, receiver=TPN_TPA_eef8h_6jy264ez1n1mg157eirzvpjty, ta-type=FUNCTIONAL, tp-sdu=SDU_DIAG_GLOBAL_ExtEth_RQ_BODY3_ST3, transmitter=TPN_TPA_0ef8h_cy6q2hs72he0ppe0qaib9wwe1, variation-point=post-build-variant-condition{matching-criterion=Side, value=1}:
      ident DIAG_GLOBAL_ExtEth_RQ_BODY3_ST3
    can-tp-connection addressing-format=STANDARD, can-tp-channel=BODY3_DIAG_GLOBAL_IntEth_RQ_BODY3_ST3, data-pdu=DIAG_RQ_GLOBAL_IntEth_ST3, max-block-size=0, multicast=TPA_0441h, padding-activation=true, receiver=TPN_TPA_ef0dh_4gu7vsjz03lvs6wbcz2lijs41, ta-type=FUNCTIONAL, tp-sdu=SDU_DIAG_GLOBAL_IntEth_RQ_BODY3_ST3, transmitter=TPN_TPA_0f0dh_8id06ke5ggt93boskdklwd5mp, variation-point=post-build-variant-condition{matching-criterion=Side, value=1}:
      ident DIAG_GLOBAL_IntEth_RQ_BODY3_ST3
    can-tp-connection addressing-format=STANDARD, can-tp-channel=BODY3_DIAG_RBTM_FR_03_ExtCAN_RQ_BODY3_ST3_DIAG_RBTM_FR_03_ExtCAN_RS_BODY3_ST3, data-pdu=DIAG_RBTM_FR_03_ExtCAN_RQ_ST3, flow-control-pdu=DIAG_RBTM_FR_03_ExtCAN_RS_ST3, max-block-size=0, padding-activation=true, receiver=TPN_TPA_11a5h_eettnb0k4tc9m3pezja3x4tfw, ta-type=PHYSICAL, tp-sdu=SDU_DIAG_RBTM_FR_03_ExtCAN_RQ_BODY3_ST3, transmitter=TPN_TPA_0ef9h_eqq87shifgkbxdy47eurxh2s2, variation-point=post-build-variant-condition{matching-criterion=Side, value=1}:
      ident DIAG_RBTM_FR_03_ExtCAN_RQ_BODY3_ST3
    can-tp-connection addressing-format=STANDARD, can-tp-channel=BODY3_DIAG_RBTM_FR_03_ExtCAN_RQ_BODY3_ST3_DIAG_RBTM_FR_03_ExtCAN_RS_BODY3_ST3, data-pdu=DIAG_RBTM_FR_03_ExtCAN_RS_ST3, flow-control-pdu=DIAG_RBTM_FR_03_ExtCAN_RQ_ST3, max-block-size=8, padding-activation=true, receiver=TPN_TPA_0ef9h_eqq87shifgkbxdy47eurxh2s2, ta-type=PHYSICAL, tp-sdu=SDU_DIAG_RBTM_FR_03_ExtCAN_RS_BODY3_ST3, transmitter=TPN_TPA_11a5h_eettnb0k4tc9m3pezja3x4tfw, variation-point=post-build-variant-condition{matching-criterion=Side, value=1}:
      ident DIAG_RBTM_FR_03_ExtCAN_RS_BODY3_ST3
    can-tp-connection addressing-format=STANDARD, can-tp-channel=BODY3_DIAG_RBTM_FR_03_ExtEth_RQ_BODY3_ST3_DIAG_RBTM_FR_03_ExtEth_RS_BODY3_ST3, data-pdu=DIAG_RBTM_FR_03_ExtEth_RQ_ST3, flow-control-pdu=DIAG_RBTM_FR_03_ExtEth_RS_ST3, max-block-size=0, padding-activation=true, receiver=TPN_TPA_11a5h_eettnb0k4tc9m3pezja3x4tfw, ta-type=PHYSICAL, tp-sdu=SDU_DIAG_RBTM_FR_03_ExtEth_RQ_BODY3_ST3, transmitter=TPN_TPA_0ef8h_cy6q2hs72he0ppe0qaib9wwe1, variation-point=post-build-variant-condition{matching-criterion=Side, value=1}:
      ident DIAG_RBTM_FR_03_ExtEth_RQ_BODY3_ST3
    can-tp-connection addressing-format=STANDARD, can-tp-channel=BODY3_DIAG_RBTM_FR_03_ExtEth_RQ_BODY3_ST3_DIAG_RBTM_FR_03_ExtEth_RS_BODY3_ST3, data-pdu=DIAG_RBTM_FR_03_ExtEth_RS_ST3, flow-control-pdu=DIAG_RBTM_FR_03_ExtEth_RQ_ST3, max-block-size=8, padding-activation=true, receiver=TPN_TPA_0ef8h_cy6q2hs72he0ppe0qaib9wwe1, ta-type=PHYSICAL, tp-sdu=SDU_DIAG_RBTM_FR_03_ExtEth_RS_BODY3_ST3, transmitter=TPN_TPA_11a5h_eettnb0k4tc9m3pezja3x4tfw, variation-point=post-build-variant-condition{matching-criterion=Side, value=1}:
      ident DIAG_RBTM_FR_03_ExtEth_RS_BODY3_ST3
    can-tp-connection addressing-format=STANDARD, can-tp-channel=BODY3_DIAG_RBTM_FR_03_IntEth_RQ_BODY3_ST3_DIAG_RBTM_FR_03_IntEth_RS_BODY3_ST3, data-pdu=DIAG_RBTM_FR_03_IntEth_RQ_ST3, flow-control-pdu=DIAG_RBTM_FR_03_IntEth_RS_ST3, max-block-size=0, padding-activation=true, receiver=TPN_TPA_11a5h_eettnb0k4tc9m3pezja3x4tfw, ta-type=PHYSICAL, tp-sdu=SDU_DIAG_RBTM_FR_03_IntEth_RQ_BODY3_ST3, transmitter=TPN_TPA_0f0dh_8id06ke5ggt93boskdklwd5mp, variation-point=post-build-variant-condition{matching-criterion=Side, value=1}:
      ident DIAG_RBTM_FR_03_IntEth_RQ_BODY3_ST3
    can-tp-connection addressing-format=STANDARD, can-tp-channel=BODY3_DIAG_RBTM_FR_03_IntEth_RQ_BODY3_ST3_DIAG_RBTM_FR_03_IntEth_RS_BODY3_ST3, data-pdu=DIAG_RBTM_FR_03_IntEth_RS_ST3, flow-control-pdu=DIAG_RBTM_FR_03_IntEth_RQ_ST3, max-block-size=8, padding-activation=true, receiver=TPN_TPA_0f0dh_8id06ke5ggt93boskdklwd5mp, ta-type=PHYSICAL, tp-sdu=SDU_DIAG_RBTM_FR_03_IntEth_RS_BODY3_ST3, transmitter=TPN_TPA_11a5h_eettnb0k4tc9m3pezja3x4tfw, variation-point=post-build-variant-condition{matching-criterion=Side, value=1}:
      ident DIAG_RBTM_FR_03_IntEth_RS_BODY3_ST3
    17 x can tp node:
      TPN_TPA_0ef8h_cy6q2hs72he0ppe0qaib9wwe1: st-min=0.01, tp-address=TPA_0ef8h
      TPN_TPA_0ef8h_1_8mlcsxeiapw7d4hdg7fjnxzlh: st-min=0, tp-address=TPA_0ef8h_1
      TPN_TPA_0ef8h_11_4vxvr4ji6ot3mlp07hoqmrdjf: st-min=0, tp-address=TPA_0ef8h_11
      TPN_TPA_0ef9h_eqq87shifgkbxdy47eurxh2s2: st-min=0.01, tp-address=TPA_0ef9h
      TPN_TPA_0ef9h_1_c6g4y6ts18ieuaj1ckuo33qeo: st-min=0, tp-address=TPA_0ef9h_1
      TPN_TPA_0ef9h_11_9bkfyhdloylessb0sl5w4mtla: st-min=0, tp-address=TPA_0ef9h_11
      TPN_TPA_0f0dh_8id06ke5ggt93boskdklwd5mp: st-min=0.01, tp-address=TPA_0f0dh
      TPN_TPA_0f0dh_1_7sgum5mz5qkj9uil4dy02re12: st-min=0, tp-address=TPA_0f0dh_1
      TPN_TPA_0f0dh_11_a0g7x807cggrnpgcolj919vd0: st-min=0, tp-address=TPA_0f0dh_11
      TPN_TPA_11a4h_cdxmujzgd8e74d6v3mvhz623z: connector=RBTM_FL_BODY3_8uqv9blm85ehm0msat385m76v, st-min=0.01, tp-address=TPA_11a4h, variation-point=post-build-variant-condition{matching-criterion=Side, value=0}
      TPN_TPA_eef8h_c50izwa68r8egk4ro1yio0igi: connector=RBTM_FL_BODY3_8uqv9blm85ehm0msat385m76v, tp-address=TPA_eef8h, variation-point=post-build-variant-condition{matching-criterion=Side, value=0}
      TPN_TPA_eef9h_862ksqtd1hod0l3skod9katd3: connector=RBTM_FL_BODY3_8uqv9blm85ehm0msat385m76v, tp-address=TPA_eef9h, variation-point=post-build-variant-condition{matching-criterion=Side, value=0}
      TPN_TPA_ef0dh_ejbajff9hez4ky61mfjkg40qk: connector=RBTM_FL_BODY3_8uqv9blm85ehm0msat385m76v, tp-address=TPA_ef0dh, variation-point=post-build-variant-condition{matching-criterion=Side, value=0}
      TPN_TPA_11a5h_eettnb0k4tc9m3pezja3x4tfw: connector=RBTM_FR_BODY3_4xwwtd59665s787n6ctawh7k8, st-min=0.01, tp-address=TPA_11a5h, variation-point=post-build-variant-condition{matching-criterion=Side, value=1}
      TPN_TPA_eef8h_6jy264ez1n1mg157eirzvpjty: connector=RBTM_FR_BODY3_4xwwtd59665s787n6ctawh7k8, tp-address=TPA_eef8h, variation-point=post-build-variant-condition{matching-criterion=Side, value=1}
      TPN_TPA_eef9h_di5qeijlagkw3g04ozrfehv85: connector=RBTM_FR_BODY3_4xwwtd59665s787n6ctawh7k8, tp-address=TPA_eef9h, variation-point=post-build-variant-condition{matching-criterion=Side, value=1}
      TPN_TPA_ef0dh_4gu7vsjz03lvs6wbcz2lijs41: connector=RBTM_FR_BODY3_4xwwtd59665s787n6ctawh7k8, tp-address=TPA_ef0dh, variation-point=post-build-variant-condition{matching-criterion=Side, value=1}
package /DiagnosticConnections/BODY3/PKG_BODY3
  6 x diagnostic connection:
    DIAG_RBTM_FL_03_ExtEth_RQ_BODY3_ST3_DIAG_RBTM_FL_03_ExtEth_RS_BODY3_ST3: functional-request=BODY3/DIAG_GLOBAL_ExtEth_RQ_BODY3_ST3, physical-request=DIAG_RBTM_FL_03_ExtEth_RQ_BODY3_ST3, response=DIAG_RBTM_FL_03_ExtEth_RS_BODY3_ST3
    DIAG_RBTM_FL_03_ExtCAN_RQ_BODY3_ST3_DIAG_RBTM_FL_03_ExtCAN_RS_BODY3_ST3: functional-request=BODY3/DIAG_GLOBAL_ExtCAN_RQ_BODY3_ST3, physical-request=DIAG_RBTM_FL_03_ExtCAN_RQ_BODY3_ST3, response=DIAG_RBTM_FL_03_ExtCAN_RS_BODY3_ST3
    DIAG_RBTM_FL_03_IntEth_RQ_BODY3_ST3_DIAG_RBTM_FL_03_IntEth_RS_BODY3_ST3: functional-request=BODY3/DIAG_GLOBAL_IntEth_RQ_BODY3_ST3, physical-request=DIAG_RBTM_FL_03_IntEth_RQ_BODY3_ST3, response=DIAG_RBTM_FL_03_IntEth_RS_BODY3_ST3
    DIAG_RBTM_FR_03_ExtEth_RQ_BODY3_ST3_DIAG_RBTM_FR_03_ExtEth_RS_BODY3_ST3: functional-request=BODY3/DIAG_GLOBAL_ExtEth_RQ_BODY3_ST3, physical-request=DIAG_RBTM_FR_03_ExtEth_RQ_BODY3_ST3, response=DIAG_RBTM_FR_03_ExtEth_RS_BODY3_ST3
    DIAG_RBTM_FR_03_ExtCAN_RQ_BODY3_ST3_DIAG_RBTM_FR_03_ExtCAN_RS_BODY3_ST3: functional-request=BODY3/DIAG_GLOBAL_ExtCAN_RQ_BODY3_ST3, physical-request=DIAG_RBTM_FR_03_ExtCAN_RQ_BODY3_ST3, response=DIAG_RBTM_FR_03_ExtCAN_RS_BODY3_ST3
    DIAG_RBTM_FR_03_IntEth_RQ_BODY3_ST3_DIAG_RBTM_FR_03_IntEth_RS_BODY3_ST3: functional-request=BODY3/DIAG_GLOBAL_IntEth_RQ_BODY3_ST3, physical-request=DIAG_RBTM_FR_03_IntEth_RQ_BODY3_ST3, response=DIAG_RBTM_FR_03_IntEth_RS_BODY3_ST3
package /GlobalTimeDomains
  global time domain GTD_BODY3_0:  # BODY3
    category=SYNCHRONIZED
    variation-point=post-build-variant-condition{matching-criterion=Side, value=0}
    communication-cluster=BODY3
    debounce-time=0.04
    domain-id=0
    global-time-domain-props=can-global-time-domain-props={fup-data-id-lists=[143, 78, 13, 199, 134, 69, 4, 190, 125, 60, 246, 181, 116, 51, 237, 172], sync-data-id-lists=[225, 102, 230, 107, 235, 112, 240, 117, 245, 122, 250, 127, 4, 132, 9, 137]}
    global-time-pdu-triggering=BODY3/GTS_Main_CAN_ST3_9b5uxoq4niufhpredyi37mn4e
    sync-loss-timeout=1.75
    global time can slave GTS_RBTM_FL_0: communication-connector=RBTM_FL_BODY3_8uqv9blm85ehm0msat385m76v, follow-up-timeout-value=0.25, time-leap-future-threshold=0.0017, time-leap-healing-counter=3, time-leap-past-threshold=0.0017, crc-validated=CRC-VALIDATED, sequence-counter-jump-width=3  # RBTM_FL
  global time domain GTD_BODY3_0:  # BODY3
    category=SYNCHRONIZED
    variation-point=post-build-variant-condition{matching-criterion=Side, value=1}
    communication-cluster=BODY3
    debounce-time=0.04
    domain-id=0
    global-time-domain-props=can-global-time-domain-props={fup-data-id-lists=[143, 78, 13, 199, 134, 69, 4, 190, 125, 60, 246, 181, 116, 51, 237, 172], sync-data-id-lists=[225, 102, 230, 107, 235, 112, 240, 117, 245, 122, 250, 127, 4, 132, 9, 137]}
    global-time-pdu-triggering=BODY3/GTS_Main_CAN_ST3_9b5uxoq4niufhpredyi37mn4e
    sync-loss-timeout=1.75
    global time can slave GTS_RBTM_FR_0: communication-connector=RBTM_FR_BODY3_4xwwtd59665s787n6ctawh7k8, follow-up-timeout-value=0.25, time-leap-future-threshold=0.0017, time-leap-healing-counter=3, time-leap-past-threshold=0.0017, crc-validated=CRC-VALIDATED, sequence-counter-jump-width=3  # RBTM_FR
